VERSION ""

NS_ :

BS_:

BU_: PowertrainControlModule AtmosphericSensor SafetyRestraintSystem2 Aftertreatment_2_GasOutlet Aftertreatment_2_GasIntake DieselParticulateFilterControl Turbocharger SafetyRestraintSystem1 CabDisplay2 Aftertreatment_1_GasOutlet Aftertreatment_1_GasIntake OnBoardDataLogger OffBoardDiagnosticTool2 OffBoardDiagnosticTool1 FileServer ParkingBrakeController SeatController2 FanDriveController SteeringColumnUnit CommunicationUnitRadio CommunicationUnitSatellite CommunicationUnitCellular PropulsionBatteryCharger ChassisController2 ChassisController1 EngineValveControl AuxiliaryHeater2 AuxiliaryHeater1 ClutchUnit RampControl InformationSystem1 SuspensionSystemController2 OilSensor VehicleDynamicStability ExhaustEmissionController TransmissionDisplay2 TransmissionDisplay1 ClimateControl2 WaterPumpController RearAxleSteeringController LightingOperatorControl SeatController1 IgnitionController2 IgnitionController1 TirePressureController CabController2 CabController1 PneumaticSystemController SuspensionSystemController1 HydraulicPumpController EnduranceBrakingSystem RetarderExhaustEngine2 OnBoardDiagnosticUnit HeadwayController RetarderExhaustEngine1 CabDisplay1 ManagementComputer VirtualTerminal OffVehicleGateway PowerTakeOffFront HitchControl AuxiliaryValveControl BodyController TractorTrailerBridge1 StarterSystem ElectricalSystem VehicleSecurity VehicleNavigation AerodynamicControl ElectricalChargingSystem ClimateControl1 TripRecorder InstrumentCluster SuspensionDriveAxle2 SuspensionDriveAxle1 SuspensionSteerAxle SteeringController FuelSystem CruiseControl RetarderDriveline RetarderEngine BrakesDriveAxle2 BrakesDriveAxle1 BrakesSystemController BrakesSteerAxle AxleDrive2 AxleDrive1 AxleSteering PowerTakeOff ShiftConsoleSecondary ShiftConsolePrimary Transmission2 Transmission1 Engine2 Engine1

BO_ 2364544766 CCS: 8 Vector__XXX
 SG_ EngCyl24CombustionStatus : 46|2@1+ (1,0) [0|3] "" Vector__XXX
 SG_ EngCyl23CombustionStatus : 44|2@1+ (1,0) [0|3] "" Vector__XXX
 SG_ EngCyl22CombustionStatus : 42|2@1+ (1,0) [0|3] "" Vector__XXX
 SG_ EngCyl21CombustionStatus : 40|2@1+ (1,0) [0|3] "" Vector__XXX
 SG_ EngCyl20CombustionStatus : 38|2@1+ (1,0) [0|3] "" Vector__XXX
 SG_ EngCyl19CombustionStatus : 36|2@1+ (1,0) [0|3] "" Vector__XXX
 SG_ EngCyl18CombustionStatus : 34|2@1+ (1,0) [0|3] "" Vector__XXX
 SG_ EngCyl17CombustionStatus : 32|2@1+ (1,0) [0|3] "" Vector__XXX
 SG_ EngCyl16CombustionStatus : 30|2@1+ (1,0) [0|3] "" Vector__XXX
 SG_ EngCyl15CombustionStatus : 28|2@1+ (1,0) [0|3] "" Vector__XXX
 SG_ EngCyl14CombustionStatus : 26|2@1+ (1,0) [0|3] "" Vector__XXX
 SG_ EngCyl13CombustionStatus : 24|2@1+ (1,0) [0|3] "" Vector__XXX
 SG_ EngCyl12CombustionStatus : 22|2@1+ (1,0) [0|3] "" Vector__XXX
 SG_ EngCyl11CombustionStatus : 20|2@1+ (1,0) [0|3] "" Vector__XXX
 SG_ EngCyl10CombustionStatus : 18|2@1+ (1,0) [0|3] "" Vector__XXX
 SG_ EngCyl9CombustionStatus : 16|2@1+ (1,0) [0|3] "" Vector__XXX
 SG_ EngCyl8CombustionStatus : 14|2@1+ (1,0) [0|3] "" Vector__XXX
 SG_ EngCyl7CombustionStatus : 12|2@1+ (1,0) [0|3] "" Vector__XXX
 SG_ EngCyl6CombustionStatus : 10|2@1+ (1,0) [0|3] "" Vector__XXX
 SG_ EngCyl5CombustionStatus : 8|2@1+ (1,0) [0|3] "" Vector__XXX
 SG_ EngCyl4CombustionStatus : 6|2@1+ (1,0) [0|3] "" Vector__XXX
 SG_ EngCyl3CombustionStatus : 4|2@1+ (1,0) [0|3] "" Vector__XXX
 SG_ EngCyl2CombustionStatus : 2|2@1+ (1,0) [0|3] "" Vector__XXX
 SG_ EngCyl1CombustionStatus : 0|2@1+ (1,0) [0|3] "" Vector__XXX

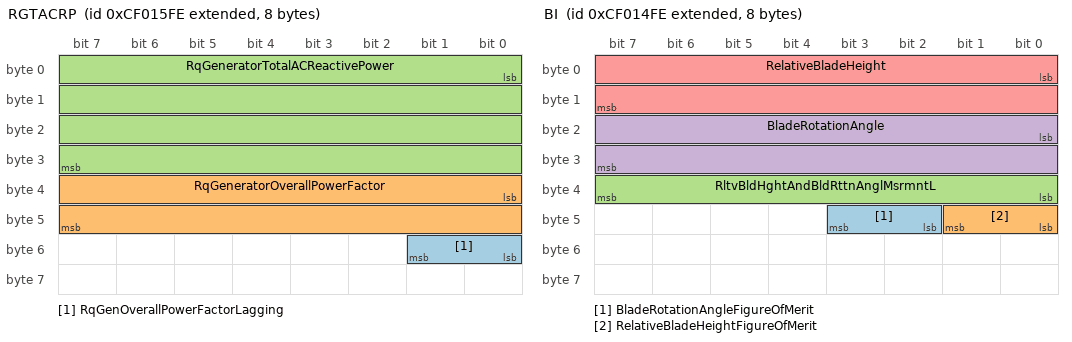
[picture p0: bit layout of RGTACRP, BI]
BO_ 2364544510 RGTACRP: 8 Vector__XXX
 SG_ RqGenOverallPowerFactorLagging : 48|2@1+ (1,0) [0|3] "" Vector__XXX
 SG_ RqGeneratorOverallPowerFactor : 32|16@1+ (6.103515625E-005,-1) [-1|1] "" Vector__XXX
 SG_ RqGeneratorTotalACReactivePower : 0|32@1+ (1,-2000000000) [-2000000000|2211081215] "VA" Vector__XXX

BO_ 2364544254 BI: 8 Vector__XXX
 SG_ BladeRotationAngleFigureOfMerit : 42|2@1+ (1,0) [0|3] "" Vector__XXX
 SG_ RelativeBladeHeightFigureOfMerit : 40|2@1+ (1,0) [0|3] "" Vector__XXX
 SG_ RltvBldHghtAndBldRttnAnglMsrmntL : 32|8@1+ (0.5,0) [0|125] "ms" Vector__XXX
 SG_ BladeRotationAngle : 16|16@1+ (0.0078125,-200) [-200|301.9921875] "deg" Vector__XXX
 SG_ RelativeBladeHeight : 0|16@1+ (0.1,-3200) [-3200|3225.5] "mm" Vector__XXX

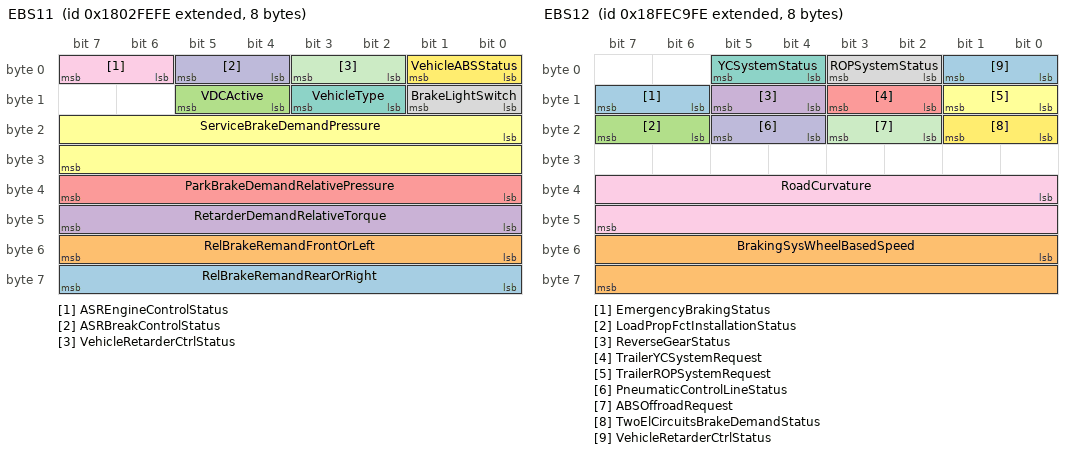
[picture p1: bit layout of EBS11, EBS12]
BO_ 2550333182 EBS11: 8 Vector__XXX
 SG_ RelBrakeRemandRearOrRight : 56|8@1+ (0.4,0) [0|100] "%" Vector__XXX
 SG_ RelBrakeRemandFrontOrLeft : 48|8@1+ (0.4,0) [0|100] "%" Vector__XXX
 SG_ VDCActive : 12|2@1+ (1,0) [0|3] "" Vector__XXX
 SG_ RetarderDemandRelativeTorque : 40|8@1+ (1,-125) [-125|125] "%" Vector__XXX
 SG_ ParkBrakeDemandRelativePressure : 32|8@1+ (0.4,0) [0|100] "%" Vector__XXX
 SG_ ServiceBrakeDemandPressure : 16|16@1+ (0.01953125,0) [0|1255] "kPa" Vector__XXX
 SG_ VehicleType : 10|2@1+ (1,0) [0|3] "" Vector__XXX
 SG_ BrakeLightSwitch : 8|2@1+ (1,0) [0|3] "" Vector__XXX
 SG_ ASREngineControlStatus : 6|2@1+ (1,0) [0|3] "" Vector__XXX
 SG_ ASRBreakControlStatus : 4|2@1+ (1,0) [0|3] "" Vector__XXX
 SG_ VehicleRetarderCtrlStatus : 2|2@1+ (1,0) [0|3] "" Vector__XXX
 SG_ VehicleABSStatus : 0|2@1+ (1,0) [0|1] "" Vector__XXX

BO_ 2566834686 EBS12: 8 Vector__XXX
 SG_ EmergencyBrakingStatus : 14|2@1+ (1,0) [0|3] "" Vector__XXX
 SG_ BrakingSysWheelBasedSpeed : 48|16@1+ (0.00390625,0) [0|250] "km/h" Vector__XXX
 SG_ LoadPropFctInstallationStatus : 22|2@1+ (1,0) [0|3] "" Vector__XXX
 SG_ ReverseGearStatus : 12|2@1+ (1,0) [0|3] "" Vector__XXX
 SG_ TrailerYCSystemRequest : 10|2@1+ (1,0) [0|3] "" Vector__XXX
 SG_ TrailerROPSystemRequest : 8|2@1+ (1,0) [0|3] "" Vector__XXX
 SG_ YCSystemStatus : 4|2@1+ (1,0) [0|3] "" Vector__XXX
 SG_ ROPSystemStatus : 2|2@1+ (1,0) [0|3] "" Vector__XXX
 SG_ RoadCurvature : 32|16@1+ (0.0078125,-250) [-250|251.9921875] "1/km" Vector__XXX
 SG_ PneumaticControlLineStatus : 20|2@1+ (1,0) [0|1] "" Vector__XXX
 SG_ ABSOffroadRequest : 18|2@1+ (1,0) [0|1] "" Vector__XXX
 SG_ TwoElCircuitsBrakeDemandStatus : 16|2@1+ (1,0) [0|1] "" Vector__XXX
 SG_ VehicleRetarderCtrlStatus : 0|2@1+ (1,0) [0|3] "" Vector__XXX

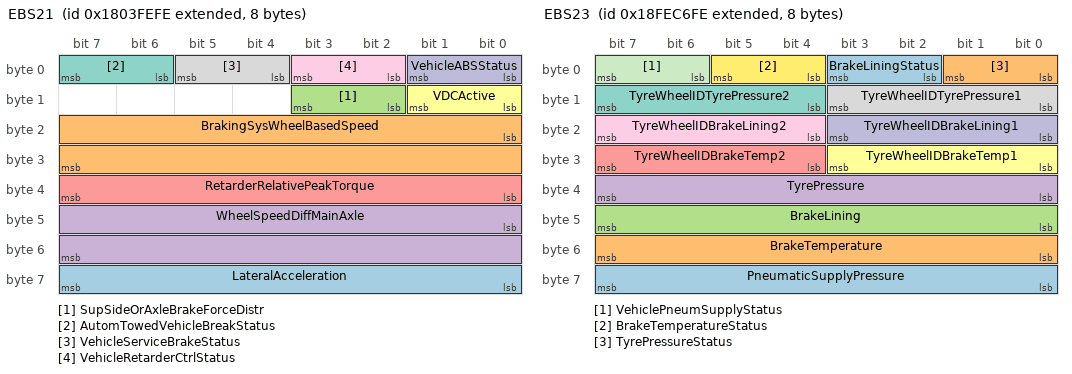
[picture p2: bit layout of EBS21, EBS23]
BO_ 2550398718 EBS21: 8 Vector__XXX
 SG_ LateralAcceleration : 56|8@1+ (0.1,-12.5) [-12.5|12.5] "m/s" Vector__XXX
 SG_ BrakingSysWheelBasedSpeed : 16|16@1+ (0.00390625,0) [0|250] "km/h" Vector__XXX
 SG_ SupSideOrAxleBrakeForceDistr : 10|2@1+ (1,0) [0|3] "" Vector__XXX
 SG_ WheelSpeedDiffMainAxle : 40|16@1+ (0.00390625,-125) [-125|125] "km/hr" Vector__XXX
 SG_ RetarderRelativePeakTorque : 32|8@1+ (1,-125) [-125|125] "%" Vector__XXX
 SG_ VDCActive : 8|2@1+ (1,0) [0|1] "" Vector__XXX
 SG_ AutomTowedVehicleBreakStatus : 6|2@1+ (1,0) [0|1] "" Vector__XXX
 SG_ VehicleServiceBrakeStatus : 4|2@1+ (1,0) [0|1] "" Vector__XXX
 SG_ VehicleRetarderCtrlStatus : 2|2@1+ (1,0) [0|3] "" Vector__XXX
 SG_ VehicleABSStatus : 0|2@1+ (1,0) [0|1] "" Vector__XXX

BO_ 2566833406 EBS22: 8 Vector__XXX
 SG_ BrakingViaElectrCtrlLineSupport : 30|2@1+ (1,0) [0|3] "" Vector__XXX
 SG_ StopLampsRequest : 28|2@1+ (1,0) [0|3] "" Vector__XXX
 SG_ ReferenceRetarderTorque : 48|16@1+ (1,0) [0|64255] "Nm" Vector__XXX
 SG_ AxleLoadSum : 32|16@1+ (2,0) [0|128510] "kg" Vector__XXX
 SG_ SupplyLineBraking : 26|2@1+ (1,0) [0|1] "" Vector__XXX
 SG_ LoadingRampApprAssistStatus : 24|2@1+ (1,0) [0|1] "" Vector__XXX
 SG_ SpringBrakeStatus : 22|2@1+ (1,0) [0|1] "" Vector__XXX
 SG_ ElectrLoadPropFuncInstalStatus : 18|2@1+ (1,0) [0|1] "" Vector__XXX
 SG_ SpringBrakeInstallationStatus : 16|2@1+ (1,0) [0|1] "" Vector__XXX
 SG_ VehicleType : 20|2@1+ (1,0) [0|3] "" Vector__XXX
 SG_ ElectSupplyOfNonBrakingSysStatus : 14|2@1+ (1,0) [0|1] "" Vector__XXX
 SG_ AmberWarningSignalReq : 12|2@1+ (1,0) [0|1] "" Vector__XXX
 SG_ RedWarningSignalRequest : 10|2@1+ (1,0) [0|1] "" Vector__XXX
 SG_ VehicleElectrSupplyStatus : 8|2@1+ (1,0) [0|1] "" Vector__XXX
 SG_ AutomTowedVehicleBreakStatus : 6|2@1+ (1,0) [0|1] "" Vector__XXX
 SG_ VehicleServiceBrakeStatus : 4|2@1+ (1,0) [0|1] "" Vector__XXX
 SG_ VehicleRetarderCtrlStatus : 2|2@1+ (1,0) [0|3] "" Vector__XXX
 SG_ VehicleABSStatus : 0|2@1+ (1,0) [0|1] "" Vector__XXX

BO_ 2566833918 EBS23: 8 Vector__XXX
 SG_ PneumaticSupplyPressure : 56|8@1+ (5,0) [0|1250] "kPa" Vector__XXX
 SG_ BrakeTemperature : 48|8@1+ (10,0) [0|2500] "°C" Vector__XXX
 SG_ BrakeLining : 40|8@1+ (0.4,0) [0|100] "%" Vector__XXX
 SG_ TyrePressure : 32|8@1+ (10,0) [0|2500] "kPa" Vector__XXX
 SG_ TyreWheelIDBrakeTemp2 : 28|4@1+ (1,0) [0|15] "" Vector__XXX
 SG_ TyreWheelIDBrakeTemp1 : 24|4@1+ (1,0) [0|15] "" Vector__XXX
 SG_ TyreWheelIDTyrePressure2 : 12|4@1+ (1,0) [0|15] "" Vector__XXX
 SG_ TyreWheelIDTyrePressure1 : 8|4@1+ (1,0) [0|15] "" Vector__XXX
 SG_ TyreWheelIDBrakeLining2 : 20|4@1+ (1,0) [0|15] "" Vector__XXX
 SG_ TyreWheelIDBrakeLining1 : 16|4@1+ (1,0) [0|15] "" Vector__XXX
 SG_ VehiclePneumSupplyStatus : 6|2@1+ (1,0) [0|1] "" Vector__XXX
 SG_ BrakeTemperatureStatus : 4|2@1+ (1,0) [0|1] "" Vector__XXX
 SG_ BrakeLiningStatus : 2|2@1+ (1,0) [0|1] "" Vector__XXX
 SG_ TyrePressureStatus : 0|2@1+ (1,0) [0|1] "" Vector__XXX

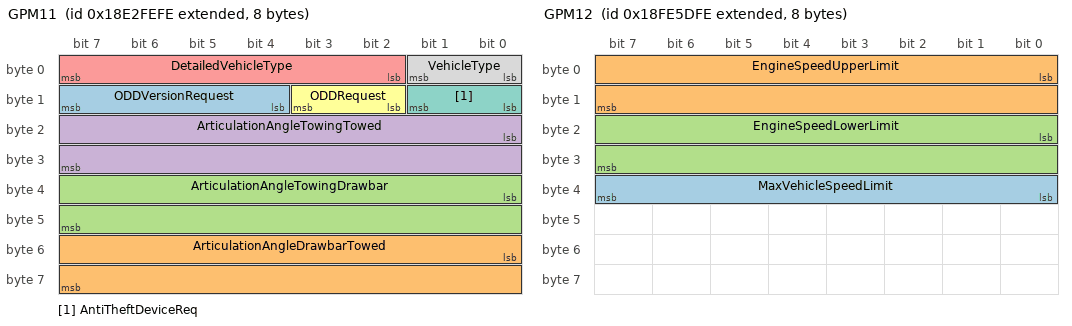
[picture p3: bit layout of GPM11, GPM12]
BO_ 2565013246 GPM11: 8 Vector__XXX
 SG_ ODDVersionRequest : 12|4@1+ (1,0) [0|15] "" Vector__XXX
 SG_ ArticulationAngleDrawbarTowed : 48|16@1+ (0.00390625,-125) [-125|125] "°" Vector__XXX
 SG_ ArticulationAngleTowingDrawbar : 32|16@1+ (0.00390625,-125) [-125|125] "°" Vector__XXX
 SG_ ArticulationAngleTowingTowed : 16|16@1+ (0.00390625,-125) [-125|125] "°" Vector__XXX
 SG_ DetailedVehicleType : 2|6@1+ (1,0) [0|63] "" Vector__XXX
 SG_ ODDRequest : 10|2@1+ (1,0) [0|3] "" Vector__XXX
 SG_ AntiTheftDeviceReq : 8|2@1+ (1,0) [0|3] "" Vector__XXX
 SG_ VehicleType : 0|2@1+ (1,0) [0|3] "" Vector__XXX

BO_ 2566807038 GPM12: 8 Vector__XXX
 SG_ MaxVehicleSpeedLimit : 32|8@1+ (1,0) [0|250] "km/h" Vector__XXX
 SG_ EngineSpeedUpperLimit : 0|16@1+ (0.125,0) [0|8031.875] "rpm" Vector__XXX
 SG_ EngineSpeedLowerLimit : 16|16@1+ (0.125,0) [0|8191.875] "rpm" Vector__XXX

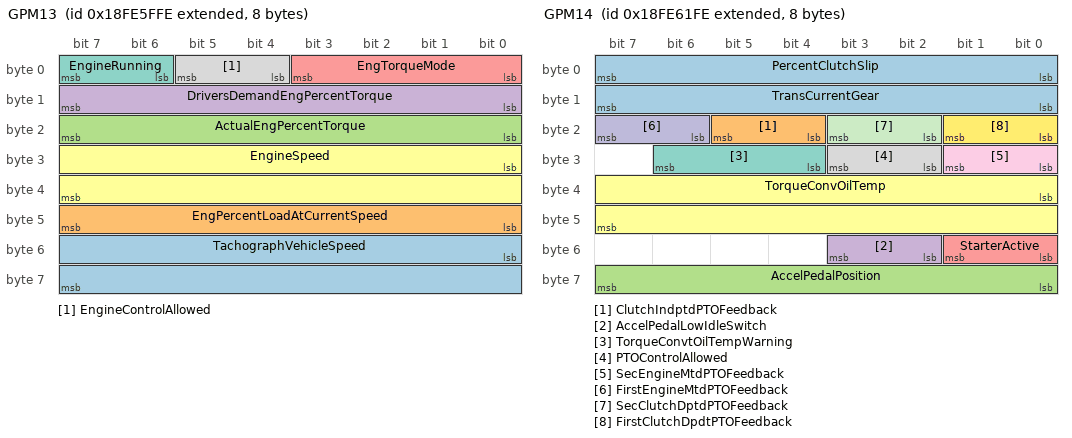
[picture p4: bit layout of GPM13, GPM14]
BO_ 2566807550 GPM13: 8 Vector__XXX
 SG_ TachographVehicleSpeed : 48|16@1+ (0.00390625,0) [0|250.99609375] "km/h" Vector__XXX
 SG_ EngPercentLoadAtCurrentSpeed : 40|8@1+ (1,0) [0|125] "%" Vector__XXX
 SG_ ActualEngPercentTorque : 16|8@1+ (1,-125) [0|125] "%" Vector__XXX
 SG_ DriversDemandEngPercentTorque : 8|8@1+ (1,-125) [0|125] "%" Vector__XXX
 SG_ EngTorqueMode : 0|4@1+ (1,0) [0|15] "" Vector__XXX
 SG_ EngineSpeed : 24|16@1+ (0.125,0) [0|8031.88] "rpm" Vector__XXX
 SG_ EngineRunning : 6|2@1+ (1,0) [0|1] "" Vector__XXX
 SG_ EngineControlAllowed : 4|2@1+ (1,0) [0|1] "" Vector__XXX

BO_ 2566808062 GPM14: 8 Vector__XXX
 SG_ TransCurrentGear : 8|8@1+ (1,-125) [-125|125] "" Vector__XXX
 SG_ ClutchIndptdPTOFeedback : 20|2@1+ (1,0) [0|1] "" Vector__XXX
 SG_ AccelPedalPosition : 56|8@1+ (0.4,0) [0|100] "%" Vector__XXX
 SG_ AccelPedalLowIdleSwitch : 50|2@1+ (1,0) [0|1] "" Vector__XXX
 SG_ StarterActive : 48|2@1+ (1,0) [0|1] "" Vector__XXX
 SG_ TorqueConvOilTemp : 32|16@1+ (0.03125,-273) [-273|1735] "°C" Vector__XXX
 SG_ TorqueConvtOilTempWarning : 28|3@1+ (1,0) [0|2] "" Vector__XXX
 SG_ PTOControlAllowed : 26|2@1+ (1,0) [0|1] "" Vector__XXX
 SG_ SecEngineMtdPTOFeedback : 24|2@1+ (1,0) [0|1] "" Vector__XXX
 SG_ FirstEngineMtdPTOFeedback : 22|2@1+ (1,0) [0|1] "" Vector__XXX
 SG_ SecClutchDptdPTOFeedback : 18|2@1+ (1,0) [0|1] "" Vector__XXX
 SG_ FirstClutchDpdtPTOFeedback : 16|2@1+ (1,0) [0|1] "" Vector__XXX
 SG_ PercentClutchSlip : 0|8@1+ (0.4,0) [0|100] "%" Vector__XXX

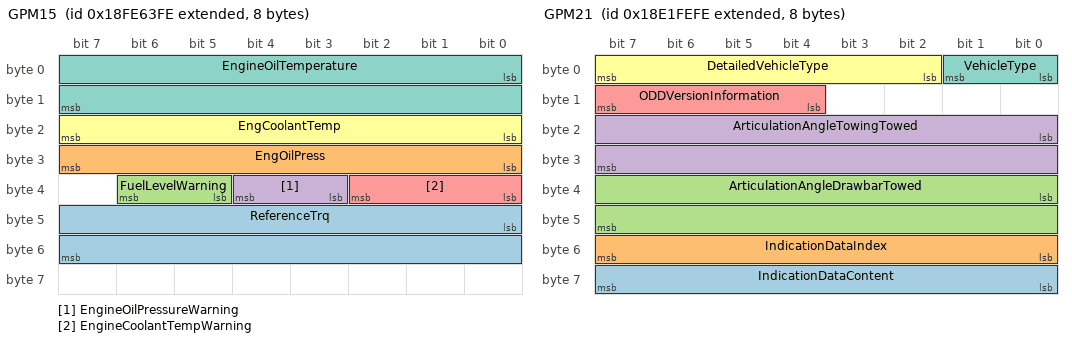
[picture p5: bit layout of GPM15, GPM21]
BO_ 2566808574 GPM15: 8 Vector__XXX
 SG_ ReferenceTrq : 40|16@1+ (1,0) [0|64255] "Nm" Vector__XXX
 SG_ EngOilPress : 24|8@1+ (4,0) [0|1000] "kPa" Vector__XXX
 SG_ FuelLevelWarning : 37|2@1+ (1,0) [0|1] "" Vector__XXX
 SG_ EngineOilPressureWarning : 35|2@1+ (1,0) [0|1] "" Vector__XXX
 SG_ EngineCoolantTempWarning : 32|3@1+ (1,0) [0|2] "" Vector__XXX
 SG_ EngCoolantTemp : 16|8@1+ (1,-40) [-40|210] "°C" Vector__XXX
 SG_ EngineOilTemperature : 0|16@1+ (0.03125,-273) [-273|1735] "°C" Vector__XXX

BO_ 2566809086 GPM16: 8 Vector__XXX
 SG_ AmbientAirTemp : 0|16@1+ (0.03125,-273) [-273|1734.96875] "°C" Vector__XXX

BO_ 2564947710 GPM21: 8 Vector__XXX
 SG_ IndicationDataContent : 56|8@1+ (1,0) [0|1] "" Vector__XXX
 SG_ IndicationDataIndex : 48|8@1+ (1,0) [0|16] "" Vector__XXX
 SG_ ArticulationAngleDrawbarTowed : 32|16@1+ (0.00390625,-125) [-125|125] "°" Vector__XXX
 SG_ ArticulationAngleTowingTowed : 16|16@1+ (0.00390625,-125) [-125|125] "°" Vector__XXX
 SG_ ODDVersionInformation : 12|4@1+ (1,0) [0|15] "" Vector__XXX
 SG_ DetailedVehicleType : 2|6@1+ (1,0) [0|63] "" Vector__XXX
 SG_ VehicleType : 0|2@1+ (1,0) [0|3] "" Vector__XXX

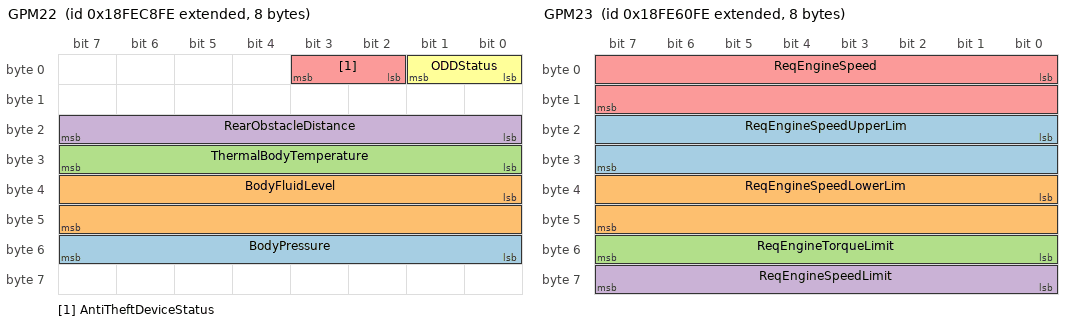
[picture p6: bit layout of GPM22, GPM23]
BO_ 2566834430 GPM22: 8 Vector__XXX
 SG_ BodyPressure : 48|8@1+ (10,0) [0|2500] "kPa" Vector__XXX
 SG_ BodyFluidLevel : 32|16@1+ (2,0) [0|128510] "L" Vector__XXX
 SG_ ThermalBodyTemperature : 24|8@1+ (1,-125) [-125|125] "°C" Vector__XXX
 SG_ RearObstacleDistance : 16|8@1+ (2,0) [0|500] "cm" Vector__XXX
 SG_ AntiTheftDeviceStatus : 2|2@1+ (1,0) [0|1] "" Vector__XXX
 SG_ ODDStatus : 0|2@1+ (1,0) [0|1] "" Vector__XXX

BO_ 2566807806 GPM23: 8 Vector__XXX
 SG_ ReqEngineSpeedUpperLim : 16|16@1+ (0.125,0) [0|8031.875] "rpm" Vector__XXX
 SG_ ReqEngineSpeedLowerLim : 32|16@1+ (0.125,0) [0|8031.875] "rpm" Vector__XXX
 SG_ ReqEngineTorqueLimit : 48|8@1+ (1,-125) [-125|125] "%" Vector__XXX
 SG_ ReqEngineSpeedLimit : 56|8@1+ (1,0) [0|250] "km/h" Vector__XXX
 SG_ ReqEngineSpeed : 0|16@1+ (0.125,0) [0|8031.875] "rpm" Vector__XXX

BO_ 2566808318 GPM24: 8 Vector__XXX
 SG_ TransfCaseOutShaftPTOEngmtConsTr : 48|2@1+ (1,0) [0|3] "" Vector__XXX
 SG_ FirstTransOutShaftPTOEngmtConsTr : 46|2@1+ (1,0) [0|3] "" Vector__XXX
 SG_ SecEngineMntPTOEngagemtConsTr : 44|2@1+ (1,0) [0|3] "" Vector__XXX
 SG_ FirstEngineMntPTOEngagemtConsTr : 42|2@1+ (1,0) [0|3] "" Vector__XXX
 SG_ ClutchIndpdtPTOEngagemtConsTr : 40|2@1+ (1,0) [0|3] "" Vector__XXX
 SG_ SecClutchDpdtPTOEngagemtConsTr : 38|2@1+ (1,0) [0|3] "" Vector__XXX
 SG_ FirstClutchDpdtPTOEngagemtConsTr : 36|2@1+ (1,0) [0|3] "" Vector__XXX
 SG_ TransferCaseOutputShaftPTOSwitch : 34|2@1+ (1,0) [0|3] "" Vector__XXX
 SG_ TransmissionOutputShaftPTOSwitch : 32|2@1+ (1,0) [0|3] "" Vector__XXX
 SG_ SecEngineMtdPTOSwitch : 30|2@1+ (1,0) [0|1] "" Vector__XXX
 SG_ SecClutchDpdtPTOSwitch : 24|2@1+ (1,0) [0|1] "" Vector__XXX
 SG_ FirstClutchDpdtPTOSwitch : 22|2@1+ (1,0) [0|1] "" Vector__XXX
 SG_ OperatingPanelActive : 18|2@1+ (1,0) [0|1] "" Vector__XXX
 SG_ RefusePackerStepSwitch : 16|2@1+ (1,0) [0|1] "" Vector__XXX
 SG_ EngineStopSwitch : 12|2@1+ (1,0) [0|1] "" Vector__XXX
 SG_ EngineStartSwitch : 10|2@1+ (1,0) [0|3] "" Vector__XXX
 SG_ StarterLockoutSwitch : 8|2@1+ (1,0) [0|1] "" Vector__XXX
 SG_ RqstedPercentClutchSlip : 0|8@1+ (0.4,0) [0|100] "%" Vector__XXX
 SG_ FirstEngineMtdPTOSwitch : 28|2@1+ (1,0) [0|1] "" Vector__XXX
 SG_ ClutchIndpdtPTOSwitch : 26|2@1+ (1,0) [0|1] "" Vector__XXX

BO_ 2566808830 GPM25: 8 Vector__XXX
 SG_ TrailerRightReversLightRedundFct : 58|2@1+ (1,0) [0|3] "" Vector__XXX
 SG_ TrailerLeftReversLightRedundFct : 56|2@1+ (1,0) [0|3] "" Vector__XXX
 SG_ TrailerRightRearLightRedundFct : 54|2@1+ (1,0) [0|3] "" Vector__XXX
 SG_ TrailerLeftRearLightRedundFct : 52|2@1+ (1,0) [0|3] "" Vector__XXX
 SG_ TrailerRightDirIndLightRedundFct : 50|2@1+ (1,0) [0|3] "" Vector__XXX
 SG_ TrailerLeftDirIndLightRedundFct : 48|2@1+ (1,0) [0|3] "" Vector__XXX
 SG_ TrailerRightStopLightRedundFct : 46|2@1+ (1,0) [0|3] "" Vector__XXX
 SG_ TrailerLeftStopLightRedundFct : 44|2@1+ (1,0) [0|3] "" Vector__XXX
 SG_ TowedVehicleLeftSideMarkerLight : 20|2@1+ (1,0) [0|3] "" Vector__XXX
 SG_ TowedVehicleLeftReversingLight : 16|2@1+ (1,0) [0|3] "" Vector__XXX
 SG_ TowedVehicleLeftRearWidIndLight : 24|2@1+ (1,0) [0|3] "" Vector__XXX
 SG_ TowedVehicleLeftRearRegPltLight : 32|2@1+ (1,0) [0|3] "" Vector__XXX
 SG_ TowedVehicleLeftRearLight : 8|2@1+ (1,0) [0|3] "" Vector__XXX
 SG_ TowedVehicleLeftRearFogLight : 12|2@1+ (1,0) [0|3] "" Vector__XXX
 SG_ TowedVehicleLeftDirIndLight : 4|2@1+ (1,0) [0|3] "" Vector__XXX
 SG_ TowedVehicleLeftCrnMarkerLight : 28|2@1+ (1,0) [0|3] "" Vector__XXX
 SG_ TowedVehicleInteriorLight : 40|2@1+ (1,0) [0|3] "" Vector__XXX
 SG_ TowedVehicleWorkLight : 42|2@1+ (1,0) [0|3] "" Vector__XXX
 SG_ TowedVehicleRotatingIdentLight : 38|2@1+ (1,0) [0|3] "" Vector__XXX
 SG_ TowedVehicleRightStopLight : 2|2@1+ (1,0) [0|3] "" Vector__XXX
 SG_ TowedVehicleRightSideMrkLight : 22|2@1+ (1,0) [0|3] "" Vector__XXX
 SG_ TowedVehicleRightReversingLight : 18|2@1+ (1,0) [0|3] "" Vector__XXX
 SG_ TowedVehicleRearWidIndLight : 26|2@1+ (1,0) [0|3] "" Vector__XXX
 SG_ TowedVehicleRightRearRegPltLight : 34|2@1+ (1,0) [0|3] "" Vector__XXX
 SG_ TowedVehicleRightRearLight : 10|2@1+ (1,0) [0|3] "" Vector__XXX
 SG_ TowedVehicleRightRearFogLight : 14|2@1+ (1,0) [0|3] "" Vector__XXX
 SG_ TowedVehicleRightDirIndLight : 6|2@1+ (1,0) [0|3] "" Vector__XXX
 SG_ TowedVehicleRightCrnMarkerLight : 30|2@1+ (1,0) [0|3] "" Vector__XXX
 SG_ TowedVehicleRearWarningLight : 36|2@1+ (1,0) [0|3] "" Vector__XXX
 SG_ TowedVehicleLeftStopLight : 0|2@1+ (1,0) [0|3] "" Vector__XXX

BO_ 2564554494 KWP1: 8 Vector__XXX
 SG_ SN m2 : 0|4@1+ (1,0) [0|15] "" Vector__XXX
 SG_ SeparationTime m3 : 16|8@1+ (1,0) [0|255] "ms" Vector__XXX
 SG_ BlockSize m3 : 8|8@1+ (1,0) [0|255] "" Vector__XXX
 SG_ FlowStatus m3 : 0|4@1+ (1,0) [0|3] "" Vector__XXX
 SG_ FirstFrameDataLength m1 : 3|12@0+ (1,0) [0|4095] "Byte" Vector__XXX
 SG_ SingleFrameDataLength m0 : 0|4@1+ (1,0) [0|7] "Byte" Vector__XXX
 SG_ ProtocolCtrlInformation M : 4|4@1+ (1,0) [0|3] "" Vector__XXX

BO_ 2564488958 KWP2: 8 Vector__XXX
 SG_ SN m2 : 0|4@1+ (1,0) [0|15] "" Vector__XXX
 SG_ SeparationTime m3 : 16|8@1+ (1,0) [0|255] "ms" Vector__XXX
 SG_ BlockSize m3 : 8|8@1+ (1,0) [0|255] "" Vector__XXX
 SG_ FlowStatus m3 : 0|4@1+ (1,0) [0|3] "" Vector__XXX
 SG_ FirstFrameDataLength m1 : 3|12@0+ (1,0) [0|4095] "Byte" Vector__XXX
 SG_ SingleFrameDataLength m0 : 0|4@1+ (1,0) [0|7] "Byte" Vector__XXX
 SG_ ProtocolCtrlInformation M : 4|4@1+ (1,0) [0|3] "" Vector__XXX

BO_ 2565734142 Nxx: 8 Vector__XXX
 SG_ NumberOfSA_NAMEPairs m67 : 16|8@1+ (1,0) [0|0] "" Vector__XXX
 SG_ ToPort m0 : 8|4@1+ (1,0) [0|15] "" Vector__XXX
 SG_ NetworkMessageControlByte M : 0|8@1+ (1,0) [0|255] "" Vector__XXX
 SG_ FilterMode m1 : 16|8@1+ (1,0) [0|255] "" Vector__XXX
 SG_ NIECUPort m64 : 8|4@1+ (1,0) [0|15] "" Vector__XXX
 SG_ FromPort m0 : 12|4@1+ (1,0) [0|15] "" Vector__XXX

BO_ 2565144318 RGE11: 8 Vector__XXX
 SG_ RideHeightAndRampLevelSetRequest : 62|2@1+ (1,0) [0|3] "" Vector__XXX
 SG_ LiftAxle5PositionReq : 60|2@1+ (1,0) [0|3] "" Vector__XXX
 SG_ LiftAxle4PositionReq : 58|2@1+ (1,0) [0|3] "" Vector__XXX
 SG_ LiftAxle3PositionReq : 56|2@1+ (1,0) [0|3] "" Vector__XXX
 SG_ RideHeightStorageRequest : 22|2@1+ (1,0) [0|3] "" Vector__XXX
 SG_ ParkingAndTrailerAirPress : 40|8@1+ (8,0) [0|2000] "kPa" Vector__XXX
 SG_ DrivenAxleLoad : 24|16@1+ (2,0) [0|128510] "kg" Vector__XXX
 SG_ AuxEquipSupplyPressure : 48|8@1+ (8,0) [0|2000] "kPa" Vector__XXX
 SG_ StopLevelChangeReq : 20|2@1+ (1,0) [0|3] "" Vector__XXX
 SG_ RampLevelStorageReq : 18|2@1+ (1,0) [0|3] "" Vector__XXX
 SG_ LevelControlReq : 16|2@1+ (1,0) [0|3] "" Vector__XXX
 SG_ RampLevelReq : 14|2@1+ (1,0) [0|3] "" Vector__XXX
 SG_ SteeringAxleLockingReq : 12|2@1+ (1,0) [0|3] "" Vector__XXX
 SG_ LiftAxle2PositionReq : 10|2@1+ (1,0) [0|3] "" Vector__XXX
 SG_ LiftAxle1PositionReq : 8|2@1+ (1,0) [0|3] "" Vector__XXX
 SG_ TractionHelpReq : 6|2@1+ (1,0) [0|3] "" Vector__XXX
 SG_ LevelChangeReqRearAxle : 4|2@1+ (1,0) [0|3] "" Vector__XXX
 SG_ LevelChangeReqFrontAxle : 2|2@1+ (1,0) [0|3] "" Vector__XXX
 SG_ RideHeightRequest : 0|2@1+ (1,0) [0|3] "" Vector__XXX

BO_ 2565209854 RGE21: 8 Vector__XXX
 SG_ ExtRideHeightAndRampLevelStorage : 30|2@1+ (1,0) [0|3] "" Vector__XXX
 SG_ RideHeightStorage : 16|2@1- (1,0) [0|3] "" Vector__XXX
 SG_ LevelControl : 2|2@1+ (1,0) [0|1] "" Vector__XXX
 SG_ NominalVehBodyLevelRearAxle : 48|16@1+ (1,0) [0|64255] "mm" Vector__XXX
 SG_ NominalVehBodyLevelFrontAxle : 32|16@1+ (1,0) [0|64255] "mm" Vector__XXX
 SG_ RampLevel : 28|2@1+ (1,0) [0|1] "" Vector__XXX
 SG_ NormalLevel : 26|2@1+ (1,0) [0|3] "" Vector__XXX
 SG_ StopLevelChangeAcknowledge : 24|2@1+ (1,0) [0|1] "" Vector__XXX
 SG_ LevelChangeRearAxle : 22|2@1+ (1,0) [0|1] "" Vector__XXX
 SG_ LevelChangeFrontAxle : 20|2@1+ (1,0) [0|1] "" Vector__XXX
 SG_ RampLevelStorage : 18|2@1+ (1,0) [0|1] "" Vector__XXX
 SG_ SteeringAxleLockingStatus : 12|2@1+ (1,0) [0|3] "" Vector__XXX
 SG_ LiftAxle2Pos : 10|2@1+ (1,0) [0|3] "" Vector__XXX
 SG_ LiftAxle1Pos : 8|2@1+ (1,0) [0|3] "" Vector__XXX
 SG_ RampLevelPosition : 6|2@1+ (1,0) [0|3] "" Vector__XXX
 SG_ TractionHelpStatus : 4|2@1+ (1,0) [0|1] "" Vector__XXX
 SG_ RideHeightLevel : 0|2@1+ (1,0) [0|1] "" Vector__XXX

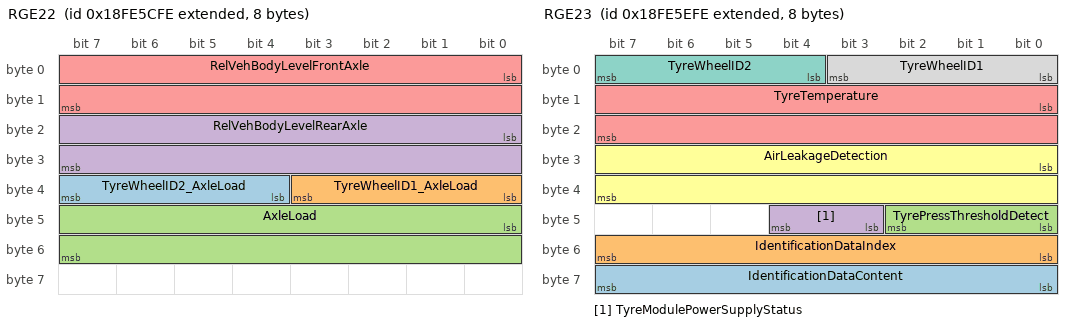
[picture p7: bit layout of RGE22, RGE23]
BO_ 2566806782 RGE22: 8 Vector__XXX
 SG_ TyreWheelID2_AxleLoad : 36|4@1+ (1,0) [0|15] "" Vector__XXX
 SG_ TyreWheelID1_AxleLoad : 32|4@1+ (1,0) [0|15] "" Vector__XXX
 SG_ AxleLoad : 40|16@1+ (0.5,0) [0|32127.5] "kg" Vector__XXX
 SG_ RelVehBodyLevelRearAxle : 16|16@1+ (1,0) [0|64255] "mm" Vector__XXX
 SG_ RelVehBodyLevelFrontAxle : 0|16@1+ (1,-32000) [-32000|32255] "mm" Vector__XXX

BO_ 2566807294 RGE23: 8 Vector__XXX
 SG_ IdentificationDataContent : 56|8@1- (1,0) [0|250] "" Vector__XXX
 SG_ IdentificationDataIndex : 48|8@1- (1,0) [0|250] "" Vector__XXX
 SG_ TyrePressThresholdDetect : 40|3@1+ (1,0) [0|7] "" Vector__XXX
 SG_ TyreModulePowerSupplyStatus : 43|2@1+ (1,0) [0|1] "" Vector__XXX
 SG_ TyreTemperature : 8|16@1+ (0.03125,-273) [-273|1735] "°C" Vector__XXX
 SG_ AirLeakageDetection : 24|16@1+ (0.1,0) [0|6425.5] "Pa/s" Vector__XXX
 SG_ TyreWheelID2 : 4|4@1+ (1,0) [0|15] "" Vector__XXX
 SG_ TyreWheelID1 : 0|4@1+ (1,0) [0|15] "" Vector__XXX

BO_ 2566764798 DM26: 8 Vector__XXX
 SG_ NMHCConvertingCatalystCompleted : 60|1@1+ (1,0) [0|1] "" Vector__XXX
 SG_ NMHCConvertingCatalystEnabled : 44|1@1+ (1,0) [0|1] "" Vector__XXX
 SG_ NOxConvertingCatalstAdsrbrCmpltd : 59|1@1+ (1,0) [0|1] "" Vector__XXX
 SG_ NOxConvertingCatalystAdsorberEna : 43|1@1+ (1,0) [0|1] "" Vector__XXX
 SG_ DieselParticulateFilterCompleted : 58|1@1+ (1,0) [0|1] "" Vector__XXX
 SG_ DieselParticulateFilterEnabled : 42|1@1+ (1,0) [0|1] "" Vector__XXX
 SG_ BoostPressureControlSystemComple : 57|1@1+ (1,0) [0|1] "" Vector__XXX
 SG_ BoostPressureControlSystemEnable : 41|1@1- (1,0) [0|0] "" Vector__XXX
 SG_ MisfireMonitoringComplete : 28|1@1+ (1,0) [0|1] "" Vector__XXX
 SG_ MisfireMonitoringEnabled : 24|1@1+ (1,0) [0|0] "" Vector__XXX
 SG_ FuelSystemMonitoringEnabled : 25|1@1+ (1,0) [0|1] "" Vector__XXX
 SG_ ComprehensiveComptMonComplete : 30|1@1+ (1,0) [0|1] "" Vector__XXX
 SG_ ComprehensiveCompMonEnabled : 26|1@1+ (1,0) [0|1] "" Vector__XXX
 SG_ SecondAirSystemMonComplete : 51|1@1+ (1,0) [0|1] "" Vector__XXX
 SG_ SecondAirSystemMonEnabled : 35|1@1+ (1,0) [0|1] "" Vector__XXX
 SG_ OxygenSensorMonComplete : 53|1@1+ (1,0) [0|1] "" Vector__XXX
 SG_ OxygenSensorMonEnabled : 37|1@1+ (1,0) [0|1] "" Vector__XXX
 SG_ OxygenSensorHeaterMonComplete : 54|1@1+ (1,0) [0|1] "" Vector__XXX
 SG_ OxygenSensorHeaterMonEnabled : 38|1@1+ (1,0) [0|1] "" Vector__XXX
 SG_ HeatedCatalystMonComplete : 49|1@1+ (1,0) [0|1] "" Vector__XXX
 SG_ HeatedCatalystMonEnabled : 33|1@1+ (1,0) [0|1] "" Vector__XXX
 SG_ EvaporativeSystemMonComplete : 50|1@1+ (1,0) [0|1] "" Vector__XXX
 SG_ EvaporativeSystemMonEnabled : 34|1@1+ (1,0) [0|1] "" Vector__XXX
 SG_ EGRSystemMonitoringComplete : 55|1@1+ (1,0) [0|1] "" Vector__XXX
 SG_ EGRSystemMonitoringEnabled : 39|1@1+ (1,0) [0|1] "" Vector__XXX
 SG_ ColdStartAidSystemMonComplete : 56|1@1+ (1,0) [0|1] "" Vector__XXX
 SG_ ColdStartAidSystemMonEnabled : 40|1@1+ (1,0) [0|1] "" Vector__XXX
 SG_ CatalystMonComplete : 48|1@1+ (1,0) [0|1] "" Vector__XXX
 SG_ CatalystMonEnabled : 32|1@1+ (1,0) [0|1] "" Vector__XXX
 SG_ ACSystemRefrigerantMonComplete : 52|1@1+ (1,0) [0|1] "" Vector__XXX
 SG_ ACSystemRefrigerantMonEnabled : 36|1@1+ (1,0) [0|1] "" Vector__XXX
 SG_ FuelSystemMonitoringComplete : 29|1@1+ (1,0) [0|1] "" Vector__XXX
 SG_ NumOfWarmUpsSinceDTCsCleared : 16|8@1+ (1,0) [0|250] "" Vector__XXX
 SG_ TimeSinceEngineStart : 0|16@1+ (1,0) [0|64255] "s" Vector__XXX

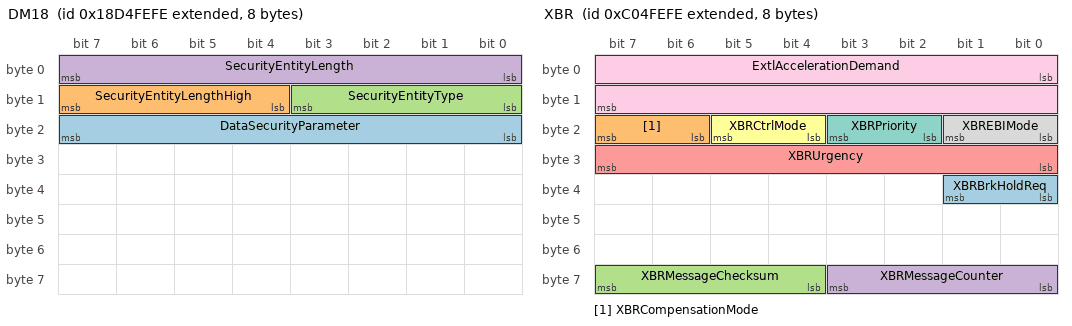
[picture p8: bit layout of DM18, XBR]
BO_ 2564095742 DM18: 8 Vector__XXX
 SG_ DataSecurityParameter : 16|8@1+ (1,0) [0|0] "" Vector__XXX
 SG_ SecurityEntityLengthHigh : 12|4@1+ (1,0) [0|255] "Byte" Vector__XXX
 SG_ SecurityEntityType : 8|4@1+ (1,0) [0|15] "" Vector__XXX
 SG_ SecurityEntityLength : 0|8@1+ (1,0) [0|4095] "" Vector__XXX

BO_ 2349137662 XBR: 8 Vector__XXX
 SG_ XBRBrkHoldReq : 32|2@1+ (1,0) [0|3] "" Vector__XXX
 SG_ XBRCompensationMode : 22|2@1+ (1,0) [0|3] "" Vector__XXX
 SG_ XBRMessageChecksum : 60|4@1+ (1,0) [0|15] "" Vector__XXX
 SG_ XBRMessageCounter : 56|4@1+ (1,0) [0|15] "" Vector__XXX
 SG_ XBRUrgency : 24|8@1+ (0.4,0) [0|100] "%" Vector__XXX
 SG_ XBRCtrlMode : 20|2@1+ (1,0) [0|3] "" Vector__XXX
 SG_ XBRPriority : 18|2@1+ (1,0) [0|3] "" Vector__XXX
 SG_ XBREBIMode : 16|2@1+ (1,0) [0|3] "" Vector__XXX
 SG_ ExtlAccelerationDemand : 0|16@1+ (0.00048828125,-15.687) [-10|10] "m/s²" Vector__XXX

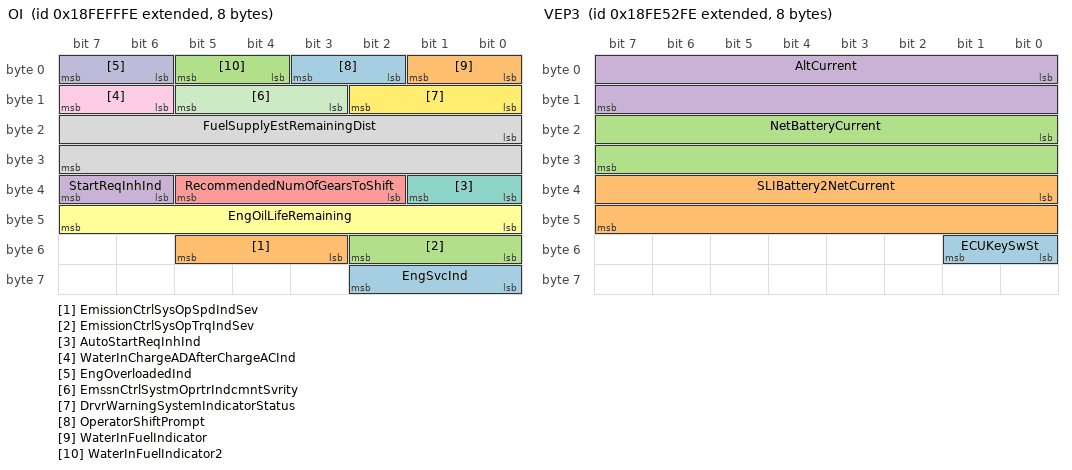
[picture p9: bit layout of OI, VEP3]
BO_ 2566848510 OI: 8 Vector__XXX
 SG_ EngSvcInd : 56|3@1+ (1,0) [0|7] "" Vector__XXX
 SG_ EmissionCtrlSysOpSpdIndSev : 51|3@1+ (1,0) [0|7] "" Vector__XXX
 SG_ EmissionCtrlSysOpTrqIndSev : 48|3@1+ (1,0) [0|7] "" Vector__XXX
 SG_ StartReqInhInd : 38|2@1+ (1,0) [0|3] "" Vector__XXX
 SG_ RecommendedNumOfGearsToShift : 34|4@1+ (1,0) [0|13] "" Vector__XXX
 SG_ EngOilLifeRemaining : 40|8@1+ (0.4,0) [0|100] "%" Vector__XXX
 SG_ AutoStartReqInhInd : 32|2@1+ (1,0) [0|3] "" Vector__XXX
 SG_ FuelSupplyEstRemainingDist : 16|16@1+ (1,0) [0|64255] "km" Vector__XXX
 SG_ WaterInChargeADAfterChargeACInd : 14|2@1+ (1,0) [0|3] "" Vector__XXX
 SG_ EngOverloadedInd : 6|2@1+ (1,0) [0|3] "" Vector__XXX
 SG_ EmssnCtrlSystmOprtrIndcmntSvrity : 11|3@1+ (1,0) [0|7] "" Vector__XXX
 SG_ DrvrWarningSystemIndicatorStatus : 8|3@1+ (1,0) [0|7] "" Vector__XXX
 SG_ OperatorShiftPrompt : 2|2@1+ (1,0) [0|3] "" Vector__XXX
 SG_ WaterInFuelIndicator : 0|2@1+ (1,0) [0|3] "" Vector__XXX
 SG_ WaterInFuelIndicator2 : 4|2@1+ (1,0) [0|3] "" Vector__XXX

BO_ 2566843134 VW: 8 Vector__XXX
 SG_ AxleLocation M : 0|8@1+ (1,0) [0|255] "" Vector__XXX
 SG_ CargoWeight_30 m48 : 40|16@1+ (2,0) [0|128510] "kg" Vector__XXX
 SG_ CargoWeight_20 m32 : 40|16@1+ (2,0) [0|128510] "kg" Vector__XXX
 SG_ CargoWeight_10 m16 : 40|16@1+ (2,0) [0|128510] "kg" Vector__XXX
 SG_ CargoWeight_00 m0 : 40|16@1+ (2,0) [0|128510] "kg" Vector__XXX
 SG_ TrailerWeight_30 m48 : 24|16@1+ (2,0) [0|128510] "kg" Vector__XXX
 SG_ TrailerWeight_20 m32 : 24|16@1+ (2,0) [0|128510] "kg" Vector__XXX
 SG_ TrailerWeight_10 m16 : 24|16@1+ (2,0) [0|128510] "kg" Vector__XXX
 SG_ TrailerWeight_00 m0 : 24|16@1+ (2,0) [0|128510] "kg" Vector__XXX
 SG_ AxleWeight_30 m48 : 8|16@1+ (0.5,0) [0|32127.5] "kg" Vector__XXX
 SG_ AxleWeight_20 m32 : 8|16@1+ (0.5,0) [0|32127.5] "kg" Vector__XXX
 SG_ AxleWeight_10 m16 : 8|16@1+ (0.5,0) [0|32127.5] "kg" Vector__XXX
 SG_ AxleWeight_00 m0 : 8|16@1+ (0.5,0) [0|32127.5] "kg" Vector__XXX

BO_ 2566804222 VEP3: 8 Vector__XXX
 SG_ ECUKeySwSt : 48|2@1+ (1,0) [0|3] "" Vector__XXX
 SG_ SLIBattery2NetCurrent : 32|16@1+ (0.05,-1600) [-1600|1612.75] "A" Vector__XXX
 SG_ NetBatteryCurrent : 16|16@1+ (0.05,-1600) [-1600|1612.75] "A" Vector__XXX
 SG_ AltCurrent : 0|16@1+ (0.05,-1600) [-1600|1612.75] "A" Vector__XXX

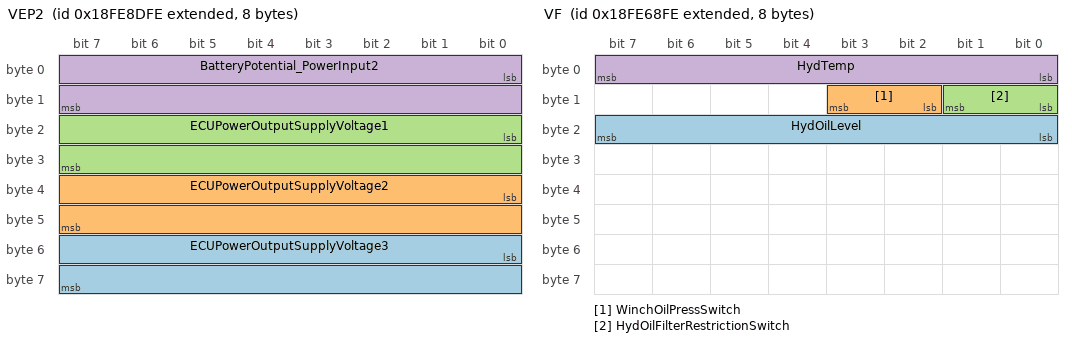
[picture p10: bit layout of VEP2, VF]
BO_ 2566819326 VEP2: 8 Vector__XXX
 SG_ ECUPowerOutputSupplyVoltage3 : 48|16@1+ (0.05,0) [0|3212.75] "V" Vector__XXX
 SG_ ECUPowerOutputSupplyVoltage2 : 32|16@1+ (0.05,0) [0|3212.75] "V" Vector__XXX
 SG_ ECUPowerOutputSupplyVoltage1 : 16|16@1+ (0.05,0) [0|3212.75] "V" Vector__XXX
 SG_ BatteryPotential_PowerInput2 : 0|16@1+ (0.05,0) [0|3212.75] "V" Vector__XXX

BO_ 2566845438 VP1: 8 Vector__XXX
 SG_ Longitude : 32|32@1+ (1E-007,-210) [-210|211.1081215] "deg" Vector__XXX
 SG_ Latitude : 0|32@1+ (1E-007,-210) [-210|211.1081215] "deg" Vector__XXX

BO_ 2566843646 VI: 8 Vector__XXX
 SG_ VehicleIdentificationNumber : 0|8@1+ (1,0) [0|255] "" Vector__XXX

BO_ 2566842366 VH: 8 Vector__XXX
 SG_ TotalPowerTakeoffHours : 32|32@1+ (0.05,0) [0|210554060.75] "h" Vector__XXX
 SG_ TotalVehicleHours : 0|32@1+ (0.05,0) [0|210554060.75] "h" Vector__XXX

BO_ 2566809854 VF: 8 Vector__XXX
 SG_ HydOilLevel : 16|8@1+ (0.4,0) [0|100] "%" Vector__XXX
 SG_ WinchOilPressSwitch : 10|2@1+ (1,0) [0|3] "" Vector__XXX
 SG_ HydOilFilterRestrictionSwitch : 8|2@1+ (1,0) [0|3] "" Vector__XXX
 SG_ HydTemp : 0|8@1+ (1,-40) [-40|210] "°C" Vector__XXX

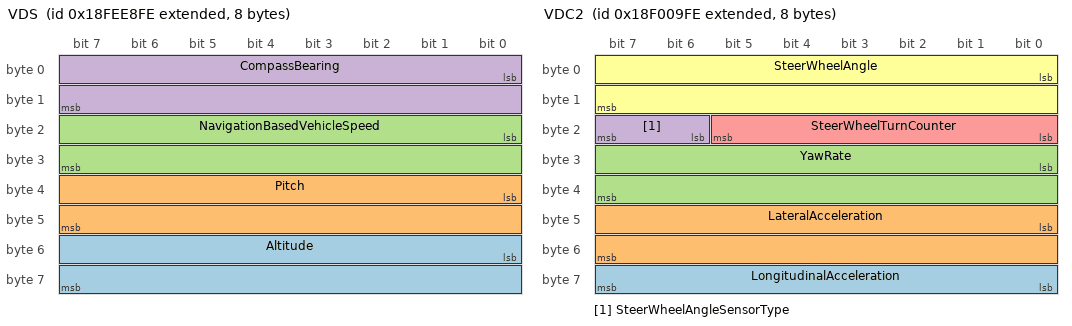
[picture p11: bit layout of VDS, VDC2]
BO_ 2566842622 VDS: 8 Vector__XXX
 SG_ Altitude : 48|16@1+ (0.125,-2500) [-2500|5531.875] "m" Vector__XXX
 SG_ Pitch : 32|16@1+ (0.0078125,-200) [-200|301.9921875] "deg" Vector__XXX
 SG_ NavigationBasedVehicleSpeed : 16|16@1+ (0.00390625,0) [0|250.99609375] "km/h" Vector__XXX
 SG_ CompassBearing : 0|16@1+ (0.0078125,0) [0|501.9921875] "deg" Vector__XXX

BO_ 2566832638 VDHR: 8 Vector__XXX
 SG_ HighResolutionTripDistance : 32|32@1+ (5,0) [0|21055406075] "m" Vector__XXX
 SG_ HghRsolutionTotalVehicleDistance : 0|32@1+ (5,0) [0|21055406075] "m" Vector__XXX

BO_ 2565868030 VDC2: 8 Vector__XXX
 SG_ LongitudinalAcceleration : 56|8@1+ (0.1,-12.5) [-12.5|12.5] "m/s²" Vector__XXX
 SG_ LateralAcceleration : 40|16@1+ (0.00048828125,-15.687) [-15.687|15.68751171875] "m/s²" Vector__XXX
 SG_ YawRate : 24|16@1+ (0.0001220703125,-3.92) [-3.92|3.9236279296875] "rad/s" Vector__XXX
 SG_ SteerWheelAngleSensorType : 22|2@1+ (1,0) [0|3] "" Vector__XXX
 SG_ SteerWheelTurnCounter : 16|6@1+ (1,-32) [-10|10] "turn" Vector__XXX
 SG_ SteerWheelAngle : 0|16@1+ (0.0009765625,-31.374) [-31.374|31.3750234375] "rad" Vector__XXX

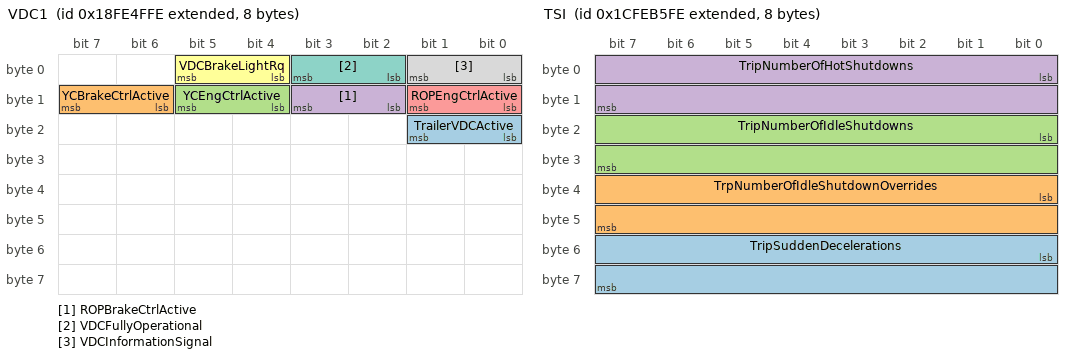
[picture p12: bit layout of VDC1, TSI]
BO_ 2566803454 VDC1: 8 Vector__XXX
 SG_ TrailerVDCActive : 16|2@1+ (1,0) [0|3] "" Vector__XXX
 SG_ YCBrakeCtrlActive : 14|2@1+ (1,0) [0|3] "" Vector__XXX
 SG_ YCEngCtrlActive : 12|2@1+ (1,0) [0|3] "" Vector__XXX
 SG_ ROPBrakeCtrlActive : 10|2@1+ (1,0) [0|3] "" Vector__XXX
 SG_ ROPEngCtrlActive : 8|2@1+ (1,0) [0|3] "" Vector__XXX
 SG_ VDCBrakeLightRq : 4|2@1+ (1,0) [0|3] "" Vector__XXX
 SG_ VDCFullyOperational : 2|2@1+ (1,0) [0|3] "" Vector__XXX
 SG_ VDCInformationSignal : 0|2@1+ (1,0) [0|3] "" Vector__XXX

BO_ 2566840574 VD: 8 Vector__XXX
 SG_ TotalVehicleDistance : 32|32@1+ (0.125,0) [0|526385151.875] "km" Vector__XXX
 SG_ TripDistance : 0|32@1+ (0.125,0) [0|526385151.875] "km" Vector__XXX

BO_ 2633938686 TVI: 8 Vector__XXX
 SG_ TripCruiseDistance : 16|32@1+ (0.125,0) [0|526385151.875] "km" Vector__XXX
 SG_ TripMaxVehicleSpeed : 0|16@1+ (0.00390625,0) [0|250.99609375] "km/h" Vector__XXX

BO_ 2633937150 TTI2: 20 Vector__XXX
 SG_ TripAirCompressorOnTime : 128|32@1+ (0.05,0) [0|210554060.75] "h" Vector__XXX
 SG_ TripIdleTime : 96|32@1+ (0.05,0) [0|210554060.75] "h" Vector__XXX
 SG_ TripEngRunningTime : 64|32@1+ (0.05,0) [0|210554060.75] "h" Vector__XXX
 SG_ TripCruiseTime : 0|32@1+ (0.05,0) [0|210554060.75] "h" Vector__XXX
 SG_ TripPTOGovernorTime : 32|32@1+ (0.05,0) [0|210554060.75] "h" Vector__XXX

BO_ 2633938174 TTI1: 16 Vector__XXX
 SG_ TripTimeInDerateByEng : 96|32@1+ (0.05,0) [0|210554060.75] "h" Vector__XXX
 SG_ TripTimeInGearDown : 64|32@1+ (0.05,0) [0|210554060.75] "h" Vector__XXX
 SG_ TripTimeInTopGear : 32|32@1+ (0.05,0) [0|210554060.75] "h" Vector__XXX
 SG_ TripTimeInVSL : 0|32@1+ (0.05,0) [0|210554060.75] "h" Vector__XXX

BO_ 2633938430 TSI: 8 Vector__XXX
 SG_ TripSuddenDecelerations : 48|16@1+ (1,0) [0|64255] "" Vector__XXX
 SG_ TrpNumberOfIdleShutdownOverrides : 32|16@1+ (1,0) [0|64255] "" Vector__XXX
 SG_ TripNumberOfIdleShutdowns : 16|16@1+ (1,0) [0|64255] "" Vector__XXX
 SG_ TripNumberOfHotShutdowns : 0|16@1+ (1,0) [0|64255] "" Vector__XXX

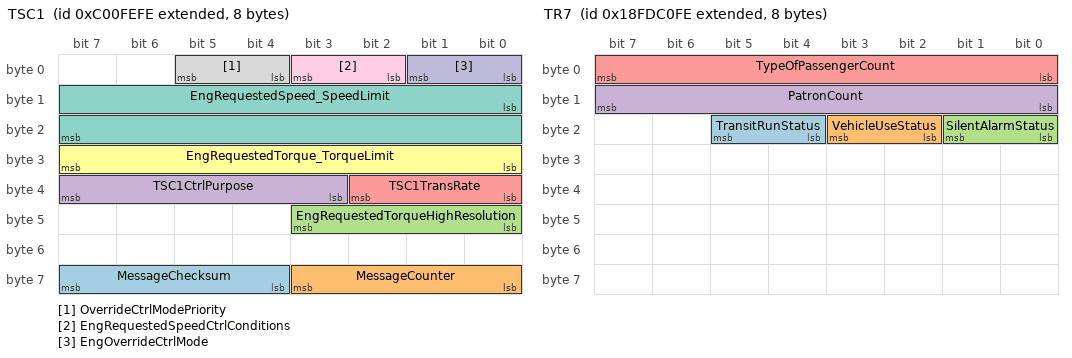
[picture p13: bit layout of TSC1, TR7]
BO_ 2348875518 TSC1: 8 Vector__XXX
 SG_ MessageChecksum : 60|4@1+ (1,0) [0|15] "" Vector__XXX
 SG_ MessageCounter : 56|4@1+ (1,0) [0|7] "" Vector__XXX
 SG_ EngRequestedTorqueHighResolution : 40|4@1+ (0.125,0) [0|0.875] "%" Vector__XXX
 SG_ TSC1CtrlPurpose : 35|5@1+ (1,0) [0|31] "" Vector__XXX
 SG_ TSC1TransRate : 32|3@1+ (1,0) [0|7] "" Vector__XXX
 SG_ EngRequestedTorque_TorqueLimit : 24|8@1+ (1,-125) [-125|125] "%" Vector__XXX
 SG_ EngRequestedSpeed_SpeedLimit : 8|16@1+ (0.125,0) [0|8031.875] "rpm" Vector__XXX
 SG_ OverrideCtrlModePriority : 4|2@1+ (1,0) [0|3] "" Vector__XXX
 SG_ EngRequestedSpeedCtrlConditions : 2|2@1+ (1,0) [0|3] "" Vector__XXX
 SG_ EngOverrideCtrlMode : 0|2@1+ (1,0) [0|3] "" Vector__XXX

BO_ 2566766846 TR7: 8 Vector__XXX
 SG_ TransitRunStatus : 20|2@1+ (1,0) [0|3] "" Vector__XXX
 SG_ VehicleUseStatus : 18|2@1+ (1,0) [0|3] "" Vector__XXX
 SG_ SilentAlarmStatus : 16|2@1+ (1,0) [0|3] "" Vector__XXX
 SG_ PatronCount : 8|8@1+ (1,0) [0|250] "" Vector__XXX
 SG_ TypeOfPassengerCount : 0|8@1+ (1,0) [0|255] "" Vector__XXX

BO_ 2566765310 TR6: 8 Vector__XXX
 SG_ FareboxAlarmIdentifier : 8|7@1+ (1,0) [0|127] "" Vector__XXX
 SG_ FareboxEmergencyStatus : 0|2@1+ (1,0) [0|3] "" Vector__XXX

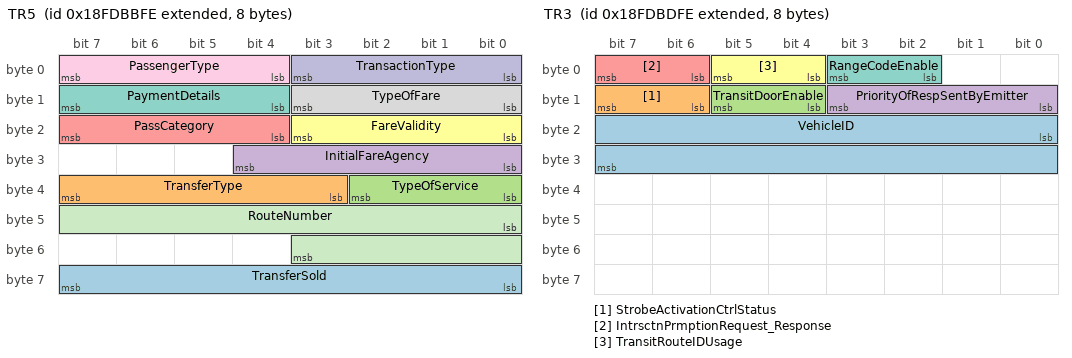
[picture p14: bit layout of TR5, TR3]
BO_ 2566765566 TR5: 8 Vector__XXX
 SG_ TransferSold : 56|8@1+ (1,0) [0|255] "" Vector__XXX
 SG_ TransferType : 35|5@1+ (1,0) [0|31] "" Vector__XXX
 SG_ TypeOfService : 32|3@1+ (1,0) [0|7] "" Vector__XXX
 SG_ InitialFareAgency : 24|5@1+ (1,0) [1|31] "" Vector__XXX
 SG_ PassCategory : 20|4@1+ (1,0) [0|15] "" Vector__XXX
 SG_ FareValidity : 16|4@1+ (1,0) [0|15] "" Vector__XXX
 SG_ PaymentDetails : 12|4@1+ (1,0) [0|15] "" Vector__XXX
 SG_ TypeOfFare : 8|4@1+ (1,0) [0|15] "" Vector__XXX
 SG_ PassengerType : 4|4@1+ (1,0) [0|15] "" Vector__XXX
 SG_ TransactionType : 0|4@1+ (1,0) [0|15] "" Vector__XXX
 SG_ RouteNumber : 40|12@1+ (1,0) [0|4095] "" Vector__XXX

BO_ 2566765822 TR4: 15 Vector__XXX
 SG_ DriversFareboxSecurityCode : 104|16@1+ (1,0) [0|65535] "" Vector__XXX
 SG_ AssignedBlock : 88|16@1+ (1,0) [0|65535] "" Vector__XXX
 SG_ AssignedRun : 72|16@1+ (1,0) [0|65535] "" Vector__XXX
 SG_ AssignedRoute : 56|16@1+ (1,0) [0|65535] "" Vector__XXX
 SG_ PatternNumber : 40|16@1+ (1,0) [0|65535] "" Vector__XXX
 SG_ TripNumber : 24|16@1+ (1,0) [0|65535] "" Vector__XXX
 SG_ FarePresets : 16|8@1+ (1,0) [0|255] "" Vector__XXX
 SG_ TripDirection : 8|4@1+ (1,0) [0|15] "" Vector__XXX
 SG_ TripStatus : 2|3@1+ (1,0) [0|7] "" Vector__XXX
 SG_ FareboxServiceStatus : 0|2@1+ (1,0) [0|3] "" Vector__XXX

BO_ 2566766078 TR3: 8 Vector__XXX
 SG_ VehicleID : 16|16@1+ (1,0) [0|65534] "" Vector__XXX
 SG_ StrobeActivationCtrlStatus : 14|2@1+ (1,0) [0|3] "" Vector__XXX
 SG_ TransitDoorEnable : 12|2@1+ (1,0) [0|3] "" Vector__XXX
 SG_ PriorityOfRespSentByEmitter : 8|4@1+ (1,0) [0|15] "" Vector__XXX
 SG_ IntrsctnPrmptionRequest_Response : 6|2@1+ (1,0) [0|3] "" Vector__XXX
 SG_ TransitRouteIDUsage : 4|2@1+ (1,0) [0|3] "" Vector__XXX
 SG_ RangeCodeEnable : 2|2@1+ (1,0) [0|3] "" Vector__XXX

BO_ 2566766590 TR2: 101 Vector__XXX
 SG_ NmbrOfBytsInThMlpstIdntification : 0|8@1+ (1,0) [0|100] "byte" Vector__XXX

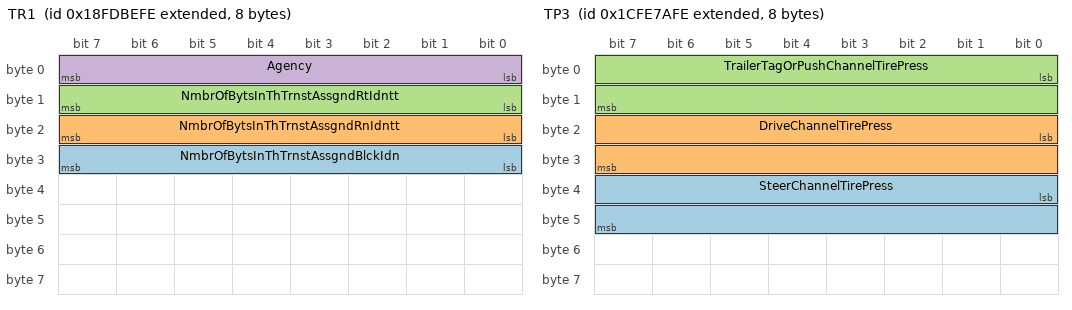
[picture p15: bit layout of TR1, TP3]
BO_ 2566766334 TR1: 8 Vector__XXX
 SG_ NmbrOfBytsInThTrnstAssgndBlckIdn : 24|8@1+ (1,0) [1|100] "byte" Vector__XXX
 SG_ NmbrOfBytsInThTrnstAssgndRnIdntt : 16|8@1+ (1,0) [1|100] "byte" Vector__XXX
 SG_ NmbrOfBytsInThTrnstAssgndRtIdntt : 8|8@1+ (1,0) [1|100] "byte" Vector__XXX
 SG_ Agency : 0|8@1+ (1,0) [0|255] "" Vector__XXX

BO_ 2561605374 TPRS: 8 Vector__XXX
 SG_ TireLocation M : 0|8@1+ (1,0) [0|255] "" Vector__XXX
 SG_ ReferenceTirePressSetting_33 m51 : 8|8@1+ (8,0) [0|2000] "kPa" Vector__XXX
 SG_ ReferenceTirePressSetting_32 m50 : 8|8@1+ (8,0) [0|2000] "kPa" Vector__XXX
 SG_ ReferenceTirePressSetting_31 m49 : 8|8@1+ (8,0) [0|2000] "kPa" Vector__XXX
 SG_ ReferenceTirePressSetting_30 m48 : 8|8@1+ (8,0) [0|2000] "kPa" Vector__XXX
 SG_ ReferenceTirePressSetting_23 m35 : 8|8@1+ (8,0) [0|2000] "kPa" Vector__XXX
 SG_ ReferenceTirePressSetting_22 m34 : 8|8@1+ (8,0) [0|2000] "kPa" Vector__XXX
 SG_ ReferenceTirePressSetting_21 m33 : 8|8@1+ (8,0) [0|2000] "kPa" Vector__XXX
 SG_ ReferenceTirePressSetting_20 m32 : 8|8@1+ (8,0) [0|2000] "kPa" Vector__XXX
 SG_ ReferenceTirePressSetting_13 m19 : 8|8@1+ (8,0) [0|2000] "kPa" Vector__XXX
 SG_ ReferenceTirePressSetting_12 m18 : 8|8@1+ (8,0) [0|2000] "kPa" Vector__XXX
 SG_ ReferenceTirePressSetting_11 m17 : 8|8@1+ (8,0) [0|2000] "kPa" Vector__XXX
 SG_ ReferenceTirePressSetting_10 m16 : 8|8@1+ (8,0) [0|2000] "kPa" Vector__XXX
 SG_ ReferenceTirePressSetting_01 m1 : 8|8@1+ (8,0) [0|2000] "kPa" Vector__XXX
 SG_ ReferenceTirePressSetting_00 m0 : 8|8@1+ (8,0) [0|2000] "kPa" Vector__XXX

BO_ 2566765054 TPRI: 8 Vector__XXX
 SG_ ReferenceTirePress_33 m51 : 8|8@1+ (8,0) [0|2000] "kPa" Vector__XXX
 SG_ ReferenceTirePress_32 m50 : 8|8@1+ (8,0) [0|2000] "kPa" Vector__XXX
 SG_ ReferenceTirePress_31 m49 : 8|8@1+ (8,0) [0|2000] "kPa" Vector__XXX
 SG_ ReferenceTirePress_30 m48 : 8|8@1+ (8,0) [0|2000] "kPa" Vector__XXX
 SG_ ReferenceTirePress_23 m35 : 8|8@1+ (8,0) [0|2000] "kPa" Vector__XXX
 SG_ ReferenceTirePress_22 m34 : 8|8@1+ (8,0) [0|2000] "kPa" Vector__XXX
 SG_ ReferenceTirePress_21 m33 : 8|8@1+ (8,0) [0|2000] "kPa" Vector__XXX
 SG_ ReferenceTirePress_20 m32 : 8|8@1+ (8,0) [0|2000] "kPa" Vector__XXX
 SG_ ReferenceTirePress_13 m19 : 8|8@1+ (8,0) [0|2000] "kPa" Vector__XXX
 SG_ ReferenceTirePress_12 m18 : 8|8@1+ (8,0) [0|2000] "kPa" Vector__XXX
 SG_ ReferenceTirePress_11 m17 : 8|8@1+ (8,0) [0|2000] "kPa" Vector__XXX
 SG_ ReferenceTirePress_10 m16 : 8|8@1+ (8,0) [0|2000] "kPa" Vector__XXX
 SG_ ReferenceTirePress_01 m1 : 8|8@1+ (8,0) [0|2000] "kPa" Vector__XXX
 SG_ ReferenceTirePress_00 m0 : 8|8@1+ (8,0) [0|2000] "kPa" Vector__XXX
 SG_ TireLocation M : 0|8@1+ (1,0) [0|255] "" Vector__XXX

BO_ 2633923326 TP3: 8 Vector__XXX
 SG_ SteerChannelTirePress : 32|16@1+ (0.5,0) [0|32127.5] "kPa" Vector__XXX
 SG_ DriveChannelTirePress : 16|16@1+ (0.5,0) [0|32127.5] "kPa" Vector__XXX
 SG_ TrailerTagOrPushChannelTirePress : 0|16@1+ (0.5,0) [0|32127.5] "kPa" Vector__XXX

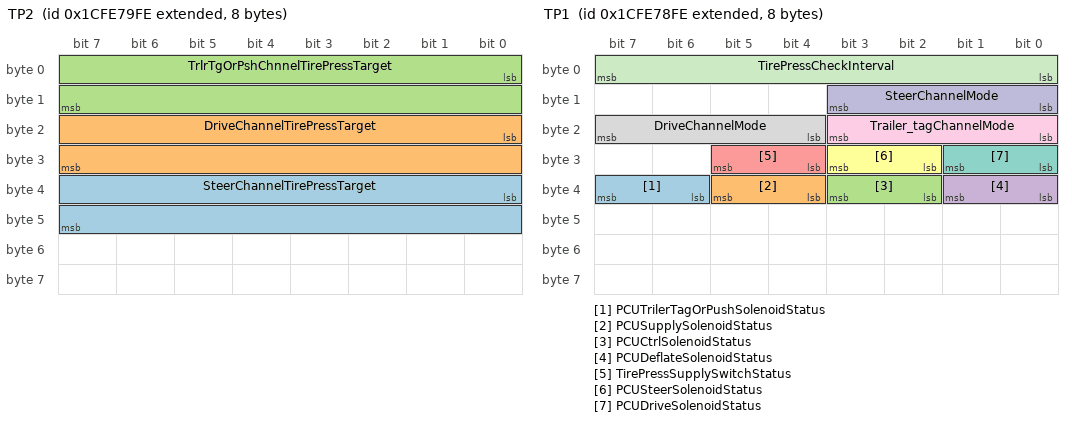
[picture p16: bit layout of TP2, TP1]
BO_ 2633923070 TP2: 8 Vector__XXX
 SG_ SteerChannelTirePressTarget : 32|16@1+ (0.5,0) [0|32127.5] "kPa" Vector__XXX
 SG_ DriveChannelTirePressTarget : 16|16@1+ (0.5,0) [0|32127.5] "kPa" Vector__XXX
 SG_ TrlrTgOrPshChnnelTirePressTarget : 0|16@1+ (0.5,0) [0|32127.5] "kPa" Vector__XXX

BO_ 2633922814 TP1: 8 Vector__XXX
 SG_ PCUTrilerTagOrPushSolenoidStatus : 38|2@1+ (1,0) [0|3] "" Vector__XXX
 SG_ PCUSupplySolenoidStatus : 36|2@1+ (1,0) [0|3] "" Vector__XXX
 SG_ PCUCtrlSolenoidStatus : 34|2@1+ (1,0) [0|3] "" Vector__XXX
 SG_ PCUDeflateSolenoidStatus : 32|2@1+ (1,0) [0|3] "" Vector__XXX
 SG_ TirePressSupplySwitchStatus : 28|2@1+ (1,0) [0|3] "" Vector__XXX
 SG_ PCUSteerSolenoidStatus : 26|2@1+ (1,0) [0|3] "" Vector__XXX
 SG_ PCUDriveSolenoidStatus : 24|2@1+ (1,0) [0|3] "" Vector__XXX
 SG_ DriveChannelMode : 20|4@1+ (1,0) [0|15] "" Vector__XXX
 SG_ Trailer_tagChannelMode : 16|4@1+ (1,0) [0|15] "" Vector__XXX
 SG_ SteerChannelMode : 8|4@1+ (1,0) [0|15] "" Vector__XXX
 SG_ TirePressCheckInterval : 0|8@1+ (1,0) [0|250] "min" Vector__XXX

CM_ BO_ 2364544766 "Cylinder Combustion Status
Used to send the SPs containing information relating to the state of combustion for 24 cylinders. When there is no combustion detected on any one cylinder, this PG needs to be sent every crank revolution (engine speed ...";
CM_ SG_ 2364544766 EngCyl24CombustionStatus "This parameter is used to indicate state of combustion in engine cylinder #24

00b = No combustion
01b = Combustion exists
10b = Error
11b = Not available";
CM_ SG_ 2364544766 EngCyl23CombustionStatus "This parameter is used to indicate state of combustion in engine cylinder #23

00b = No combustion
01b = Combustion exists
10b = Error
11b = Not available";
CM_ SG_ 2364544766 EngCyl22CombustionStatus "This parameter is used to indicate state of combustion in engine cylinder #22

00b = No combustion
01b = Combustion exists
10b = Error
11b = Not available";
CM_ SG_ 2364544766 EngCyl21CombustionStatus "This parameter is used to indicate state of combustion in engine cylinder #21

00b = No combustion
01b = Combustion exists
10b = Error
11b = Not available";
CM_ SG_ 2364544766 EngCyl20CombustionStatus "This parameter is used to indicate state of combustion in engine cylinder #20

00b = No combustion
01b = Combustion exists
10b = Error
11b = Not available";
CM_ SG_ 2364544766 EngCyl19CombustionStatus "This parameter is used to indicate state of combustion in engine cylinder #19

00b = No combustion
01b = Combustion exists
10b = Error
11b = Not available";
CM_ SG_ 2364544766 EngCyl18CombustionStatus "This parameter is used to indicate state of combustion in engine cylinder #18

00b = No combustion
01b = Combustion exists
10b = Error
11b = Not available";
CM_ SG_ 2364544766 EngCyl17CombustionStatus "This parameter is used to indicate state of combustion in engine cylinder #17

00b = No combustion
01b = Combustion exists
10b = Error
11b = Not available";
CM_ SG_ 2364544766 EngCyl16CombustionStatus "This parameter is used to indicate state of combustion in engine cylinder #16

00b = No combustion
01b = Combustion exists
10b = Error
11b = Not available";
CM_ SG_ 2364544766 EngCyl15CombustionStatus "This parameter is used to indicate state of combustion in engine cylinder #15

00b = No combustion
01b = Combustion exists
10b = Error
11b = Not available";
CM_ SG_ 2364544766 EngCyl14CombustionStatus "This parameter is used to indicate state of combustion in engine cylinder #14
00b = No combustion
01b = Combustion exists
10b = Error
11b = Not available";
CM_ SG_ 2364544766 EngCyl13CombustionStatus "This parameter is used to indicate state of combustion in engine cylinder #13

00b = No combustion
01b = Combustion exists
10b = Error
11b = Not available";
CM_ SG_ 2364544766 EngCyl12CombustionStatus "This parameter is used to indicate state of combustion in engine cylinder #12

00b = No combustion
01b = Combustion exists
10b = Error
11b = Not available";
CM_ SG_ 2364544766 EngCyl11CombustionStatus "This parameter is used to indicate state of combustion in engine cylinder #11

00b = No combustion
01b = Combustion exists
10b = Error
11b = Not available";
CM_ SG_ 2364544766 EngCyl10CombustionStatus "This parameter is used to indicate state of combustion in engine cylinder #10

00b = No combustion
01b = Combustion exists
10b = Error
11b = Not available";
CM_ SG_ 2364544766 EngCyl9CombustionStatus "This parameter is used to indicate state of combustion in engine cylinder #9

00b = No combustion
01b = Combustion exists
10b = Error
11b = Not available";
CM_ SG_ 2364544766 EngCyl8CombustionStatus "This parameter is used to indicate state of combustion in engine cylinder #8

00b = No combustion
01b = Combustion exists
10b = Error
11b = Not available";
CM_ SG_ 2364544766 EngCyl7CombustionStatus "This parameter is used to indicate state of combustion in engine cylinder #7

00b = No combustion
01b = Combustion exists
10b = Error
11b = Not available";
CM_ SG_ 2364544766 EngCyl6CombustionStatus "This parameter is used to indicate state of combustion in engine cylinder #6

00b = No combustion
01b = Combustion exists
10b = Error
11b = Not available";
CM_ SG_ 2364544766 EngCyl5CombustionStatus "This parameter is used to indicate state of combustion in engine cylinder #5

00b = No combustion
01b = Combustion exists
10b = Error
11b = Not available";
CM_ SG_ 2364544766 EngCyl4CombustionStatus "This parameter is used to indicate state of combustion in engine cylinder #4

00b = No combustion
01b = Combustion exists
10b = Error
11b = Not available";
CM_ SG_ 2364544766 EngCyl3CombustionStatus "This parameter is used to indicate state of combustion in engine cylinder #3

00b = No combustion
01b = Combustion exists
10b = Error
11b = Not available";
CM_ SG_ 2364544766 EngCyl2CombustionStatus "This parameter is used to indicate state of combustion in engine cylinder #2

00b = No combustion
01b = Combustion exists
10b = Error
11b = Not available";
CM_ SG_ 2364544766 EngCyl1CombustionStatus "This parameter is used to indicate state of combustion in engine cylinder #1

00b = No combustion
01b = Combustion exists
10b = Error
11b = Not available";
CM_ BO_ 2364544510 "Requested Generator Total AC Reactive Power
Contains requested reactive and power factor control values
These parameters are intended for stationary Generator/Engine components, not mobile applications.  See \"Motor/Generator\" PGs for electric and ...";
CM_ SG_ 2364544510 RqGenOverallPowerFactorLagging "The requested lead/lag status for the generator average AC power factor

00b = Leading
01b = Lagging
10b = Reserved
11b = Not available or Not installed";
CM_ SG_ 2364544510 RqGeneratorOverallPowerFactor "The requested average power factor of the generator.";
CM_ SG_ 2364544510 RqGeneratorTotalACReactivePower "The total reactive power requested to be delivered by the generator";
CM_ BO_ 2364544254 "Blade Information
A measurement of the machine's relative blade height and a rotational angle measurement of the machine blade yaw angle around the machine z-axis.  The vehicle dynamics measurements in this message shall be according to a Z-Down ...";
CM_ SG_ 2364544254 BladeRotationAngleFigureOfMerit "Figure of merit for blade rotation measurement.
Bits
00b = Blade Rotation Angle fully functional.  Data is within sensor specification.
01b = Blade Rotation Angle  degraded.  Data is suspect due to environmental conditions.
10b = Blade Rotation ...";
CM_ SG_ 2364544254 RelativeBladeHeightFigureOfMerit "Figure of merit for blade height measurement.
Bits
00b = Relative Blade Height fully functional.  Data is within sensor specification.
01b = Relative Blade Height degraded.  Data is suspect due to environmental conditions.
10b = Relative Blade ...";
CM_ SG_ 2364544254 RltvBldHghtAndBldRttnAnglMsrmntL "The estimated measurement latency of the measurement.
NOTE: This is only the sensor latency and does not include any additional latencies that might exist because of the CAN Bus or overall system implementation.
For example, if the technique used ...";
CM_ SG_ 2364544254 BladeRotationAngle "The blade rotation angle measurement around the yaw (z-axis).  The Blade Rotation Angle is defined to be the angle from the null position on the machine.  The null position is orthogonal from the z-axis along the x-axis.  A positive blade angle ...";
CM_ SG_ 2364544254 RelativeBladeHeight "The measured vertical distance from a fixed location on the machine blade to a ground-based reference (i.e. relative height).  Examples of a ground based reference include a curb, a stringline or the ground itself.  The measurement may be positive ...";
CM_ BO_ 2550333182 "Electronic Brake System #1/1
Message to transmit data of the towing vehicle to the towed vehicle. See ISO 11992-2.";
CM_ SG_ 2550333182 RetarderDemandRelativeTorque "The demanded value of the retarder on the towed vehicle(s) as a percentage of the absolute peak torque of retarder.";
CM_ SG_ 2550333182 ParkBrakeDemandRelativePressure "The requested brake pressure value of the parking brake as a percentage of maximum.";
CM_ SG_ 2550333182 ServiceBrakeDemandPressure "The requested brake pressure value of the service brake demanded by the driver.";
CM_ SG_ 2550333182 VehicleType "Information to identify a dolly axle within the road train.";
CM_ SG_ 2550333182 BrakeLightSwitch "Signal which indicates that the brake pedal is being pressed.";
CM_ SG_ 2550333182 ASREngineControlStatus "Signal which indicates that ASR engine control is active/passive.";
CM_ SG_ 2550333182 ASRBreakControlStatus "Signal which indicates that ASR brake control is active/passive.";
CM_ SG_ 2550333182 VehicleRetarderCtrlStatus "This signal indicates the active/passive state in all cases when the installed retarder is applied by the driver’s demand or by other systems (brakes).";
CM_ SG_ 2550333182 VehicleABSStatus "Signal indicating the ABS is active/passive.";
CM_ BO_ 2566834686 "Electronic Brake System #1/2
Message to transmit data of the towing vehicle to the towed vehicle. See ISO 11992-2.";
CM_ SG_ 2566834686 RoadCurvature "Estimated value of the current road curvature for use by the adaptive cruise control system.  Positive values are used for left curves.  Curvature is the inverse of the radius and is zero for straight roads.";
CM_ SG_ 2566834686 PneumaticControlLineStatus "Signal which indicates that the towing vehicle has a pneumatic control line for the towed vehicle service braking system";
CM_ SG_ 2566834686 ABSOffroadRequest "Request to activate the ABS off-road function. The switch signal is independent of an actual ABS control situation.";
CM_ SG_ 2566834686 TwoElCircuitsBrakeDemandStatus "Signal which indicates that the service brake demand value sent by the towing vehicle can be generated by one or two independent electrical braking circuit(s).";
CM_ SG_ 2566834686 VehicleRetarderCtrlStatus "This signal indicates the active/passive state in all cases when the installed retarder is applied by the driver’s demand or by other systems (brakes).";
CM_ BO_ 2550398718 "Electronic Brake System #2/1
Message to transmit data of the towed vehicle to the towing vehicle. See ISO 11992-2.";
CM_ SG_ 2550398718 WheelSpeedDiffMainAxle "Difference between the wheel speed at the right side and and the left side of the main axle.";
CM_ SG_ 2550398718 RetarderRelativePeakTorque "Actual torque of the retarder as negative percentage of maximum.";
CM_ SG_ 2550398718 VDCActive "Signal which indicates that Vehicle Dynamic Control (VDC) is active/passive.";
CM_ SG_ 2550398718 AutomTowedVehicleBreakStatus "Signal indicating the automatic towed vehicle braking is active/passive.";
CM_ SG_ 2550398718 VehicleServiceBrakeStatus "Signal indicating the service brake of the towed vehicle is active/passive, by observing the brake pressure.";
CM_ SG_ 2550398718 VehicleRetarderCtrlStatus "This signal indicates the active/passive state in all cases when the installed retarder is applied by the driver’s demand or by other systems (brakes).";
CM_ SG_ 2550398718 VehicleABSStatus "Signal indicating the ABS is active/passive.";
CM_ BO_ 2566833406 "Electronic Brake System #2/2
Message to transmit data of the towed vehicle to the towing vehicle. See ISO 11992-2.";
CM_ SG_ 2566833406 ReferenceRetarderTorque "This parameter is the 100% reference value for all defined indicated retarder torque parameters.  It is only defined once and doesn't change if a different retarder torque map becomes valid.";
CM_ SG_ 2566833406 AxleLoadSum "Sum of the static vertical loads of the vehicle axles.";
CM_ SG_ 2566833406 SupplyLineBraking "Signal indicating the trailer is requesting to be braked by the commercial vehicle by means of bleeding the pneumatic supply line.";
CM_ SG_ 2566833406 LoadingRampApprAssistStatus "The parameter indicates whether the loading ramp approach assistance is activated.";
CM_ SG_ 2566833406 SpringBrakeStatus "Signal indicating the vehicle spring brake is engaged.";
CM_ SG_ 2566833406 ElectrLoadPropFuncInstalStatus "Signal indicating the vehicle is equipped with an electrical load proportional function.";
CM_ SG_ 2566833406 SpringBrakeInstallationStatus "Signal indicating the vehicle has one or more axle(s) fitted with spring brakes.";
CM_ SG_ 2566833406 VehicleType "Information to identify a dolly axle within the road train.";
CM_ SG_ 2566833406 ElectSupplyOfNonBrakingSysStatus "Signal which indicates the status of the supply of non-braking systems.";
CM_ SG_ 2566833406 AmberWarningSignalReq "Request from the towed vehicle to the commercial vehicle to activate the amber warning signal on the commercial vehicle.";
CM_ SG_ 2566833406 RedWarningSignalRequest "Request from the towed vehicle to the commercial vehicle to activate the red warning signal on the commercial vehicle, which indicates certain specified failures within the braking equipment of the towed vehicles.";
CM_ SG_ 2566833406 VehicleElectrSupplyStatus "Signal indicating the actual supply voltage is sufficient/insufficient for proper brake function (including over voltage).";
CM_ SG_ 2566833406 AutomTowedVehicleBreakStatus "Signal indicating the automatic towed vehicle braking is active/passive.";
CM_ SG_ 2566833406 VehicleServiceBrakeStatus "Signal indicating the service brake of the towed vehicle is active/passive, by observing the brake pressure.";
CM_ SG_ 2566833406 VehicleRetarderCtrlStatus "This signal indicates the active/passive state in all cases when the installed retarder is applied by the driver’s demand or by other systems (brakes).";
CM_ SG_ 2566833406 VehicleABSStatus "Signal indicating the ABS is active/passive.";
CM_ BO_ 2566833918 "Electronic Brake System #2/3
Message to transmit data of the towed vehicle to the towing vehicle. See ISO 11992-2.";
CM_ SG_ 2566833918 PneumaticSupplyPressure "Actual supply pressure of the reservoir of the braking system.";
CM_ SG_ 2566833918 BrakeTemperature "Actual brake temperature.";
CM_ SG_ 2566833918 BrakeLining "Actual relative value of brake lining of a specific brake.";
CM_ SG_ 2566833918 TyrePressure "Actual tyre pressure without corrections.";
CM_ SG_ 2566833918 TyreWheelIDBrakeTemp2 "Second part of identification number of the tyre or wheel (the number of axles).";
CM_ SG_ 2566833918 TyreWheelIDBrakeTemp1 "First part of identification number of the tyre or wheel (position on each axle).";
CM_ SG_ 2566833918 TyreWheelIDTyrePressure2 "Second part of identification number of the tyre or wheel (the number of axles).";
CM_ SG_ 2566833918 TyreWheelIDTyrePressure1 "First part of identification number of the tyre or wheel (position on each axle).";
CM_ SG_ 2566833918 TyreWheelIDBrakeLining2 "Second part of identification number of the tyre or wheel (the number of axles).";
CM_ SG_ 2566833918 TyreWheelIDBrakeLining1 "First part of identification number of the tyre or wheel (position on each axle).";
CM_ SG_ 2566833918 VehiclePneumSupplyStatus "Signal indicating the actual supply pressure of the reservoir of the braking system is insufficient or sufficient.";
CM_ SG_ 2566833918 BrakeTemperatureStatus "Signal which indicates that the brake temperature is higher than a specific level.";
CM_ SG_ 2566833918 BrakeLiningStatus "Signal which indicates that the brake lining is sufficient/insufficient.";
CM_ SG_ 2566833918 TyrePressureStatus "Signal which indicates that the tyre pressure is insufficient";
CM_ BO_ 2565013246 "General Purpose Message #1/1
Message to transmit data of the towing vehicle to the towed vehicle. See ISO 11992-3.";
CM_ SG_ 2565013246 ODDVersionRequest "APP – ODM Version Information";
CM_ SG_ 2565013246 ArticulationAngleDrawbarTowed "Articulation Angle between drawbar and towed vehicle";
CM_ SG_ 2565013246 ArticulationAngleTowingDrawbar "Articulation Angle between towing vehicle and drawbar";
CM_ SG_ 2565013246 ArticulationAngleTowingTowed "Articulation Angle between towing and towed vehicle";
CM_ SG_ 2565013246 DetailedVehicleType "APP – Detailed Vehicle Type";
CM_ SG_ 2565013246 ODDRequest "Command signal to switch on or off the obstacle detection device (ODD).";
CM_ SG_ 2565013246 AntiTheftDeviceReq "Command signal to activate the anti-theft device.";
CM_ SG_ 2565013246 VehicleType "Information to identify a dolly axle within the road train.";
CM_ BO_ 2566807038 "General Purpose Message #1/2
Message to transmit data of the towing vehicle to the towed vehicle. See ISO 11992-3.";
CM_ SG_ 2566807038 MaxVehicleSpeedLimit "Maximum vehicle velocity allowed.   See SPN 6808 for an alternate resolution.";
CM_ SG_ 2566807038 EngineSpeedUpperLimit "The engine speed which cannot be exceeded.";
CM_ SG_ 2566807038 EngineSpeedLowerLimit "The minimum engine speed which the engine is allowed to reach.";
CM_ BO_ 2566807550 "General Purpose Message #1/3
Message to transmit data of the towing vehicle to the towed vehicle. See ISO 11992-3.";
CM_ SG_ 2566807550 TachographVehicleSpeed "Speed of the vehicle registered by the tachograph.";
CM_ SG_ 2566807550 EngPercentLoadAtCurrentSpeed "The ratio of actual engine percent torque (indicated) to maximum indicated torque available at the current engine speed, clipped to zero torque during engine braking.";
CM_ SG_ 2566807550 ActualEngPercentTorque "The calculated output torque of the engine.  The data is transmitted in indicated torque as a percent of reference engine torque (see the engine configuration message, PGN 65251).  The engine percent torque value will not be less than zero and it ...";
CM_ SG_ 2566807550 DriversDemandEngPercentTorque "The requested torque output of the engine by the driver. It is based on input from the following requestors external to the powertrain: operator (via the accelerator pedal), cruise control and/or road speed limit governor. Dynamic commands from ...";
CM_ SG_ 2566807550 EngTorqueMode "State signal which indicates which engine torque mode is currently generating, limiting, or controlling the torque.  Note that the modes are not in prioritized order. Not all modes may be relevant for a given device.  Some devices may not implement ...";
CM_ SG_ 2566807550 EngineSpeed "Actual engine speed which is calculated over a minimum crankshaft angle of 720 degrees divided by
the number of cylinders.";
CM_ SG_ 2566807550 EngineRunning "Signal which indicates whether the engine is running.";
CM_ SG_ 2566807550 EngineControlAllowed "Switch signal which indicates that engine control is allowed.";
CM_ BO_ 2566808062 "General Purpose Message #1/4
Message to transmit data of the towing vehicle to the towed vehicle. See ISO 11992-3.";
CM_ SG_ 2566808062 TransCurrentGear "The gear currently engaged in the transmission or the last gear engaged while the transmission is in the process of shifting to the new or selected gear.  Transitions toward a destination gear will not be indicated.  Once the selected gear has been ...";
CM_ SG_ 2566808062 ClutchIndptdPTOFeedback "Signal which indicates the current state of the clutch independent power take off.";
CM_ SG_ 2566808062 AccelPedalPosition "The ratio of actual accelerator pedal position to maximum pedal position.";
CM_ SG_ 2566808062 AccelPedalLowIdleSwitch "Switch signal which indicates whether the accelerator pedal low idle switch is opened or closed.";
CM_ SG_ 2566808062 StarterActive "Signal which indicates whether the starter is in use.";
CM_ SG_ 2566808062 TorqueConvOilTemp "Temperature of the torque converter lubricant.";
CM_ SG_ 2566808062 TorqueConvtOilTempWarning "Signal which indicates that the torque converter oil temperature has reached its warning level.";
CM_ SG_ 2566808062 PTOControlAllowed "Switch signal which indicates that PTO control is allowed.";
CM_ SG_ 2566808062 SecEngineMtdPTOFeedback "Signal which indicates the current state of the second engine mounted power take off.";
CM_ SG_ 2566808062 FirstEngineMtdPTOFeedback "Signal which indicates the current state of the first engine mounted power take off.";
CM_ SG_ 2566808062 SecClutchDptdPTOFeedback "Signal which indicates the current state of the second clutch dependent power take off.";
CM_ SG_ 2566808062 FirstClutchDpdtPTOFeedback "Signal which indicates the current state of the first clutch dependent power take off.";
CM_ SG_ 2566808062 PercentClutchSlip "Parameter which represents the ratio of input shaft speed to current engine speed (in percent).

Percent Clutch Slip = ((Engine rpm - Input shaft rpm)/(Engine rpm)) x 100";
CM_ BO_ 2566808574 "General Purpose Message #1/5
Message to transmit data of the towing vehicle to the towed vehicle. See ISO 11992-3.";
CM_ SG_ 2566808574 ReferenceTrq "This parameter is the 100% reference value for all defined transmission output torque parameters.  For a given vehicle application, it is only defined once and doesn't change.";
CM_ SG_ 2566808574 EngOilPress "Gage pressure of oil in engine lubrication system as provided by oil pump.  See SPN 7468 for alternate resolution.";
CM_ SG_ 2566808574 FuelLevelWarning "This signal indicates the decrease of the fuel level to a certain minimum.";
CM_ SG_ 2566808574 EngineOilPressureWarning "Signal which indicates that the engine oil pressure has reached its warning level.";
CM_ SG_ 2566808574 EngineCoolantTempWarning "Signal which indicates that the engine coolant temperature has reached its warning level.";
CM_ SG_ 2566808574 EngCoolantTemp "Temperature of liquid found in engine cooling system.";
CM_ SG_ 2566808574 EngineOilTemperature "Temperature of the engine lubricant.";
CM_ BO_ 2566809086 "General Purpose Message #1/6
Message to transmit data of the towing vehicle to the towed vehicle. See ISO 11992-3.";
CM_ SG_ 2566809086 AmbientAirTemp "Temperature of air surrounding vehicle.";
CM_ BO_ 2564947710 "General Purpose Message #2/1
Message to transmit data of the towed vehicle to the towing vehicle. See ISO 11992-3.";
CM_ SG_ 2564947710 ArticulationAngleDrawbarTowed "Articulation Angle between drawbar and towed vehicle";
CM_ SG_ 2564947710 ArticulationAngleTowingTowed "Articulation Angle between towing and towed vehicle";
CM_ SG_ 2564947710 ODDVersionInformation "APP – ODM Version Information";
CM_ SG_ 2564947710 DetailedVehicleType "APP – Detailed Vehicle Type";
CM_ SG_ 2564947710 VehicleType "Information to identify a dolly axle within the road train.";
CM_ BO_ 2566834430 "General Purpose Message #2/2
Message to transmit data of the towed vehicle to the towing vehicle. See ISO 11992-3.";
CM_ SG_ 2566834430 BodyPressure "The actual pressure in a body on the towed vehicle.";
CM_ SG_ 2566834430 BodyFluidLevel "The actual fluid level in a body on the towed vehicle.";
CM_ SG_ 2566834430 ThermalBodyTemperature "The actual temperature in a thermal body on the towed vehicle.";
CM_ SG_ 2566834430 RearObstacleDistance "The actual distance between the back of the towed vehicle and any obstacle.";
CM_ SG_ 2566834430 AntiTheftDeviceStatus "Signal which indicates that the anti-theft device is switched on or off.";
CM_ SG_ 2566834430 ODDStatus "Signal which indicates that an obstacle detection device (ODD) is active/inactive.";
CM_ BO_ 2566807806 "General Purpose Message #2/3
Message to transmit data of the towed vehicle to the towing vehicle. See ISO 11992-3.";
CM_ SG_ 2566807806 ReqEngineSpeedUpperLim "The requested engine speed which is not to be exceeded.";
CM_ SG_ 2566807806 ReqEngineSpeedLowerLim "The requested minimum engine speed which the engine is to allow.";
CM_ SG_ 2566807806 ReqEngineTorqueLimit "The requested engine torque that the engine is not allowed to exceed, indicated as a ratio of the reference engine torque.";
CM_ SG_ 2566807806 ReqEngineSpeedLimit "The requested vehicle speed which the vehicle is not allowed to exceed.";
CM_ SG_ 2566807806 ReqEngineSpeed "This is the engine speed which the engine is expected to operate at.";
CM_ BO_ 2566808318 "General Purpose Message #2/4
Message to transmit data of the towed vehicle to the towing vehicle. See ISO 11992-3.";
CM_ SG_ 2566808318 SecEngineMtdPTOSwitch "Signal which indicates the state of the second engine mounted power take off switch.";
CM_ SG_ 2566808318 SecClutchDpdtPTOSwitch "Signal which indicates the state of the second clutch dependent power take off switch.";
CM_ SG_ 2566808318 FirstClutchDpdtPTOSwitch "Signal which indicates the state of the first clutch dependent power take off switch.";
CM_ SG_ 2566808318 OperatingPanelActive "Signal which indicates that the operating panel is active.";
CM_ SG_ 2566808318 RefusePackerStepSwitch "Signal which indicates the state of the refuse packer step switch.";
CM_ SG_ 2566808318 EngineStopSwitch "Signal which indicates the state of the engine stop switch.";
CM_ SG_ 2566808318 EngineStartSwitch "Signal which indicates the state of the engine start switch.";
CM_ SG_ 2566808318 StarterLockoutSwitch "Signal which indicates the state of the starter lockout switch.";
CM_ SG_ 2566808318 RqstedPercentClutchSlip "Command signal to influence the clutch.";
CM_ SG_ 2566808318 FirstEngineMtdPTOSwitch "Signal which indicates the state of the first engine mounted power take off switch.";
CM_ SG_ 2566808318 ClutchIndpdtPTOSwitch "Signal which indicates the state of the clutch independent power take off switch.";
CM_ BO_ 2566808830 "General Purpose Message #2/5
Message to transmit data of the towed vehicle to the towing vehicle. See ISO 11992-3.";
CM_ SG_ 2566808830 TowedVehicleLeftSideMarkerLight "This signal indicates the state of the trailer left-hand side marker light(s).";
CM_ SG_ 2566808830 TowedVehicleLeftReversingLight "This signal indicates the state of the trailer left-hand reversing light(s).";
CM_ SG_ 2566808830 TowedVehicleLeftRearWidIndLight "This signal indicates the state of the trailer left-hand rear width indicator light(s).";
CM_ SG_ 2566808830 TowedVehicleLeftRearRegPltLight "This signal indicates the state of the trailer left-hand rear registration-plate light(s).";
CM_ SG_ 2566808830 TowedVehicleLeftRearLight "This signal indicates the state of the trailer left-hand rear light(s).";
CM_ SG_ 2566808830 TowedVehicleLeftRearFogLight "This signal indicates the state of the trailer left-hand rear fog light(s).";
CM_ SG_ 2566808830 TowedVehicleLeftDirIndLight "This signal indicates the state of the trailer left-hand direction indicator light(s).";
CM_ SG_ 2566808830 TowedVehicleLeftCrnMarkerLight "This signal indicates the state of the trailer left-hand corner marker light(s).";
CM_ SG_ 2566808830 TowedVehicleInteriorLight "This signal indicates the state of the trailer interior light(s).";
CM_ SG_ 2566808830 TowedVehicleWorkLight "This signal indicates the state of the trailer work lamp(s).";
CM_ SG_ 2566808830 TowedVehicleRotatingIdentLight "This signal indicates the state of the trailer rotating identification light(s).";
CM_ SG_ 2566808830 TowedVehicleRightStopLight "This signal indicates the state of the trailer right-hand stop light(s).";
CM_ SG_ 2566808830 TowedVehicleRightSideMrkLight "This signal indicates the state of the trailer right-hand side marker light(s).";
CM_ SG_ 2566808830 TowedVehicleRightReversingLight "This signal indicates the state of the trailer right-hand reversing light(s).";
CM_ SG_ 2566808830 TowedVehicleRearWidIndLight "This signal indicates the state of the trailer right-hand rear width indicator light(s).";
CM_ SG_ 2566808830 TowedVehicleRightRearRegPltLight "This signal indicates the state of the trailer right-hand rear registration-plate light(s).";
CM_ SG_ 2566808830 TowedVehicleRightRearLight "This signal indicates the state of the trailer right-hand rear light(s).";
CM_ SG_ 2566808830 TowedVehicleRightRearFogLight "This signal indicates the state of the trailer right-hand rear fog light(s).";
CM_ SG_ 2566808830 TowedVehicleRightDirIndLight "This signal indicates the state of the trailer right-hand direction indicator light(s).";
CM_ SG_ 2566808830 TowedVehicleRightCrnMarkerLight "This signal indicates the state of the trailer right-hand corner marker light(s).";
CM_ SG_ 2566808830 TowedVehicleRearWarningLight "This signal indicates the state of the trailer rear warning light(s).";
CM_ SG_ 2566808830 TowedVehicleLeftStopLight "This signal indicates the state of the trailer left-hand stop light(s).";
CM_ BO_ 2564554494 "Reserved for ISO 15765";
CM_ SG_ 2564554494 ProtocolCtrlInformation "Part of Network Protocol Control Information (N_PCI) of a ISO 15765 message.";
CM_ BO_ 2564488958 "Reserved for ISO 15765";
CM_ SG_ 2564488958 ProtocolCtrlInformation "Part of Network Protocol Control Information (N_PCI) of a ISO 15765 message.";
CM_ BO_ 2565734142 "Network Layer";
CM_ SG_ 2565734142 NumberOfSA_NAMEPairs "The number of instances of Source Addresses and associated NAMEs included in the associated data content.";
CM_ SG_ 2565734142 ToPort "Identifies the destination port, or send port, of messages being moved through the NIECU. 
The Port Number assignments are defined within SAE J1939-31. ";
CM_ SG_ 2565734142 NetworkMessageControlByte "Identifies the function or service of an instance of the Network Message.  
A summary of the Network Message Control Bytes value assignments are defined within SAE J1939-31.";
CM_ SG_ 2565734142 FilterMode "Identifies the mode of filtering operation applied for messages being passed from one specific port to another specific port. 
The Filter Mode value assignments are defined within SAE J1939-31.";
CM_ SG_ 2565734142 NIECUPort "Identifies a specific port of the NIECU without context of messaging direction. 
The Port Number assignments are defined within SAE J1939-31.";
CM_ SG_ 2565734142 FromPort "Identifies the origination port, or receive port, of messages being moved through the NIECU. 
The Port Number assignments are defined within SAE J1939-31. ";
CM_ BO_ 2565144318 "Running Gear Equipment #1/1
Message to transmit data of the towing vehicle to the towed vehicle. See ISO 11992-2.";
CM_ SG_ 2565144318 LiftAxle5PositionReq "Command signal to control the lift axle position / tag axle load condition.";
CM_ SG_ 2565144318 LiftAxle4PositionReq "Command signal to control the lift axle position / tag axle load condition.";
CM_ SG_ 2565144318 LiftAxle3PositionReq "Command signal to control the lift axle position / tag axle load condition.";
CM_ SG_ 2565144318 ParkingAndTrailerAirPress "The pneumatic pressure in the circuit or reservoir for the parking brake and the trailer supply.";
CM_ SG_ 2565144318 DrivenAxleLoad "Actual static vertical load on driven axle of the commercial vehicle. In case of more than one driven axle the value of the axle with the highest vertical load is transmitted.";
CM_ SG_ 2565144318 AuxEquipSupplyPressure "The pneumatic pressure in the auxiliary circuit.";
CM_ SG_ 2565144318 StopLevelChangeReq "Command signal to stop immediately any change of the actual body height level.";
CM_ SG_ 2565144318 RampLevelStorageReq "Command signal to store the actual body height level as new programmed and memorised ramp levels 1 or 2 in the ECU";
CM_ SG_ 2565144318 LevelControlReq "Command signal to enable or disable the automatic level control.";
CM_ SG_ 2565144318 RampLevelReq "Command signal to control the body height to a level programmed and memorised in the ECU.";
CM_ SG_ 2565144318 SteeringAxleLockingReq "Command signal to lock the steering axle.";
CM_ SG_ 2565144318 LiftAxle2PositionReq "Command signal to control the lift axle position / tag axle load condition.";
CM_ SG_ 2565144318 LiftAxle1PositionReq "Command signal to control the lift axle position / tag axle load condition.";
CM_ SG_ 2565144318 TractionHelpReq "Command signal to control the lift axle position / tag axle load condition to transfer more load on the driven axle of the commercial vehicle.";
CM_ SG_ 2565144318 LevelChangeReqRearAxle "Command signal to control the body height [up (lifting)/down (lowering)] for the rear axle.";
CM_ SG_ 2565144318 LevelChangeReqFrontAxle "Command signal to control the body height [up (lifting)/down (lowering)] for the front axle.";
CM_ SG_ 2565144318 RideHeightRequest "Command signal to activate a normal ride body height. The normal levels 1 and 2 are trailer specific body heights.";
CM_ BO_ 2565209854 "Running Gear Equipment #2/1
Message to transmit data of the towed vehicle to the towing vehicle. See ISO 11992-2.";
CM_ SG_ 2565209854 LevelControl "Signal which indicates that the automatic level control is enabled or disabled.";
CM_ SG_ 2565209854 NominalVehBodyLevelRearAxle "Actual nominal vehicle body height.";
CM_ SG_ 2565209854 NominalVehBodyLevelFrontAxle "Actual nominal vehicle body height.";
CM_ SG_ 2565209854 RampLevel "Signal which indicates the level of the body height as an anser to 'ramp level request'.";
CM_ SG_ 2565209854 NormalLevel "Signal which indicates the normal levels of the vehicle independently of a specific request.";
CM_ SG_ 2565209854 StopLevelChangeAcknowledge "Signal which indicates the stop of any level change due to a 'stop request'.";
CM_ SG_ 2565209854 LevelChangeRearAxle "Signal which indicates the level change of the body height at the rear axle due to any external requests.";
CM_ SG_ 2565209854 LevelChangeFrontAxle "Signal which indicates the level change of the body height at the front axle due to any external requests.";
CM_ SG_ 2565209854 RampLevelStorage "Signal which indicates the storage of a new ramp level in the ECU.";
CM_ SG_ 2565209854 SteeringAxleLockingStatus "Signal which indicates the actual steering axle locking status.";
CM_ SG_ 2565209854 LiftAxle2Pos "Signal which indicates the position / load condition of lift axle / tag axle #2.   Numbering of lift/tag axles starts at front axle.  See SPN 6844 for more detail.
00b = Lift axle position down / tag axle laden
01b = Lift axle position up / tag ...";
CM_ SG_ 2565209854 LiftAxle1Pos "Signal which indicates the position / load condition of lift axle / tag axle 1.   Numbering of lift/tag axles starts at front axle.  See SPN 6843 for more detail.
00b = Lift axle position down / tag axle laden
01b = Lift axle position up / tag ...";
CM_ SG_ 2565209854 RampLevelPosition "Signal which indicates the ramp level positions of the vehicle independently of a specific request.";
CM_ SG_ 2565209854 TractionHelpStatus "Signal which indicates that a load transfer is active.";
CM_ SG_ 2565209854 RideHeightLevel "Signal which indicates the body height position of the vehicle as an answer to 'ride height request'.";
CM_ BO_ 2566806782 "Running Gear Equipment #2/2
Message to transmit data of the towed vehicle to the towing vehicle. See ISO 11992-2.";
CM_ SG_ 2566806782 RelVehBodyLevelRearAxle "Actual relative vehicle body height.";
CM_ SG_ 2566806782 RelVehBodyLevelFrontAxle "Actual relative vehicle body height.";
CM_ BO_ 2566807294 "Running Gear Equipment #2/3
Message to transmit data of the towed vehicle to the towing vehicle. See ISO 11992-2.";
CM_ SG_ 2566807294 TyrePressThresholdDetect "Signal indicating the pressure level of the tyre.";
CM_ SG_ 2566807294 TyreModulePowerSupplyStatus "Signal indicating the power supply of the tyre module is sufficient to achieve the specified performance of the module.";
CM_ SG_ 2566807294 TyreTemperature "The temperature measured by the tyre module.";
CM_ SG_ 2566807294 AirLeakageDetection "The pressure loss of a tyre.";
CM_ BO_ 2566764798 "Diagnostic Readiness 3
This message conveys information useful in determining whether the OBD System has a defect or not.";
CM_ SG_ 2566764798 NumOfWarmUpsSinceDTCsCleared "Number of warm-up cycles since all DTCs were cleared (via an external test equipment or possibly, a battery disconnect).  A warm-up is defined in the OBD regulations to be sufficient vehicle operation such that coolant temperature rises by at least ...";
CM_ SG_ 2566764798 TimeSinceEngineStart "RUNTM shall increment while the engine is running.  It shall freeze if the engine stalls.  RUNTM shall be reset to zero during every control module power-up and when entering the key-on, engine off position.  RUNTM is limited to 65,535 seconds and ...";
CM_ BO_ 2564095742 "Data Security
The data security parameter group is used to send security entities of a given type and length. These entities are data produced by or used for applications of cryptography and supporting procedures to ensure data security.";
CM_ SG_ 2564095742 DataSecurityParameter "This Parameter is used to send the data for the Data Security message. There are presently four different items defined. The Data Security Parameter shall be sent least significant byte first.";
CM_ SG_ 2564095742 SecurityEntityType "This 4-bit parameter that indicates whether the data in the following Security Entity parameter is to be used as a Long Seed, Long Key, Session Key, or Certificate.";
CM_ SG_ 2564095742 SecurityEntityLength "This 12-bit parameter contains the length, in bytes, of the Data Security Parameter.";
CM_ BO_ 2349137662 "External Brake Request
Used for brake control by an external device. The receiver is the brake system controlling the axle and/or wheel brakes. This system has to process the demanded acceleration.  Note: This PG shall not be used for external ...";
CM_ SG_ 2349137662 XBRBrkHoldReq "This parameter is used by external sources to request the brake system to hold the vehicle still using service brakes.

00b = Brake Hold not requested
01b = Brake Hold requested
10b = Reserved
11b = Not available";
CM_ SG_ 2349137662 XBRCompensationMode "The parameter indicates whether the XBR request is a request for retardation (deceleration caused by braking) only, i.e. without the brake system making any compensations for other known sources of deceleration that it can calculate or measure, e.g ...";
CM_ SG_ 2349137662 XBRMessageChecksum "The XBR message checksum is used to verify the signal path from the demanding device to the brake controller on electronic brake systems.  The support of this parameter is mandatory if PGN 1024 is supported as there is no means to indicate \"not ...";
CM_ SG_ 2349137662 XBRMessageCounter "The XBR message counter is to verify the signal path from the demanding device to the brake controller on electronic brake systems..  The support of this parameter is mandatory.
Note:  The initial value of the 4 bit message counter for the first ...";
CM_ SG_ 2349137662 XBRUrgency "The idea of the urgency value is to adjust the endurance brake integration behavior in the EBS system according to the traffic situation.
On low urgency values (0%, e.g. downhill cruise control or preceding vehicle far ahead) the brake system shall ...";
CM_ SG_ 2349137662 XBRCtrlMode "The XBR Control Mode is used as an input to the brake system and defines how the external acceleration demand has to be realized.
00b = Override disabled - Disable any existing control commanded by the source of this command.
01b = Acceleration ...";
CM_ SG_ 2349137662 XBRPriority "The XBR Priority is used as an input to the brake system to manage the priority of overlapping external and internal requests.
00b = Highest priority - used for emergency situations, e.g. for future Collision Avoidance System.  This mode overrides ...";
CM_ SG_ 2349137662 XBREBIMode "The XBR EBI (Endurance Brake Integration) Mode is used as an input for the brake system to prescribe the use of endurance brakes like retarders or engine brakes.
00b = No Endurance Brake Integration allowed
The demanded acceleration must be ...";
CM_ SG_ 2349137662 ExtlAccelerationDemand "Parameter provided to the brake system from external sources. This is the acceleration which the brake system is expected to realize. It is specified as an absolute acceleration in reference to the road.  Positive values lead to increasing vehicle ...";
CM_ BO_ 2566848510 "Operator indicators";
CM_ SG_ 2566848510 EngSvcInd "Indicates the service need of the engine.

000b = No service needed
001b = Service engine soon
010b = Service engine now
011b = Reserved
100b = Reserved
101b = Reserved
110b = Reserved
111b = Not Available";
CM_ SG_ 2566848510 EmissionCtrlSysOpSpdIndSev "Indicates that an operator speed Inducement due to the emission control system will be applied to the engine operation.  Higher numerical levels indicate more severe levels of inducement.  Level 1 is the least severe.
000b = DEF Warning, Low-Level ...";
CM_ SG_ 2566848510 EmissionCtrlSysOpTrqIndSev "Indicates that an operator torque Inducement due to the emission control system will be applied to the engine operation. Higher numerical levels indicate more severe levels of inducement.  Level 1 is the least severe.
000b = DEF Warning, Low-Level ...";
CM_ SG_ 2566848510 StartReqInhInd "State signal indicating a start request from the operator to the engine to be active or inactive. The start inhibit indicator can be of lamp or text form, located on (but not limited to) the shift console, instrument cluster, or cab display.
Engine ...";
CM_ SG_ 2566848510 RecommendedNumOfGearsToShift "Recommended number of gears to shift relative to current gear. Operator Shift Prompt (SPN 5675) indicates whether to shift up or down.";
CM_ SG_ 2566848510 EngOilLifeRemaining "Signal which indicates the actual oil life remaining in percent. 100% means the engine oil is brand new, and 0% means the engine oil is at the end of its life.";
CM_ SG_ 2566848510 AutoStartReqInhInd "State signal indicating an engine request for the Automatic Start Request Inhibit Indicator to be active or inactive. The start inhibit indicator can be of lamp or text form, located on (but not limited to) the shift console, instrument cluster, or ...";
CM_ SG_ 2566848510 FuelSupplyEstRemainingDist "Estimated remaining distance based on existing fuel supply.";
CM_ SG_ 2566848510 WaterInChargeADAfterChargeACInd "Signal which indicates the presence of water in charge air duct after charge air cooler.

00b = No
01b = Yes
10b = Error
11b = Not available";
CM_ SG_ 2566848510 EngOverloadedInd "Signal which indicates that the engine is overloaded.

00b = No
01b = Yes
10b = Error
11b = Not available";
CM_ SG_ 2566848510 EmssnCtrlSystmOprtrIndcmntSvrity "Severity status of the operator inducement system for anomalies with the emission control system, such as tampering, low diesel exhaust fluid (reagent) quality, diesel exhaust fluid (reagent) tank level, or EGR system errors.  Higher numerical ...";
CM_ SG_ 2566848510 DrvrWarningSystemIndicatorStatus "The desired illumination of the Euro VI defined driver warning system indicator for relevant malfunctions and diesel exhaust fluid (reagent) tank low level.  Used for Euro VI implementations.  See Euro VI implementing regulation Annex XIII, Section ...";
CM_ SG_ 2566848510 OperatorShiftPrompt "Command to activate an indicator that advises the operator to shift to a different gear.  Typically this would be used as part of a fuel economy improvement or drivability aid.
00b = indicator(s) inactive
01b = upshift indicator active
10b = ...";
CM_ SG_ 2566848510 WaterInFuelIndicator "Signal which indicates the presence of water in the fuel.

00b = No
01b = Yes
10b = Error
11b = Not available";
CM_ SG_ 2566848510 WaterInFuelIndicator2 "A second indicator of the presense of water in the fuel.  See also SPN 97.

00b = No
01b = Yes
10b = Error
11b = Not available";
CM_ BO_ 2566843134 "Vehicle Weight
NOTE–Request has to be responded to with as many messages as necessary to transmit all available information.";
CM_ SG_ 2566843134 AxleLocation "To identify to which of several similar devices (such as tires or fuel tanks) the information applies.
The low order 4 bits represent a position number, counting left to right when facing in the direction of normal vehicle travel (forward).
The ...";
CM_ SG_ 2566843134 CargoWeight_30 "The mass of freight carried.";
CM_ SG_ 2566843134 CargoWeight_20 "The mass of freight carried.";
CM_ SG_ 2566843134 CargoWeight_10 "The mass of freight carried.";
CM_ SG_ 2566843134 CargoWeight_00 "The mass of freight carried.";
CM_ SG_ 2566843134 TrailerWeight_30 "Total mass of freight-carrying vehicle designed to be pulled by truck, including the weight of the contents.";
CM_ SG_ 2566843134 TrailerWeight_20 "Total mass of freight-carrying vehicle designed to be pulled by truck, including the weight of the contents.";
CM_ SG_ 2566843134 TrailerWeight_10 "Total mass of freight-carrying vehicle designed to be pulled by truck, including the weight of the contents.";
CM_ SG_ 2566843134 TrailerWeight_00 "Total mass of freight-carrying vehicle designed to be pulled by truck, including the weight of the contents.";
CM_ SG_ 2566843134 AxleWeight_30 "Total mass imposed by the tires on the road surface at the specified axle.";
CM_ SG_ 2566843134 AxleWeight_20 "Total mass imposed by the tires on the road surface at the specified axle.";
CM_ SG_ 2566843134 AxleWeight_10 "Total mass imposed by the tires on the road surface at the specified axle.";
CM_ SG_ 2566843134 AxleWeight_00 "Total mass imposed by the tires on the road surface at the specified axle.";
CM_ BO_ 2566804222 "Vehicle Electrical Power 3
This contains high resolution/range parameters reported from the alternator or power generation components.";
CM_ SG_ 2566804222 ECUKeySwSt "Indicates the key switch state detected at the input of the electronic control unit supplied through a key switch or similar switching device.
00b = Off
01b = On
10b = Error
11b = Not Available
Note:  See SPN 158 (Key Switch Battery Potential) ...";
CM_ SG_ 2566804222 SLIBattery2NetCurrent "Net flow of electrical current into/out of the second battery or second set of batteries used for starting the engine, for lighting, and for ignition (SLI).";
CM_ SG_ 2566804222 NetBatteryCurrent "Net flow of electrical current into/out of the first battery or first set of batteries used for starting the engine, for lighting, and for ignition (SLI).  If more than one battery is included in the first set of batteries and the net current for ...";
CM_ SG_ 2566804222 AltCurrent "This parameter indicates the amount of electrical current output from the alternator of the main vehicle.  Alternator Current (SPN 115) has a lower range and resolution.";
CM_ BO_ 2566819326 "Vehicle Electrical Power 2
Voltage data for the main vehicle Power Distribution system.";
CM_ SG_ 2566819326 ECUPowerOutputSupplyVoltage3 "The third power output from an ECU.";
CM_ SG_ 2566819326 ECUPowerOutputSupplyVoltage2 "The second power output from an ECU.";
CM_ SG_ 2566819326 ECUPowerOutputSupplyVoltage1 "The first power output from an ECU.";
CM_ SG_ 2566819326 BatteryPotential_PowerInput2 "This parameter measures the second source of battery potential as measured at the input of the ECU/actuator etc. coming from one or more batteries, irrespective of the distance between the component and the battery.  This SP is also used when ECUs ...";
CM_ BO_ 2566845438 "Vehicle Position 1";
CM_ SG_ 2566845438 Longitude "Longitude position of the vehicle.

Negative values are West and positive value are East.";
CM_ SG_ 2566845438 Latitude "Latitude position of the vehicle.

Negative values are South and positive values are North.";
CM_ BO_ 2566843646 "Vehicle Identification
Byte: 1-n Vehicle Identification Number
Delimiter (ASCII “*”)";
CM_ SG_ 2566843646 VehicleIdentificationNumber "Vehicle Identification Number (VIN) as assigned by the vehicle manufacturer.

NOTE The ASCII character “*” is reserved as a delimiter.";
CM_ BO_ 2566842366 "Vehicle Hours";
CM_ SG_ 2566842366 TotalPowerTakeoffHours "Accumulated time of operation of power takeoff device.";
CM_ SG_ 2566842366 TotalVehicleHours "Accumulated time of operation of vehicle.";
CM_ BO_ 2566809854 "Vehicle Fluids";
CM_ SG_ 2566809854 HydOilLevel "This parameter indicates the level of the hydraulic fluid in tank as a ratio of current volume to total tank volume.  This parameter is intended for reporting the hydraulic fluid level in the system tank or reservoir.  This hydraulic fluid is for ...";
CM_ SG_ 2566809854 WinchOilPressSwitch "State of switch used to determine if Winch Oil Pressure is above desired minimum

00b = NOT OK- Oil pressure is too low
01b = OK - Oil pressure is above minimum
10b = Error - Switch state cannot be determined
11b = Not Available";
CM_ SG_ 2566809854 HydOilFilterRestrictionSwitch "This switch indicates whether hydraulic oil filter is clogged. This is not the transmission oil filter restriction switch, which is SPN 3359.

00b = No restriction
01b = Restriction exists on oil filter
10b = Error
11b = Not Available";
CM_ SG_ 2566809854 HydTemp "Temperature of hydraulic fluid.";
CM_ BO_ 2566842622 "Vehicle Direction/Speed";
CM_ SG_ 2566842622 Altitude "Altitude of the vehicle referenced to sea level at standard atmospheric pressure and temperature.";
CM_ SG_ 2566842622 Pitch "Pitch (rotation about the y-axis) of the vehicle as calculated by the navigation device(s).  The pitch angle for an angle of ascent is reported with a positive value. This parameter is defined according to a Z-Down axis system and the sign of the ...";
CM_ SG_ 2566842622 NavigationBasedVehicleSpeed "Speed of the vehicle as calculated from a device such as a Global Positioning System (GPS).";
CM_ SG_ 2566842622 CompassBearing "Present compass bearing of vehicle.";
CM_ BO_ 2566832638 "High Resolution Vehicle Distance";
CM_ SG_ 2566832638 HighResolutionTripDistance "Distance traveled during all or part of a journey.

NOTE - See SPN 244 for alternate resolution.";
CM_ SG_ 2566832638 HghRsolutionTotalVehicleDistance "Accumulated distance traveled by the vehicle during its operation.

NOTE - See SPN 245 for alternate resolution.";
CM_ BO_ 2565868030 "Vehicle Dynamic Stability Control 2
Contains information which relates to the vehicle's movement.";
CM_ SG_ 2565868030 LongitudinalAcceleration "Indicates the longitudinal acceleration of the vehicle. A positive longitudinal acceleration signal results when the vehicle speed increases, regardless of driving the vehicle forward or backward.  This parameter is applicable to vehicle speed ...";
CM_ SG_ 2565868030 LateralAcceleration "Indicates a lateral acceleration of the vehicle (the component of vehicle acceleration vector along the Y-axis). A positive lateral acceleration signal results when the vehicle is accelerated to the left.  This parameter is defined according to a ...";
CM_ SG_ 2565868030 YawRate "Indicates the rate of rotation about the vertical axis (i.e. the z-axis).  A positive yaw rate signal results when the vehicle turns counter-clockwise.   This parameter is defined according to a Z-Up axis system and the sign of the value is in ...";
CM_ SG_ 2565868030 SteerWheelAngleSensorType "Indicates whether the steering wheel angle sensor is capable of absolute measuring of the number of steering wheel turns or not (relative measuring to position at ignition on).
00b = Relative measuring principle
01b = Absolute measuring principle
 ...";
CM_ SG_ 2565868030 SteerWheelTurnCounter "Indicates number of steering wheel turns, absolute position or relative position at ignition on. Positive values indicate left turns.";
CM_ SG_ 2565868030 SteerWheelAngle "The main operator`s steering wheel angle (on the steering column, not the actual wheel angle).  The vehicle being steered to the left (counterclockwise) results in a positive steering wheel angle.  This is the yaw angle of the steering wheel with ...";
CM_ BO_ 2566803454 "Vehicle Dynamic Stability Control 1
Contains information which relates to the VDC system status.";
CM_ SG_ 2566803454 TrailerVDCActive "The trailer-VDC (Vehicle Dynamic Control) is an electronic vehicle stability function within the (semi) trailer braking system. It acts to stabilize the (semi) trailer during dynamic maneuvers. VDC includes Roll Over Prevention (ROP) and/or Yaw ...";
CM_ SG_ 2566803454 YCBrakeCtrlActive "State signal which indicates that Yaw Control (YC) has activated brake control. Active means that YC actually controls wheel brake pressure at one or more wheels of the vehicle or vehicle combination. Within the physical limits, YC attempts to ...";
CM_ SG_ 2566803454 YCEngCtrlActive "State Signal which indicates that the Yaw Control (YC) has commanded engine control to be active. Within the physical limits, YC attempts to prevent yawing of the vehicle. Active means that YC actually tries to control the engine. This state signal ...";
CM_ SG_ 2566803454 ROPBrakeCtrlActive "State signal which indicates that Roll over Prevention (ROP) has activated brake control. Active means that ROP actually controls wheel brake pressure at one or more wheels of the vehicle or vehicle combination. Within the physical limits, ROP ...";
CM_ SG_ 2566803454 ROPEngCtrlActive "State Signal which indicates that the Roll Over Prevention (ROP) has commanded engine control to be active. Within the physical limits, ROP attempts to prevent rolling over of the vehicle. Active means that ROP actually tries to control the engine ...";
CM_ SG_ 2566803454 VDCBrakeLightRq "Indicates whether VDC requests to turn the vehicle brake lights on

00b = Turn brake light not on
01b = Turn brake light on
10b = Reserved
11b = Don't care/Take no action";
CM_ SG_ 2566803454 VDCFullyOperational "Signal that indicates whether VDC is fully operational or whether its functionality is reduced by a permanent or temporary (e.g. low voltage) defect, by intended action (e.g. disabled by a switch or during special diagnostic procedures), not ...";
CM_ SG_ 2566803454 VDCInformationSignal "This parameter commands the VDC information signal, for example a dash lamp.

00b = Off
01b = On
10b = Reserved
11b = Don't care/Take no action";
CM_ BO_ 2566840574 "Vehicle Distance";
CM_ SG_ 2566840574 TotalVehicleDistance "Accumulated distance traveled by vehicle during its operation.

NOTE See SPN 917 for alternate resolution.";
CM_ SG_ 2566840574 TripDistance "Distance traveled during all or part of a journey.

NOTE See SPN 918 for alternate resolution.";
CM_ BO_ 2633938686 "Trip Vehicle Speed/Cruise Distance Information";
CM_ SG_ 2633938686 TripCruiseDistance "Total distance that the engine has operated in the cruise hold state, excluding time in accelerator override, since the last trip reset.";
CM_ SG_ 2633938686 TripMaxVehicleSpeed "Maximum vehicle speed achieved while the engine speed is greater than zero and the accelerator pedal position (APS) is at a value greater than 0%, since the last trip reset.";
CM_ BO_ 2633937150 "Trip Time Information 2";
CM_ SG_ 2633937150 TripAirCompressorOnTime "Total time that the air compressor is on and compressing air since the last trip reset.";
CM_ SG_ 2633937150 TripIdleTime "Total time accumulated while the engine speed is greater than zero, both the PTO and remote PTO governors are inactive, and the vehicle speed is less than 2 km/h, since the last trip reset.
In marine applications, this parameter is defined as the ...";
CM_ SG_ 2633937150 TripEngRunningTime "Total time accumulated while the engine speed is greater than zero since the last trip reset.  Note that time with the ignition switch on but engine speed at zero is not included.";
CM_ SG_ 2633937150 TripCruiseTime "Total time accumulated while the engine is in the cruise hold state, excluding time in accelerator override, since the last trip reset.";
CM_ SG_ 2633937150 TripPTOGovernorTime "Total time accumulated while the engine is in the PTO or remote PTO governor hold state since the last trip reset.";
CM_ BO_ 2633938174 "Trip Time Information 1";
CM_ SG_ 2633938174 TripTimeInDerateByEng "Total time accumulated when the engine final fueling has been derated due to an engine protection algorithm, since the last reset.";
CM_ SG_ 2633938174 TripTimeInGearDown "Total time accumulated when the vehicle has operated in one gear down from the top gear for a calibrated minimum time, since the last trip reset.";
CM_ SG_ 2633938174 TripTimeInTopGear "Total time accumulated when the vehicle has operated in top gear for a calibrated minimum time, since the last trip reset.";
CM_ SG_ 2633938174 TripTimeInVSL "Total time accumulated when the engine has operated on the vehicle speed limiter (VSL) while not in the cruise hold state, since the last trip reset.  The engine torque mode is equal to road speed governor during this operation.";
CM_ BO_ 2633938430 "Trip Shutdown Information";
CM_ SG_ 2633938430 TripSuddenDecelerations "Total number of decelerations whenever the vehicle deceleration is more than XYZ km/h/sec (where XYZ is a calibratible threshold), since the last trip reset.  A lengthy deceleration shall be counted as one sudden deceleration.";
CM_ SG_ 2633938430 TrpNumberOfIdleShutdownOverrides "Total number of times an operator disables idle shutdown to prevent an engine shutdown, since the last trip reset.";
CM_ SG_ 2633938430 TripNumberOfIdleShutdowns "Total number of times the engine has been shutdown due to idling too long (at normal idle or fast idle) since the last trip reset.";
CM_ SG_ 2633938430 TripNumberOfHotShutdowns "Total number of hot shutdowns since the last trip reset.  A hot shutdown is based on operation at high load or high engine speed or for long operating periods without allowing the engine to cool sufficiently.";
CM_ BO_ 2348875518 "Torque/Speed Control 1
NOTE - Retarder may be disabled by commanding a torque limit of 0%.  Use of the limit mode allows the use of the retarder only up to the limit specified in the request.  This can be used to permit retarding of up to 50%, for ...";
CM_ SG_ 2348875518 MessageChecksum "The message checksum is used to verify the signal path from the transmitting device to the receiving device.
The message checksum is calculated using the first 7 data bytes, the message counter and the bytes of the message identifier.
For SAE ...";
CM_ SG_ 2348875518 MessageCounter "The message counter is used to detect situations where the transmitting ECU malfunction repeats the same frame all the time.  The receiver of the information may use the counter parameter to detect this situation.  The transmitting device will ...";
CM_ SG_ 2348875518 EngRequestedTorqueHighResolution "This parameter displays an additional torque in percent of the reference engine torque.
When the MSB is set to 1, this parameter is not available.  When the MSB is set to 0, bits 1 to 3 indicate the desired torque with resolution of 0.125%/bit  ...";
CM_ SG_ 2348875518 TSC1CtrlPurpose "State signal which indicates which control mode the sending device is using to generate the TSC1 command.  Note that the modes are not in prioritized order. Not all modes may be relevant for a given device. Some devices may not implement all ...";
CM_ SG_ 2348875518 TSC1TransRate "This parameter indicates the transmission rate at which the sending device will transmit the TSC1 message.  The engine shall adjust its timeout for TSC1 messages accordingly. Variable TSC1 transmission rates shall only apply to messages sent to the ...";
CM_ SG_ 2348875518 EngRequestedTorque_TorqueLimit "Parameter provided to the engine or retarder in the torque/speed control message for controlling or limiting the output torque.
Requested torque to the engine is measured in indicated torque as a percentage of reference engine torque (see the ...";
CM_ SG_ 2348875518 EngRequestedSpeed_SpeedLimit "Parameter provided to the engine from external sources in the torque/speed control message.  This is the engine speed which the engine is expected to operate at if the speed control mode is active or the engine speed which the engine is not expected ...";
CM_ SG_ 2348875518 OverrideCtrlModePriority "This field is used as an input to the engine or retarder to determine the priority of the Override Control Mode received in the Torque/Speed Control message (see PGN 0).  The default is 11b (Low priority).  It is not required to use the same ...";
CM_ SG_ 2348875518 EngRequestedSpeedCtrlConditions "This mode tells the engine control system the governor characteristics that are desired during speed control.  The four characteristics defined are:
00b = Transient Optimized for driveline disengaged and non-lockup conditions
01b = Stability ...";
CM_ SG_ 2348875518 EngOverrideCtrlMode "The override control mode defines which sort of command is used:
00b = Override disabled - Disable any existing control commanded by the source of this command.
01b = Speed control - Govern speed to the included \"desired speed\" value.
10b = ...";
CM_ BO_ 2566766846 "Passenger Counter
Used to notify the transit link devices of real-time boarding and exiting passengers or to indicate the total number of passengers on vehicle referenced to the last transit stop.
Also transmits information on the use status of ...";
CM_ SG_ 2566766846 TransitRunStatus "Status of the run switch for the vehicle.

00b = Off
01b = On
10b = Error condition
11b = Not available";
CM_ SG_ 2566766846 VehicleUseStatus "Used to indicate the proper or unauthorized use of the vehicle. The administrative control device or any device issuing the vehicle use status PID should be sensitive to the run switch status (SPN 3046) and any other locally defined criteria for ...";
CM_ SG_ 2566766846 SilentAlarmStatus "Used to report silent alarm push button status.

00b = Off
01b = On
10b = Error condition
11b = Not available";
CM_ SG_ 2566766846 PatronCount "Count of the number of passengers on a transit vehicle.  If the type of passenger count (SPN 3043) is 0, the patron count indicates the number of patrons currently on vehicle after the door has closed.  If the type of passenger count is 1 to 4,
the ...";
CM_ SG_ 2566766846 TypeOfPassengerCount "Used to notify transit link devices of the type of passenger counting system used in the vehicle.  Some passenger counting systems indicate real-time boarding and exiting data for other devices to accumulate. Other types of passenger counters report ...";
CM_ BO_ 2566765310 "Farebox Status
Used to report alarms of the fare collection unit.";
CM_ SG_ 2566765310 FareboxAlarmIdentifier "Indicates the nature of the farebox alarm condition.
0000000b = Voltage dropout
0000001b = Voltage restored
0000010b = Probe started
0000011b = Probe completed
0000100b = Cashbox removed
0000101b = Cashbox restored
0000110b = Cashbox door ...";
CM_ SG_ 2566765310 FareboxEmergencyStatus "Indicates if a farebox emergency condition exists.

00b = Non-emergency condition
01b = Emergency condition
10b = Error Condition
11b = Not available";
CM_ BO_ 2566765566 "Farebox Point of Sale
Used to report stop level point of sale detail.";
CM_ SG_ 2566765566 TransferSold "Indicates that a transfer was sold or issued on this transaction including its type and/or restrictions. The final definitions of the transfer issued information shall be agreed by the operating agency and the farebox manufacturer.
Note:  A ...";
CM_ SG_ 2566765566 TransferType "The kind of transfer used

00000b = North
00001b = South
00010b = East
00011b = West
00100b = In
00101b = Out
00110b to 11111b = Agency defined";
CM_ SG_ 2566765566 TypeOfService "The type of service provided

000b = Local service
001b = Express service
010b to 111b = Agency defined";
CM_ SG_ 2566765566 InitialFareAgency "Identifies where the initial fare is paid

Note:  The definition of the agency numbering plan shall be agreed by the operating agency and the farebox manufacturer.  The value of 0 is reserved, the usable range is 1 to 31.";
CM_ SG_ 2566765566 PassCategory "Agency defined value indicating the category of the passenger associated with this fare";
CM_ SG_ 2566765566 FareValidity "Agency defined value indicating validity of this fare";
CM_ SG_ 2566765566 PaymentDetails "Payment details.

0000b = Not an upgrade
0001b = Cash
0010b = Token
0011b = Ticket
0100b = Pass
0101b = Card
0110b to 1010b = Reserved for assignment
1011b to 1111b = Agency defined";
CM_ SG_ 2566765566 TypeOfFare "Type of Fare

0000b = Cash/No detail
0001b = Token A
0010b = Token B
0011b = Ticket A
0100b = Ticket B
0101b = Pass A
0110b = Pass B
0111b to 1010b = Reserved for assignment
1011b to 1111b = Agency defined";
CM_ SG_ 2566765566 PassengerType "Enumerated value representing the type/class of passenger, as defined by the agency.";
CM_ SG_ 2566765566 TransactionType "Enumerated value representing the type of transaction completed
0000b = Cash
0001b = Token
0010b = Ticket
0011b = Pass
0100b = Card
0101b = Permit
0110b = Transfer
0111b = Free
1000b to 1011b = Reserved for assignment
1100b to 1111b = ...";
CM_ SG_ 2566765566 RouteNumber "The route number issuing the transfer.";
CM_ BO_ 2566765822 "Farebox Service Detail
Used to identify service, assignments, and fare preset detail of the fare collection unit.";
CM_ SG_ 2566765822 DriversFareboxSecurityCode "Security code for the farebox, numerical only.

Note:  0 = Farebox is in reporting status
1 to 65535 = security code";
CM_ SG_ 2566765822 AssignedBlock "The agency defined block number for this trip";
CM_ SG_ 2566765822 AssignedRun "The agency defined run number for this trip";
CM_ SG_ 2566765822 AssignedRoute "The identity number assigned to this route.

Note:  This is the numerical value for the route as opposed to the \"Transit Assigned Route Identity\" (SPN 3074) which is variable length ASCII or the \"Route number\" (SPN 3169) which is 12 bit numeric.";
CM_ SG_ 2566765822 PatternNumber "The agency defined pattern number for this trip";
CM_ SG_ 2566765822 TripNumber "The identity number assigned to this trip.";
CM_ SG_ 2566765822 FarePresets "Fare Presets

00000000b to 00001111b = Agency defined
00010000b to 11111111b = Reserved for assignment";
CM_ SG_ 2566765822 TripDirection "The general direction of travel for this trip.

0000b = North
0001b = South
0010b = East
0011b = West
0100b = In
0101b = Out
0110b to 1111b = Agency defined";
CM_ SG_ 2566765822 TripStatus "Trip Status

000b = Undefined
001b = Trip start
010b = Trip end
011b = Undefined
100b = Undefined
101b = Layover start
110b = Layover end
111b = Undefined";
CM_ SG_ 2566765822 FareboxServiceStatus "Indicates if the farebox is in or out of service.

00b = Farebox out of service
01b = Farebox in service
10b = Error Condition
11b = Not available";
CM_ BO_ 2566766078 "Signal Preemption
Status and configuration of the device used for intersection preemption.";
CM_ SG_ 2566766078 VehicleID "Numerical designation of the vehicle.   65535 is used to represent the vehicle ID is not available.";
CM_ SG_ 2566766078 StrobeActivationCtrlStatus "Strobe activation control status

00b = Deactivate strobe
01b = Activate strobe
10b = Error condition
11b = Not available

Note: Strobe will flash if not overridden by transit door status, strobe is working, and emitter is in the normal mode.";
CM_ SG_ 2566766078 TransitDoorEnable "Transit door enable

00b = Ignore transit door status
01b = Transit door status will override strobe activation
10b = Error condition
11b = Not available";
CM_ SG_ 2566766078 PriorityOfRespSentByEmitter "Priority of response sent by emitter
0000b = Reserved
0001b = Low priority
0010b = Probe priority
0011b = High priority
0100b to 1000b = Reserved
1001b = Priority set by hardware to low priority
1010b = Priority set by hardware to probe ...";
CM_ SG_ 2566766078 IntrsctnPrmptionRequest_Response "Status of the intersection signal preemption

00b = Message is a request directed to the emitter
01b = Message is a response from the emitter
10b = Error condition
11b = Not available";
CM_ SG_ 2566766078 TransitRouteIDUsage "Transit route ID usage

00b = Transit route ID not used for interleaved data
01b = Transit route ID used for interleaved data (if range code not enabled)
10b = Error condition
11b = Not available";
CM_ SG_ 2566766078 RangeCodeEnable "Range code enable

00b = Range code not used for interleaved data
01b = Range code used for interleaved data
10b = Error condition
11b = Not available";
CM_ BO_ 2566766590 "Transit Milepost
Identification of a transit route milepost";
CM_ SG_ 2566766590 NmbrOfBytsInThMlpstIdntification "Number of bytes in the Milepost Identification.  This parameter identifies the length, in bytes, of the data in SPN 509 (Milepost Identification).";
CM_ BO_ 2566766334 "Transit Route
The current route assigned to this transit vehicle. The transit route information may be entered into different devices by different authorities (fare collection, radio log, unit control panel, etc.).";
CM_ SG_ 2566766334 NmbrOfBytsInThTrnstAssgndBlckIdn "Number of bytes in the Transit Assigned Block Identity.  This parameter identifies the length, in bytes, of the data in SPN 3076 (Transit Assigned Block Identity).";
CM_ SG_ 2566766334 NmbrOfBytsInThTrnstAssgndRnIdntt "Number of bytes in the Transit Assigned Run Identity.  This parameter identifies the length, in bytes, of the data in SPN 3075 (Transit Assigned Run Identity).";
CM_ SG_ 2566766334 NmbrOfBytsInThTrnstAssgndRtIdntt "Number of bytes in the Transit Assigned Route Identity.  This parameter identifies the length, in bytes, of the data in SPN 3074 (Transit Assigned Route Identity).";
CM_ SG_ 2566766334 Agency "The identity of the agency involved in this transaction";
CM_ BO_ 2561605374 "Tire Pressure Reference Setting
For setting the tire pressure reference values.

This message is the setpoint for the PGN 64953 Tire Pressure reference information message.";
CM_ SG_ 2561605374 TireLocation "Identifies which tire is associated with the parametric data in this PGN.
The low order 4 bits represent a position number, counting left to right when facing in the direction of normal vehicle travel (forward).
The high order 4 bits represent a ...";
CM_ BO_ 2566765054 "Tire Pressure Reference Information
Information on actual tire pressure reference value for monitoring.
NOTE–Message has to repeated as necessary to transmit all available information.  This method of location identification requires individual ...";
CM_ SG_ 2566765054 TireLocation "Identifies which tire is associated with the parametric data in this PGN.
The low order 4 bits represent a position number, counting left to right when facing in the direction of normal vehicle travel (forward).
The high order 4 bits represent a ...";
CM_ BO_ 2633923326 "Tire Pressure Control Unit Current Pressures";
CM_ SG_ 2633923326 SteerChannelTirePress "The latest gage pressure reading of the steer group of tires, as opposed to the pressure in each tire.";
CM_ SG_ 2633923326 DriveChannelTirePress "The latest gage pressure reading of the drive group of tires, as opposed to the pressure in each tire.";
CM_ SG_ 2633923326 TrailerTagOrPushChannelTirePress "The latest gage pressure reading of the trailer, tag, or push group of tires, as opposed to the pressure in each tire.";
CM_ BO_ 2633923070 "Tire Pressure Control Unit Target Pressures";
CM_ SG_ 2633923070 SteerChannelTirePressTarget "The tire pressure control system’s target gage pressure for the steer group of tires.";
CM_ SG_ 2633923070 DriveChannelTirePressTarget "The tire pressure control system’s target gage pressure for the drive group of tires.";
CM_ SG_ 2633923070 TrlrTgOrPshChnnelTirePressTarget "The tire pressure control system’s target gage pressure for the trailer, tag, or push group of tires.";
CM_ BO_ 2633922814 "Tire Pressure Control Unit Mode and Status";
CM_ SG_ 2633922814 PCUTrilerTagOrPushSolenoidStatus "Current state of the trailer, tag, or push solenoid used to implement a tire pressure control system in its pneumatic control unit (PCU).

00b = Off
01b = On
10b = Error
11b = Not available";
CM_ SG_ 2633922814 PCUSupplySolenoidStatus "Current state of the supply solenoid used to implement a tire pressure control system in its pneumatic control unit (PCU).

00b = Off
01b = On
10b = Error
11b = Not available";
CM_ SG_ 2633922814 PCUCtrlSolenoidStatus "Current state of the control solenoid used to implement a tire pressure control system in its pneumatic control unit (PCU).

00b = Off
01b = On
10b = Error
11b = Not available";
CM_ SG_ 2633922814 PCUDeflateSolenoidStatus "Current state of the deflate solenoid used to implement a tire pressure control system in its pneumatic control unit (PCU).

00b = Off
01b = On
10b = Error
11b = Not available";
CM_ SG_ 2633922814 TirePressSupplySwitchStatus "Current state of an open/closed type switch used to determine if adequate pressure exists for system implementation.

00b = Off
01b = On
10b = Error
11b = Not available";
CM_ SG_ 2633922814 PCUSteerSolenoidStatus "Current state of the steer solenoid used to implement a tire pressure control system in its pneumatic control unit (PCU).

00b = Off
01b = On
10b = Error
11b = Not available";
CM_ SG_ 2633922814 PCUDriveSolenoidStatus "Current state of the drive solenoid used to implement a tire pressure control system in its pneumatic control unit (PCU).

00b = Off
01b = On
10b = Error
11b = Not available";
CM_ SG_ 2633922814 DriveChannelMode "Indicates the functional mode of trailer/tag channel of the tire pressure control system.
0000b = Maintain
0001b = Inflate
0010b = Deflate
0011b = Confirm
0100b = Inflate Wait - System will inflate when conditions allow
0101b = Deflate Wait - ...";
CM_ SG_ 2633922814 Trailer_tagChannelMode "Indicates the functional mode of trailer/tag channel of the tire pressure control system.
0000b = Maintain
0001b = Inflate
0010b = Deflate
0011b = Confirm
0100b = Inflate Wait - System will inflate when conditions allow
0101b = Deflate Wait - ...";
CM_ SG_ 2633922814 SteerChannelMode "Indicates the functional mode of steer channel of the tire pressure control system.
0000b = Maintain
0001b = Inflate
0010b = Deflate
0011b = Confirm
0100b = Inflate Wait - System will inflate when conditions allow
0101b = Deflate Wait - System ...";
CM_ SG_ 2633922814 TirePressCheckInterval "The interval at which the system will check the tire pressures (e.g., 5, 10, 15 min.).

NOTE - A value of 0 indicates continuous (real time) pressure readings.";
BA_DEF_ SG_  "GenSigInactiveValue" INT 0 0;
BA_DEF_ SG_  "SigType" ENUM  "Default","Range","RangeSigned","ASCII","Discrete","Control","ReferencePGN","DTC","StringDelimiter","StringLength","StringLengthControl","MessageCounter","MessageChecksum";
BA_DEF_ SG_  "GenSigStartValue" INT 0 2147483647;
BA_DEF_ SG_  "GenSigSendType" ENUM  "Cyclic","OnWrite","OnWriteWithRepetition","OnChange","OnChangeWithRepetition","IfActive","IfActiveWithRepetition","NoSigSendType";
BA_DEF_ SG_  "GenSigILSupport" ENUM  "No","Yes";
BA_DEF_ SG_  "SPN" INT 0 524287;
BA_DEF_ BO_  "J1939CPgSendTimeout" INT -1 3600000;
BA_DEF_ BO_  "J1939CPgTOS" INT 0 7;
BA_DEF_ BO_  "J1939PgAppearanceOnBus" ENUM  "Default","CAN_Extended","CANFD_Extended";
BA_DEF_ BO_  "FsJ1939UseCrcAndCounter" STRING ;
BA_DEF_ BO_  "TpJ1939VarDlc" ENUM  "No","Yes";
BA_DEF_ BO_  "GenMsgNrOfRepetition" INT 0 1000000;
BA_DEF_ BO_  "GenMsgCycleTimeFast" INT 0 3600000;
BA_DEF_ BO_  "GenMsgFastOnStart" INT 0 100000;
BA_DEF_ BO_  "GenMsgStartDelayTime" INT 0 100000;
BA_DEF_ BO_  "GenMsgILSupport" ENUM  "No","Yes";
BA_DEF_ BO_  "GenMsgDelayTime" INT 0 1000;
BA_DEF_ BO_  "GenMsgRequestable" INT 0 1;
BA_DEF_ BO_  "GenMsgSendType" ENUM  "cyclic","NotUsed","NotUsed","NotUsed","NotUsed","NotUsed","NotUsed","IfActive","noMsgSendType";
BA_DEF_ BO_  "VFrameFormat" ENUM  "StandardCAN","ExtendedCAN","reserved","J1939PG","reserved","reserved","reserved","reserved","reserved","reserved","reserved","reserved","reserved","reserved","StandardCAN_FD","ExtendedCAN_FD";
BA_DEF_ BO_  "SingleFrame" INT 0 1;
BA_DEF_ BO_  "GenMsgCycleTime" INT 0 3600000;
BA_DEF_ SG_  "SystemSignalLongSymbol" STRING ;
BA_DEF_DEF_  "GenSigInactiveValue" 0;
BA_DEF_DEF_  "SigType" "Default";
BA_DEF_DEF_  "GenSigStartValue" 0;
BA_DEF_DEF_  "GenSigSendType" "NoSigSendType";
BA_DEF_DEF_  "GenSigILSupport" "Yes";
BA_DEF_DEF_  "SPN" 0;
BA_DEF_DEF_  "J1939CPgSendTimeout" -1;
BA_DEF_DEF_  "J1939CPgTOS" 2;
BA_DEF_DEF_  "J1939PgAppearanceOnBus" "Default";
BA_DEF_DEF_  "FsJ1939UseCrcAndCounter" "";
BA_DEF_DEF_  "TpJ1939VarDlc" "No";
BA_DEF_DEF_  "GenMsgNrOfRepetition" 0;
BA_DEF_DEF_  "GenMsgCycleTimeFast" 0;
BA_DEF_DEF_  "GenMsgFastOnStart" 0;
BA_DEF_DEF_  "GenMsgStartDelayTime" 0;
BA_DEF_DEF_  "GenMsgILSupport" "Yes";
BA_DEF_DEF_  "GenMsgDelayTime" 0;
BA_DEF_DEF_  "GenMsgRequestable" 1;
BA_DEF_DEF_  "GenMsgSendType" "noMsgSendType";
BA_DEF_DEF_  "VFrameFormat" "J1939PG";
BA_DEF_DEF_  "SingleFrame" 1;
BA_DEF_DEF_  "GenMsgCycleTime" 0;
BA_DEF_DEF_  "SystemSignalLongSymbol" "";
BA_ "GenMsgSendType" BO_ 2364544766 0;
BA_ "GenMsgCycleTime" BO_ 2364544766 5000;
BA_ "GenMsgSendType" BO_ 2364544510 0;
BA_ "GenMsgCycleTime" BO_ 2364544510 100;
BA_ "GenMsgSendType" BO_ 2364544254 0;
BA_ "GenMsgCycleTime" BO_ 2364544254 50;
BA_ "GenMsgSendType" BO_ 2550333182 0;
BA_ "GenMsgCycleTime" BO_ 2550333182 10;
BA_ "GenMsgSendType" BO_ 2566834686 0;
BA_ "GenMsgCycleTime" BO_ 2566834686 100;
BA_ "GenMsgSendType" BO_ 2550398718 0;
BA_ "GenMsgCycleTime" BO_ 2550398718 10;
BA_ "GenMsgSendType" BO_ 2566833406 0;
BA_ "GenMsgCycleTime" BO_ 2566833406 100;
BA_ "GenMsgSendType" BO_ 2566833918 0;
BA_ "GenMsgCycleTime" BO_ 2566833918 100;
BA_ "GenMsgSendType" BO_ 2565013246 0;
BA_ "GenMsgCycleTime" BO_ 2565013246 100;
BA_ "GenMsgSendType" BO_ 2566807038 0;
BA_ "GenMsgCycleTime" BO_ 2566807038 500;
BA_ "GenMsgSendType" BO_ 2566807550 0;
BA_ "GenMsgCycleTime" BO_ 2566807550 50;
BA_ "GenMsgSendType" BO_ 2566808062 0;
BA_ "GenMsgCycleTime" BO_ 2566808062 100;
BA_ "GenMsgSendType" BO_ 2566808574 0;
BA_ "GenMsgCycleTime" BO_ 2566808574 1000;
BA_ "GenMsgSendType" BO_ 2566809086 0;
BA_ "GenMsgCycleTime" BO_ 2566809086 1000;
BA_ "GenMsgSendType" BO_ 2564947710 0;
BA_ "GenMsgCycleTime" BO_ 2564947710 100;
BA_ "GenMsgSendType" BO_ 2566834430 0;
BA_ "GenMsgCycleTime" BO_ 2566834430 100;
BA_ "GenMsgSendType" BO_ 2566807806 0;
BA_ "GenMsgCycleTime" BO_ 2566807806 100;
BA_ "GenMsgSendType" BO_ 2566808318 0;
BA_ "GenMsgCycleTime" BO_ 2566808318 100;
BA_ "GenMsgSendType" BO_ 2566808830 0;
BA_ "GenMsgCycleTime" BO_ 2566808830 100;
BA_ "GenMsgRequestable" BO_ 2564554494 0;
BA_ "GenMsgRequestable" BO_ 2564488958 0;
BA_ "GenMsgSendType" BO_ 2565144318 0;
BA_ "GenMsgCycleTime" BO_ 2565144318 100;
BA_ "GenMsgSendType" BO_ 2565209854 0;
BA_ "GenMsgCycleTime" BO_ 2565209854 100;
BA_ "GenMsgSendType" BO_ 2566806782 0;
BA_ "GenMsgCycleTime" BO_ 2566806782 100;
BA_ "GenMsgSendType" BO_ 2566807294 0;
BA_ "GenMsgCycleTime" BO_ 2566807294 1000;
BA_ "TpJ1939VarDlc" BO_ 2564095742 1;
BA_ "FsJ1939UseCrcAndCounter" BO_ 2349137662 "Cd";
BA_ "GenMsgCycleTime" BO_ 2349137662 20;
BA_ "GenMsgDelayTime" BO_ 2566848510 1000;
BA_ "GenMsgSendType" BO_ 2566848510 0;
BA_ "GenMsgCycleTime" BO_ 2566848510 10000;
BA_ "GenMsgSendType" BO_ 2566804222 0;
BA_ "GenMsgCycleTime" BO_ 2566804222 100;
BA_ "GenMsgSendType" BO_ 2566819326 0;
BA_ "GenMsgCycleTime" BO_ 2566819326 1000;
BA_ "GenMsgSendType" BO_ 2566845438 0;
BA_ "GenMsgCycleTime" BO_ 2566845438 1000;
BA_ "TpJ1939VarDlc" BO_ 2566843646 1;
BA_ "GenMsgSendType" BO_ 2566809854 0;
BA_ "GenMsgCycleTime" BO_ 2566809854 1000;
BA_ "GenMsgSendType" BO_ 2566842622 0;
BA_ "GenMsgCycleTime" BO_ 2566842622 1000;
BA_ "GenMsgSendType" BO_ 2566832638 0;
BA_ "GenMsgCycleTime" BO_ 2566832638 1000;
BA_ "GenMsgSendType" BO_ 2565868030 0;
BA_ "GenMsgCycleTime" BO_ 2565868030 10;
BA_ "GenMsgSendType" BO_ 2566803454 0;
BA_ "GenMsgCycleTime" BO_ 2566803454 100;
BA_ "GenMsgSendType" BO_ 2566840574 0;
BA_ "GenMsgCycleTime" BO_ 2566840574 100;
BA_ "FsJ1939UseCrcAndCounter" BO_ 2348875518 "Ef";
BA_ "GenMsgSendType" BO_ 2348875518 0;
BA_ "GenMsgCycleTime" BO_ 2348875518 10;
BA_ "TpJ1939VarDlc" BO_ 2566766590 1;
BA_ "TpJ1939VarDlc" BO_ 2566766334 1;
BA_ "SigType" SG_ 2364544766 EngCyl24CombustionStatus 5;
BA_ "SPN" SG_ 2364544766 EngCyl24CombustionStatus 3410;
BA_ "SigType" SG_ 2364544766 EngCyl23CombustionStatus 5;
BA_ "SPN" SG_ 2364544766 EngCyl23CombustionStatus 3409;
BA_ "SigType" SG_ 2364544766 EngCyl22CombustionStatus 5;
BA_ "SPN" SG_ 2364544766 EngCyl22CombustionStatus 3408;
BA_ "SigType" SG_ 2364544766 EngCyl21CombustionStatus 5;
BA_ "SPN" SG_ 2364544766 EngCyl21CombustionStatus 3407;
BA_ "SigType" SG_ 2364544766 EngCyl20CombustionStatus 5;
BA_ "SPN" SG_ 2364544766 EngCyl20CombustionStatus 3406;
BA_ "SigType" SG_ 2364544766 EngCyl19CombustionStatus 5;
BA_ "SPN" SG_ 2364544766 EngCyl19CombustionStatus 3405;
BA_ "SigType" SG_ 2364544766 EngCyl18CombustionStatus 5;
BA_ "SPN" SG_ 2364544766 EngCyl18CombustionStatus 3404;
BA_ "SigType" SG_ 2364544766 EngCyl17CombustionStatus 5;
BA_ "SPN" SG_ 2364544766 EngCyl17CombustionStatus 3403;
BA_ "SigType" SG_ 2364544766 EngCyl16CombustionStatus 5;
BA_ "SPN" SG_ 2364544766 EngCyl16CombustionStatus 3402;
BA_ "SigType" SG_ 2364544766 EngCyl15CombustionStatus 5;
BA_ "SPN" SG_ 2364544766 EngCyl15CombustionStatus 3401;
BA_ "SigType" SG_ 2364544766 EngCyl14CombustionStatus 5;
BA_ "SPN" SG_ 2364544766 EngCyl14CombustionStatus 3400;
BA_ "SigType" SG_ 2364544766 EngCyl13CombustionStatus 5;
BA_ "SPN" SG_ 2364544766 EngCyl13CombustionStatus 3399;
BA_ "SigType" SG_ 2364544766 EngCyl12CombustionStatus 5;
BA_ "SPN" SG_ 2364544766 EngCyl12CombustionStatus 3398;
BA_ "SigType" SG_ 2364544766 EngCyl11CombustionStatus 5;
BA_ "SPN" SG_ 2364544766 EngCyl11CombustionStatus 3397;
BA_ "SigType" SG_ 2364544766 EngCyl10CombustionStatus 5;
BA_ "SPN" SG_ 2364544766 EngCyl10CombustionStatus 3396;
BA_ "SigType" SG_ 2364544766 EngCyl9CombustionStatus 5;
BA_ "SPN" SG_ 2364544766 EngCyl9CombustionStatus 3395;
BA_ "SigType" SG_ 2364544766 EngCyl8CombustionStatus 5;
BA_ "SPN" SG_ 2364544766 EngCyl8CombustionStatus 3394;
BA_ "SigType" SG_ 2364544766 EngCyl7CombustionStatus 5;
BA_ "SPN" SG_ 2364544766 EngCyl7CombustionStatus 3393;
BA_ "SigType" SG_ 2364544766 EngCyl6CombustionStatus 5;
BA_ "SPN" SG_ 2364544766 EngCyl6CombustionStatus 3392;
BA_ "SigType" SG_ 2364544766 EngCyl5CombustionStatus 5;
BA_ "SPN" SG_ 2364544766 EngCyl5CombustionStatus 3391;
BA_ "SigType" SG_ 2364544766 EngCyl4CombustionStatus 5;
BA_ "SPN" SG_ 2364544766 EngCyl4CombustionStatus 3390;
BA_ "SigType" SG_ 2364544766 EngCyl3CombustionStatus 5;
BA_ "SPN" SG_ 2364544766 EngCyl3CombustionStatus 3389;
BA_ "SigType" SG_ 2364544766 EngCyl2CombustionStatus 5;
BA_ "SPN" SG_ 2364544766 EngCyl2CombustionStatus 3388;
BA_ "SigType" SG_ 2364544766 EngCyl1CombustionStatus 5;
BA_ "SPN" SG_ 2364544766 EngCyl1CombustionStatus 3387;
BA_ "SigType" SG_ 2364544510 RqGenOverallPowerFactorLagging 5;
BA_ "SPN" SG_ 2364544510 RqGenOverallPowerFactorLagging 3385;
BA_ "SigType" SG_ 2364544510 RqGeneratorOverallPowerFactor 1;
BA_ "SPN" SG_ 2364544510 RqGeneratorOverallPowerFactor 3384;
BA_ "SigType" SG_ 2364544510 RqGeneratorTotalACReactivePower 1;
BA_ "SPN" SG_ 2364544510 RqGeneratorTotalACReactivePower 3383;
BA_ "SigType" SG_ 2364544254 BladeRotationAngleFigureOfMerit 5;
BA_ "SPN" SG_ 2364544254 BladeRotationAngleFigureOfMerit 3332;
BA_ "SigType" SG_ 2364544254 RelativeBladeHeightFigureOfMerit 5;
BA_ "SPN" SG_ 2364544254 RelativeBladeHeightFigureOfMerit 3367;
BA_ "SigType" SG_ 2364544254 RltvBldHghtAndBldRttnAnglMsrmntL 1;
BA_ "SPN" SG_ 2364544254 RltvBldHghtAndBldRttnAnglMsrmntL 3366;
BA_ "SigType" SG_ 2364544254 BladeRotationAngle 1;
BA_ "SPN" SG_ 2364544254 BladeRotationAngle 3331;
BA_ "SigType" SG_ 2364544254 RelativeBladeHeight 1;
BA_ "SPN" SG_ 2364544254 RelativeBladeHeight 3365;
BA_ "SigType" SG_ 2550333182 BrakeLightSwitch 4;
BA_ "SigType" SG_ 2550333182 ASREngineControlStatus 4;
BA_ "SigType" SG_ 2550333182 ASRBreakControlStatus 4;
BA_ "SigType" SG_ 2550333182 VehicleRetarderCtrlStatus 4;
BA_ "SigType" SG_ 2550333182 VehicleABSStatus 4;
BA_ "SigType" SG_ 2566834686 RoadCurvature 1;
BA_ "SPN" SG_ 2566834686 RoadCurvature 1591;
BA_ "SigType" SG_ 2566834686 PneumaticControlLineStatus 4;
BA_ "SigType" SG_ 2566834686 ABSOffroadRequest 4;
BA_ "SigType" SG_ 2566834686 TwoElCircuitsBrakeDemandStatus 4;
BA_ "SigType" SG_ 2566834686 VehicleRetarderCtrlStatus 4;
BA_ "GenSigStartValue" SG_ 2550398718 LateralAcceleration 125;
BA_ "SigType" SG_ 2550398718 RetarderRelativePeakTorque 1;
BA_ "SigType" SG_ 2550398718 VDCActive 4;
BA_ "SigType" SG_ 2550398718 AutomTowedVehicleBreakStatus 4;
BA_ "SigType" SG_ 2550398718 VehicleServiceBrakeStatus 4;
BA_ "SigType" SG_ 2550398718 VehicleRetarderCtrlStatus 4;
BA_ "SigType" SG_ 2550398718 VehicleABSStatus 4;
BA_ "SigType" SG_ 2566833406 ReferenceRetarderTorque 1;
BA_ "SPN" SG_ 2566833406 ReferenceRetarderTorque 556;
BA_ "SigType" SG_ 2566833406 SupplyLineBraking 4;
BA_ "SigType" SG_ 2566833406 LoadingRampApprAssistStatus 4;
BA_ "SigType" SG_ 2566833406 SpringBrakeStatus 4;
BA_ "SigType" SG_ 2566833406 ElectrLoadPropFuncInstalStatus 4;
BA_ "SigType" SG_ 2566833406 SpringBrakeInstallationStatus 4;
BA_ "SigType" SG_ 2566833406 ElectSupplyOfNonBrakingSysStatus 4;
BA_ "SigType" SG_ 2566833406 AmberWarningSignalReq 4;
BA_ "SigType" SG_ 2566833406 RedWarningSignalRequest 4;
BA_ "SigType" SG_ 2566833406 VehicleElectrSupplyStatus 4;
BA_ "SigType" SG_ 2566833406 AutomTowedVehicleBreakStatus 4;
BA_ "SigType" SG_ 2566833406 VehicleServiceBrakeStatus 4;
BA_ "SigType" SG_ 2566833406 VehicleRetarderCtrlStatus 4;
BA_ "SigType" SG_ 2566833406 VehicleABSStatus 4;
BA_ "SigType" SG_ 2566833918 VehiclePneumSupplyStatus 4;
BA_ "SigType" SG_ 2566833918 BrakeTemperatureStatus 4;
BA_ "SigType" SG_ 2566833918 BrakeLiningStatus 4;
BA_ "SigType" SG_ 2566833918 TyrePressureStatus 4;
BA_ "GenSigStartValue" SG_ 2565013246 ArticulationAngleDrawbarTowed 32000;
BA_ "GenSigStartValue" SG_ 2565013246 ArticulationAngleTowingDrawbar 32000;
BA_ "GenSigStartValue" SG_ 2565013246 ArticulationAngleTowingTowed 32000;
BA_ "SigType" SG_ 2565013246 ODDRequest 4;
BA_ "SigType" SG_ 2565013246 AntiTheftDeviceReq 4;
BA_ "SigType" SG_ 2566807038 MaxVehicleSpeedLimit 1;
BA_ "SPN" SG_ 2566807038 MaxVehicleSpeedLimit 74;
BA_ "SigType" SG_ 2566807550 TachographVehicleSpeed 1;
BA_ "SPN" SG_ 2566807550 TachographVehicleSpeed 1624;
BA_ "SigType" SG_ 2566807550 EngPercentLoadAtCurrentSpeed 1;
BA_ "SPN" SG_ 2566807550 EngPercentLoadAtCurrentSpeed 92;
BA_ "SigType" SG_ 2566807550 ActualEngPercentTorque 1;
BA_ "GenSigStartValue" SG_ 2566807550 ActualEngPercentTorque 125;
BA_ "SPN" SG_ 2566807550 ActualEngPercentTorque 513;
BA_ "SigType" SG_ 2566807550 DriversDemandEngPercentTorque 1;
BA_ "GenSigStartValue" SG_ 2566807550 DriversDemandEngPercentTorque 125;
BA_ "SPN" SG_ 2566807550 DriversDemandEngPercentTorque 512;
BA_ "SPN" SG_ 2566807550 EngTorqueMode 899;
BA_ "SigType" SG_ 2566807550 EngineSpeed 1;
BA_ "SigType" SG_ 2566807550 EngineRunning 4;
BA_ "SigType" SG_ 2566807550 EngineControlAllowed 4;
BA_ "SigType" SG_ 2566808062 TransCurrentGear 1;
BA_ "SPN" SG_ 2566808062 TransCurrentGear 523;
BA_ "SigType" SG_ 2566808062 ClutchIndptdPTOFeedback 4;
BA_ "SigType" SG_ 2566808062 AccelPedalPosition 1;
BA_ "SigType" SG_ 2566808062 AccelPedalLowIdleSwitch 4;
BA_ "SigType" SG_ 2566808062 StarterActive 4;
BA_ "SigType" SG_ 2566808062 PTOControlAllowed 4;
BA_ "SigType" SG_ 2566808062 SecEngineMtdPTOFeedback 4;
BA_ "SigType" SG_ 2566808062 FirstEngineMtdPTOFeedback 4;
BA_ "SigType" SG_ 2566808062 SecClutchDptdPTOFeedback 4;
BA_ "SigType" SG_ 2566808062 FirstClutchDpdtPTOFeedback 4;
BA_ "SigType" SG_ 2566808062 PercentClutchSlip 1;
BA_ "SPN" SG_ 2566808062 PercentClutchSlip 522;
BA_ "SigType" SG_ 2566808574 ReferenceTrq 1;
BA_ "SPN" SG_ 2566808574 ReferenceTrq 7778;
BA_ "SigType" SG_ 2566808574 EngOilPress 1;
BA_ "SPN" SG_ 2566808574 EngOilPress 100;
BA_ "SigType" SG_ 2566808574 FuelLevelWarning 4;
BA_ "SigType" SG_ 2566808574 EngineOilPressureWarning 4;
BA_ "SigType" SG_ 2566808574 EngCoolantTemp 1;
BA_ "SPN" SG_ 2566808574 EngCoolantTemp 110;
BA_ "SigType" SG_ 2566808574 EngineOilTemperature 1;
BA_ "SigType" SG_ 2566809086 AmbientAirTemp 1;
BA_ "SPN" SG_ 2566809086 AmbientAirTemp 171;
BA_ "GenSigStartValue" SG_ 2564947710 ArticulationAngleDrawbarTowed 32000;
BA_ "GenSigStartValue" SG_ 2564947710 ArticulationAngleTowingTowed 32000;
BA_ "SigType" SG_ 2566834430 AntiTheftDeviceStatus 4;
BA_ "SigType" SG_ 2566834430 ODDStatus 4;
BA_ "SigType" SG_ 2566808318 SecEngineMtdPTOSwitch 4;
BA_ "SigType" SG_ 2566808318 SecClutchDpdtPTOSwitch 4;
BA_ "SigType" SG_ 2566808318 FirstClutchDpdtPTOSwitch 4;
BA_ "SigType" SG_ 2566808318 OperatingPanelActive 4;
BA_ "SigType" SG_ 2566808318 RefusePackerStepSwitch 4;
BA_ "SigType" SG_ 2566808318 EngineStopSwitch 4;
BA_ "SigType" SG_ 2566808318 EngineStartSwitch 4;
BA_ "SigType" SG_ 2566808318 StarterLockoutSwitch 4;
BA_ "SigType" SG_ 2566808318 RqstedPercentClutchSlip 1;
BA_ "SigType" SG_ 2566808318 FirstEngineMtdPTOSwitch 4;
BA_ "SigType" SG_ 2566808318 ClutchIndpdtPTOSwitch 4;
BA_ "SigType" SG_ 2566808830 TowedVehicleLeftSideMarkerLight 4;
BA_ "SigType" SG_ 2566808830 TowedVehicleLeftReversingLight 4;
BA_ "SigType" SG_ 2566808830 TowedVehicleLeftRearWidIndLight 4;
BA_ "SigType" SG_ 2566808830 TowedVehicleLeftRearRegPltLight 4;
BA_ "SigType" SG_ 2566808830 TowedVehicleLeftRearLight 4;
BA_ "SigType" SG_ 2566808830 TowedVehicleLeftRearFogLight 4;
BA_ "SigType" SG_ 2566808830 TowedVehicleLeftDirIndLight 4;
BA_ "SigType" SG_ 2566808830 TowedVehicleLeftCrnMarkerLight 4;
BA_ "SigType" SG_ 2566808830 TowedVehicleInteriorLight 4;
BA_ "SigType" SG_ 2566808830 TowedVehicleWorkLight 4;
BA_ "SigType" SG_ 2566808830 TowedVehicleRotatingIdentLight 4;
BA_ "SigType" SG_ 2566808830 TowedVehicleRightStopLight 4;
BA_ "SigType" SG_ 2566808830 TowedVehicleRightSideMrkLight 4;
BA_ "SigType" SG_ 2566808830 TowedVehicleRightReversingLight 4;
BA_ "SigType" SG_ 2566808830 TowedVehicleRearWidIndLight 4;
BA_ "SigType" SG_ 2566808830 TowedVehicleRightRearRegPltLight 4;
BA_ "SigType" SG_ 2566808830 TowedVehicleRightRearLight 4;
BA_ "SigType" SG_ 2566808830 TowedVehicleRightRearFogLight 4;
BA_ "SigType" SG_ 2566808830 TowedVehicleRightDirIndLight 4;
BA_ "SigType" SG_ 2566808830 TowedVehicleRightCrnMarkerLight 4;
BA_ "SigType" SG_ 2566808830 TowedVehicleRearWarningLight 4;
BA_ "SigType" SG_ 2566808830 TowedVehicleLeftStopLight 4;
BA_ "SPN" SG_ 2565734142 NumberOfSA_NAMEPairs 5602;
BA_ "SPN" SG_ 2565734142 ToPort 5594;
BA_ "SigType" SG_ 2565734142 NetworkMessageControlByte 1;
BA_ "SPN" SG_ 2565734142 NetworkMessageControlByte 5592;
BA_ "SigType" SG_ 2565734142 FilterMode 1;
BA_ "SPN" SG_ 2565734142 FilterMode 5596;
BA_ "SPN" SG_ 2565734142 NIECUPort 5593;
BA_ "SPN" SG_ 2565734142 FromPort 5595;
BA_ "SigType" SG_ 2565144318 LiftAxle5PositionReq 4;
BA_ "SigType" SG_ 2565144318 LiftAxle4PositionReq 4;
BA_ "SigType" SG_ 2565144318 LiftAxle3PositionReq 4;
BA_ "SigType" SG_ 2565144318 ParkingAndTrailerAirPress 1;
BA_ "SigType" SG_ 2565144318 AuxEquipSupplyPressure 1;
BA_ "SigType" SG_ 2565144318 StopLevelChangeReq 4;
BA_ "SigType" SG_ 2565144318 RampLevelStorageReq 4;
BA_ "SigType" SG_ 2565144318 LevelControlReq 4;
BA_ "SigType" SG_ 2565144318 RampLevelReq 4;
BA_ "SigType" SG_ 2565144318 SteeringAxleLockingReq 4;
BA_ "SigType" SG_ 2565144318 LiftAxle2PositionReq 4;
BA_ "SigType" SG_ 2565144318 LiftAxle1PositionReq 4;
BA_ "SigType" SG_ 2565144318 TractionHelpReq 4;
BA_ "SigType" SG_ 2565144318 LevelChangeReqRearAxle 4;
BA_ "SigType" SG_ 2565144318 LevelChangeReqFrontAxle 4;
BA_ "SigType" SG_ 2565144318 RideHeightRequest 4;
BA_ "SigType" SG_ 2565209854 LevelControl 4;
BA_ "SigType" SG_ 2565209854 RampLevel 4;
BA_ "SigType" SG_ 2565209854 NormalLevel 4;
BA_ "SigType" SG_ 2565209854 StopLevelChangeAcknowledge 4;
BA_ "SigType" SG_ 2565209854 LevelChangeRearAxle 4;
BA_ "SigType" SG_ 2565209854 LevelChangeFrontAxle 4;
BA_ "SigType" SG_ 2565209854 RampLevelStorage 4;
BA_ "SigType" SG_ 2565209854 SteeringAxleLockingStatus 4;
BA_ "SigType" SG_ 2565209854 LiftAxle2Pos 4;
BA_ "SPN" SG_ 2565209854 LiftAxle2Pos 1822;
BA_ "SigType" SG_ 2565209854 LiftAxle1Pos 4;
BA_ "SPN" SG_ 2565209854 LiftAxle1Pos 1743;
BA_ "SigType" SG_ 2565209854 RampLevelPosition 4;
BA_ "SigType" SG_ 2565209854 TractionHelpStatus 4;
BA_ "SigType" SG_ 2565209854 RideHeightLevel 4;
BA_ "SigType" SG_ 2566807294 TyreModulePowerSupplyStatus 4;
BA_ "SystemSignalLongSymbol" SG_ 2566764798 NOxConvertingCatalystAdsorberEna "NOxConvertingCatalystAdsorberEnabled";
BA_ "SystemSignalLongSymbol" SG_ 2566764798 BoostPressureControlSystemComple "BoostPressureControlSystemCompleted";
BA_ "SystemSignalLongSymbol" SG_ 2566764798 BoostPressureControlSystemEnable "BoostPressureControlSystemEnabled";
BA_ "SigType" SG_ 2566764798 NumOfWarmUpsSinceDTCsCleared 1;
BA_ "SPN" SG_ 2566764798 NumOfWarmUpsSinceDTCsCleared 3302;
BA_ "SigType" SG_ 2566764798 TimeSinceEngineStart 1;
BA_ "SPN" SG_ 2566764798 TimeSinceEngineStart 3301;
BA_ "SPN" SG_ 2564095742 DataSecurityParameter 1597;
BA_ "SPN" SG_ 2564095742 SecurityEntityType 1479;
BA_ "SPN" SG_ 2564095742 SecurityEntityLength 1596;
BA_ "SigType" SG_ 2349137662 XBRBrkHoldReq 5;
BA_ "SPN" SG_ 2349137662 XBRBrkHoldReq 15263;
BA_ "SigType" SG_ 2349137662 XBRCompensationMode 5;
BA_ "SPN" SG_ 2349137662 XBRCompensationMode 15201;
BA_ "SigType" SG_ 2349137662 XBRMessageChecksum 12;
BA_ "SPN" SG_ 2349137662 XBRMessageChecksum 3188;
BA_ "SigType" SG_ 2349137662 XBRMessageCounter 11;
BA_ "SPN" SG_ 2349137662 XBRMessageCounter 3189;
BA_ "SigType" SG_ 2349137662 XBRUrgency 1;
BA_ "SPN" SG_ 2349137662 XBRUrgency 4099;
BA_ "SigType" SG_ 2349137662 XBRCtrlMode 5;
BA_ "SPN" SG_ 2349137662 XBRCtrlMode 2916;
BA_ "SigType" SG_ 2349137662 XBRPriority 5;
BA_ "SPN" SG_ 2349137662 XBRPriority 2915;
BA_ "SigType" SG_ 2349137662 XBREBIMode 5;
BA_ "SPN" SG_ 2349137662 XBREBIMode 2914;
BA_ "SigType" SG_ 2349137662 ExtlAccelerationDemand 1;
BA_ "GenSigStartValue" SG_ 2349137662 ExtlAccelerationDemand 11647;
BA_ "SPN" SG_ 2349137662 ExtlAccelerationDemand 2920;
BA_ "SPN" SG_ 2566848510 EngSvcInd 22138;
BA_ "SPN" SG_ 2566848510 EmissionCtrlSysOpSpdIndSev 20921;
BA_ "SPN" SG_ 2566848510 EmissionCtrlSysOpTrqIndSev 20920;
BA_ "SigType" SG_ 2566848510 StartReqInhInd 5;
BA_ "SPN" SG_ 2566848510 StartReqInhInd 20905;
BA_ "SPN" SG_ 2566848510 RecommendedNumOfGearsToShift 12959;
BA_ "SigType" SG_ 2566848510 EngOilLifeRemaining 1;
BA_ "SPN" SG_ 2566848510 EngOilLifeRemaining 355;
BA_ "SigType" SG_ 2566848510 AutoStartReqInhInd 5;
BA_ "SPN" SG_ 2566848510 AutoStartReqInhInd 9373;
BA_ "SigType" SG_ 2566848510 FuelSupplyEstRemainingDist 1;
BA_ "SPN" SG_ 2566848510 FuelSupplyEstRemainingDist 8428;
BA_ "SigType" SG_ 2566848510 WaterInChargeADAfterChargeACInd 4;
BA_ "SPN" SG_ 2566848510 WaterInChargeADAfterChargeACInd 8611;
BA_ "SigType" SG_ 2566848510 EngOverloadedInd 5;
BA_ "SPN" SG_ 2566848510 EngOverloadedInd 8612;
BA_ "SPN" SG_ 2566848510 EmssnCtrlSystmOprtrIndcmntSvrity 5826;
BA_ "SPN" SG_ 2566848510 DrvrWarningSystemIndicatorStatus 5825;
BA_ "SigType" SG_ 2566848510 OperatorShiftPrompt 5;
BA_ "SPN" SG_ 2566848510 OperatorShiftPrompt 5675;
BA_ "SigType" SG_ 2566848510 WaterInFuelIndicator 4;
BA_ "SPN" SG_ 2566848510 WaterInFuelIndicator 97;
BA_ "SigType" SG_ 2566848510 WaterInFuelIndicator2 4;
BA_ "SPN" SG_ 2566848510 WaterInFuelIndicator2 6301;
BA_ "SPN" SG_ 2566843134 AxleLocation 928;
BA_ "SigType" SG_ 2566843134 CargoWeight_30 1;
BA_ "SPN" SG_ 2566843134 CargoWeight_30 522230;
BA_ "SigType" SG_ 2566843134 CargoWeight_20 1;
BA_ "SPN" SG_ 2566843134 CargoWeight_20 522220;
BA_ "SigType" SG_ 2566843134 CargoWeight_10 1;
BA_ "SPN" SG_ 2566843134 CargoWeight_10 522210;
BA_ "SigType" SG_ 2566843134 CargoWeight_00 1;
BA_ "SPN" SG_ 2566843134 CargoWeight_00 522200;
BA_ "SigType" SG_ 2566843134 TrailerWeight_30 1;
BA_ "SPN" SG_ 2566843134 TrailerWeight_30 522130;
BA_ "SigType" SG_ 2566843134 TrailerWeight_20 1;
BA_ "SPN" SG_ 2566843134 TrailerWeight_20 522120;
BA_ "SigType" SG_ 2566843134 TrailerWeight_10 1;
BA_ "SPN" SG_ 2566843134 TrailerWeight_10 522110;
BA_ "SigType" SG_ 2566843134 TrailerWeight_00 1;
BA_ "SPN" SG_ 2566843134 TrailerWeight_00 522100;
BA_ "SigType" SG_ 2566843134 AxleWeight_30 1;
BA_ "SPN" SG_ 2566843134 AxleWeight_30 522030;
BA_ "SigType" SG_ 2566843134 AxleWeight_20 1;
BA_ "SPN" SG_ 2566843134 AxleWeight_20 522020;
BA_ "SigType" SG_ 2566843134 AxleWeight_10 1;
BA_ "SPN" SG_ 2566843134 AxleWeight_10 522010;
BA_ "SigType" SG_ 2566843134 AxleWeight_00 1;
BA_ "SPN" SG_ 2566843134 AxleWeight_00 522000;
BA_ "SigType" SG_ 2566804222 ECUKeySwSt 4;
BA_ "SPN" SG_ 2566804222 ECUKeySwSt 22624;
BA_ "SigType" SG_ 2566804222 SLIBattery2NetCurrent 1;
BA_ "SPN" SG_ 2566804222 SLIBattery2NetCurrent 7498;
BA_ "SigType" SG_ 2566804222 NetBatteryCurrent 1;
BA_ "SPN" SG_ 2566804222 NetBatteryCurrent 2579;
BA_ "SigType" SG_ 2566804222 AltCurrent 1;
BA_ "SPN" SG_ 2566804222 AltCurrent 1795;
BA_ "SigType" SG_ 2566819326 ECUPowerOutputSupplyVoltage3 1;
BA_ "SPN" SG_ 2566819326 ECUPowerOutputSupplyVoltage3 3599;
BA_ "SigType" SG_ 2566819326 ECUPowerOutputSupplyVoltage2 1;
BA_ "SPN" SG_ 2566819326 ECUPowerOutputSupplyVoltage2 3598;
BA_ "SigType" SG_ 2566819326 ECUPowerOutputSupplyVoltage1 1;
BA_ "SPN" SG_ 2566819326 ECUPowerOutputSupplyVoltage1 3597;
BA_ "SigType" SG_ 2566819326 BatteryPotential_PowerInput2 1;
BA_ "SPN" SG_ 2566819326 BatteryPotential_PowerInput2 444;
BA_ "SigType" SG_ 2566845438 Longitude 1;
BA_ "SPN" SG_ 2566845438 Longitude 585;
BA_ "SigType" SG_ 2566845438 Latitude 1;
BA_ "SPN" SG_ 2566845438 Latitude 584;
BA_ "SigType" SG_ 2566843646 VehicleIdentificationNumber 8;
BA_ "SPN" SG_ 2566843646 VehicleIdentificationNumber 237;
BA_ "SigType" SG_ 2566842366 TotalPowerTakeoffHours 1;
BA_ "SPN" SG_ 2566842366 TotalPowerTakeoffHours 248;
BA_ "SigType" SG_ 2566842366 TotalVehicleHours 1;
BA_ "SPN" SG_ 2566842366 TotalVehicleHours 246;
BA_ "SigType" SG_ 2566809854 HydOilLevel 1;
BA_ "SPN" SG_ 2566809854 HydOilLevel 2602;
BA_ "SigType" SG_ 2566809854 WinchOilPressSwitch 4;
BA_ "SPN" SG_ 2566809854 WinchOilPressSwitch 1857;
BA_ "SigType" SG_ 2566809854 HydOilFilterRestrictionSwitch 4;
BA_ "SPN" SG_ 2566809854 HydOilFilterRestrictionSwitch 1713;
BA_ "SigType" SG_ 2566809854 HydTemp 1;
BA_ "SPN" SG_ 2566809854 HydTemp 1638;
BA_ "SigType" SG_ 2566842622 Altitude 1;
BA_ "SPN" SG_ 2566842622 Altitude 580;
BA_ "SigType" SG_ 2566842622 Pitch 1;
BA_ "SPN" SG_ 2566842622 Pitch 583;
BA_ "SigType" SG_ 2566842622 NavigationBasedVehicleSpeed 1;
BA_ "SPN" SG_ 2566842622 NavigationBasedVehicleSpeed 517;
BA_ "SigType" SG_ 2566842622 CompassBearing 1;
BA_ "SPN" SG_ 2566842622 CompassBearing 165;
BA_ "SigType" SG_ 2566832638 HighResolutionTripDistance 1;
BA_ "SPN" SG_ 2566832638 HighResolutionTripDistance 918;
BA_ "SigType" SG_ 2566832638 HghRsolutionTotalVehicleDistance 1;
BA_ "SPN" SG_ 2566832638 HghRsolutionTotalVehicleDistance 917;
BA_ "SigType" SG_ 2565868030 LongitudinalAcceleration 1;
BA_ "SPN" SG_ 2565868030 LongitudinalAcceleration 1810;
BA_ "SigType" SG_ 2565868030 LateralAcceleration 1;
BA_ "SPN" SG_ 2565868030 LateralAcceleration 1809;
BA_ "SigType" SG_ 2565868030 YawRate 1;
BA_ "SPN" SG_ 2565868030 YawRate 1808;
BA_ "SigType" SG_ 2565868030 SteerWheelAngleSensorType 5;
BA_ "SPN" SG_ 2565868030 SteerWheelAngleSensorType 1812;
BA_ "GenSigStartValue" SG_ 2565868030 SteerWheelTurnCounter 22;
BA_ "SPN" SG_ 2565868030 SteerWheelTurnCounter 1811;
BA_ "SigType" SG_ 2565868030 SteerWheelAngle 1;
BA_ "SPN" SG_ 2565868030 SteerWheelAngle 1807;
BA_ "SigType" SG_ 2566803454 TrailerVDCActive 5;
BA_ "SPN" SG_ 2566803454 TrailerVDCActive 5624;
BA_ "SigType" SG_ 2566803454 YCBrakeCtrlActive 5;
BA_ "SPN" SG_ 2566803454 YCBrakeCtrlActive 1819;
BA_ "SigType" SG_ 2566803454 YCEngCtrlActive 5;
BA_ "SPN" SG_ 2566803454 YCEngCtrlActive 1817;
BA_ "SigType" SG_ 2566803454 ROPBrakeCtrlActive 5;
BA_ "SPN" SG_ 2566803454 ROPBrakeCtrlActive 1818;
BA_ "SigType" SG_ 2566803454 ROPEngCtrlActive 5;
BA_ "SPN" SG_ 2566803454 ROPEngCtrlActive 1816;
BA_ "SigType" SG_ 2566803454 VDCBrakeLightRq 5;
BA_ "SPN" SG_ 2566803454 VDCBrakeLightRq 1815;
BA_ "SigType" SG_ 2566803454 VDCFullyOperational 5;
BA_ "SPN" SG_ 2566803454 VDCFullyOperational 1814;
BA_ "SigType" SG_ 2566803454 VDCInformationSignal 5;
BA_ "SPN" SG_ 2566803454 VDCInformationSignal 1813;
BA_ "SigType" SG_ 2566840574 TotalVehicleDistance 1;
BA_ "SPN" SG_ 2566840574 TotalVehicleDistance 245;
BA_ "SigType" SG_ 2566840574 TripDistance 1;
BA_ "SPN" SG_ 2566840574 TripDistance 244;
BA_ "SigType" SG_ 2633938686 TripCruiseDistance 1;
BA_ "SPN" SG_ 2633938686 TripCruiseDistance 1019;
BA_ "SigType" SG_ 2633938686 TripMaxVehicleSpeed 1;
BA_ "SPN" SG_ 2633938686 TripMaxVehicleSpeed 1018;
BA_ "SigType" SG_ 2633937150 TripAirCompressorOnTime 1;
BA_ "SPN" SG_ 2633937150 TripAirCompressorOnTime 1038;
BA_ "SigType" SG_ 2633937150 TripIdleTime 1;
BA_ "SPN" SG_ 2633937150 TripIdleTime 1037;
BA_ "SigType" SG_ 2633937150 TripEngRunningTime 1;
BA_ "SPN" SG_ 2633937150 TripEngRunningTime 1036;
BA_ "SigType" SG_ 2633937150 TripCruiseTime 1;
BA_ "SPN" SG_ 2633937150 TripCruiseTime 1034;
BA_ "SigType" SG_ 2633937150 TripPTOGovernorTime 1;
BA_ "SPN" SG_ 2633937150 TripPTOGovernorTime 1035;
BA_ "SigType" SG_ 2633938174 TripTimeInDerateByEng 1;
BA_ "SPN" SG_ 2633938174 TripTimeInDerateByEng 1027;
BA_ "SigType" SG_ 2633938174 TripTimeInGearDown 1;
BA_ "SPN" SG_ 2633938174 TripTimeInGearDown 1026;
BA_ "SigType" SG_ 2633938174 TripTimeInTopGear 1;
BA_ "SPN" SG_ 2633938174 TripTimeInTopGear 1025;
BA_ "SigType" SG_ 2633938174 TripTimeInVSL 1;
BA_ "SPN" SG_ 2633938174 TripTimeInVSL 1024;
BA_ "SigType" SG_ 2633938430 TripSuddenDecelerations 1;
BA_ "SPN" SG_ 2633938430 TripSuddenDecelerations 1023;
BA_ "SigType" SG_ 2633938430 TrpNumberOfIdleShutdownOverrides 1;
BA_ "SPN" SG_ 2633938430 TrpNumberOfIdleShutdownOverrides 1022;
BA_ "SigType" SG_ 2633938430 TripNumberOfIdleShutdowns 1;
BA_ "SPN" SG_ 2633938430 TripNumberOfIdleShutdowns 1021;
BA_ "SigType" SG_ 2633938430 TripNumberOfHotShutdowns 1;
BA_ "SPN" SG_ 2633938430 TripNumberOfHotShutdowns 1020;
BA_ "SigType" SG_ 2348875518 MessageChecksum 12;
BA_ "SPN" SG_ 2348875518 MessageChecksum 4207;
BA_ "SigType" SG_ 2348875518 MessageCounter 11;
BA_ "SPN" SG_ 2348875518 MessageCounter 4206;
BA_ "SPN" SG_ 2348875518 EngRequestedTorqueHighResolution 4191;
BA_ "SPN" SG_ 2348875518 TSC1CtrlPurpose 3350;
BA_ "SPN" SG_ 2348875518 TSC1TransRate 3349;
BA_ "SigType" SG_ 2348875518 EngRequestedTorque_TorqueLimit 1;
BA_ "SPN" SG_ 2348875518 EngRequestedTorque_TorqueLimit 518;
BA_ "SigType" SG_ 2348875518 EngRequestedSpeed_SpeedLimit 1;
BA_ "SPN" SG_ 2348875518 EngRequestedSpeed_SpeedLimit 898;
BA_ "SigType" SG_ 2348875518 OverrideCtrlModePriority 5;
BA_ "SPN" SG_ 2348875518 OverrideCtrlModePriority 897;
BA_ "SigType" SG_ 2348875518 EngRequestedSpeedCtrlConditions 5;
BA_ "SPN" SG_ 2348875518 EngRequestedSpeedCtrlConditions 696;
BA_ "SigType" SG_ 2348875518 EngOverrideCtrlMode 5;
BA_ "SPN" SG_ 2348875518 EngOverrideCtrlMode 695;
BA_ "SigType" SG_ 2566766846 TransitRunStatus 5;
BA_ "SPN" SG_ 2566766846 TransitRunStatus 3046;
BA_ "SigType" SG_ 2566766846 VehicleUseStatus 5;
BA_ "SPN" SG_ 2566766846 VehicleUseStatus 3045;
BA_ "SigType" SG_ 2566766846 SilentAlarmStatus 5;
BA_ "SPN" SG_ 2566766846 SilentAlarmStatus 3044;
BA_ "SigType" SG_ 2566766846 PatronCount 1;
BA_ "SPN" SG_ 2566766846 PatronCount 3047;
BA_ "SPN" SG_ 2566766846 TypeOfPassengerCount 3043;
BA_ "SPN" SG_ 2566765310 FareboxAlarmIdentifier 3181;
BA_ "SigType" SG_ 2566765310 FareboxEmergencyStatus 4;
BA_ "SPN" SG_ 2566765310 FareboxEmergencyStatus 3179;
BA_ "SPN" SG_ 2566765566 TransferSold 3168;
BA_ "SPN" SG_ 2566765566 TransferType 3173;
BA_ "SPN" SG_ 2566765566 TypeOfService 3172;
BA_ "GenSigStartValue" SG_ 2566765566 InitialFareAgency 1;
BA_ "SPN" SG_ 2566765566 InitialFareAgency 3167;
BA_ "SPN" SG_ 2566765566 PassCategory 3166;
BA_ "SPN" SG_ 2566765566 FareValidity 3165;
BA_ "SPN" SG_ 2566765566 PaymentDetails 3177;
BA_ "SPN" SG_ 2566765566 TypeOfFare 3176;
BA_ "SPN" SG_ 2566765566 PassengerType 3171;
BA_ "SPN" SG_ 2566765566 TransactionType 3170;
BA_ "SPN" SG_ 2566765566 RouteNumber 3169;
BA_ "SPN" SG_ 2566765822 DriversFareboxSecurityCode 3164;
BA_ "SPN" SG_ 2566765822 AssignedBlock 3163;
BA_ "SPN" SG_ 2566765822 AssignedRun 3162;
BA_ "SPN" SG_ 2566765822 AssignedRoute 3160;
BA_ "SPN" SG_ 2566765822 PatternNumber 3161;
BA_ "SPN" SG_ 2566765822 TripNumber 3159;
BA_ "SPN" SG_ 2566765822 FarePresets 3175;
BA_ "SPN" SG_ 2566765822 TripDirection 3174;
BA_ "SPN" SG_ 2566765822 TripStatus 3180;
BA_ "SigType" SG_ 2566765822 FareboxServiceStatus 4;
BA_ "SPN" SG_ 2566765822 FareboxServiceStatus 3178;
BA_ "SigType" SG_ 2566766078 VehicleID 1;
BA_ "SPN" SG_ 2566766078 VehicleID 3085;
BA_ "SigType" SG_ 2566766078 StrobeActivationCtrlStatus 4;
BA_ "SPN" SG_ 2566766078 StrobeActivationCtrlStatus 3082;
BA_ "SigType" SG_ 2566766078 TransitDoorEnable 4;
BA_ "SPN" SG_ 2566766078 TransitDoorEnable 3083;
BA_ "SPN" SG_ 2566766078 PriorityOfRespSentByEmitter 3084;
BA_ "SigType" SG_ 2566766078 IntrsctnPrmptionRequest_Response 4;
BA_ "SPN" SG_ 2566766078 IntrsctnPrmptionRequest_Response 3079;
BA_ "SigType" SG_ 2566766078 TransitRouteIDUsage 4;
BA_ "SPN" SG_ 2566766078 TransitRouteIDUsage 3080;
BA_ "SigType" SG_ 2566766078 RangeCodeEnable 4;
BA_ "SPN" SG_ 2566766078 RangeCodeEnable 3081;
BA_ "SigType" SG_ 2566766590 NmbrOfBytsInThMlpstIdntification 1;
BA_ "SPN" SG_ 2566766590 NmbrOfBytsInThMlpstIdntification 3070;
BA_ "SigType" SG_ 2566766334 NmbrOfBytsInThTrnstAssgndBlckIdn 1;
BA_ "GenSigStartValue" SG_ 2566766334 NmbrOfBytsInThTrnstAssgndBlckIdn 1;
BA_ "SPN" SG_ 2566766334 NmbrOfBytsInThTrnstAssgndBlckIdn 3073;
BA_ "SigType" SG_ 2566766334 NmbrOfBytsInThTrnstAssgndRnIdntt 1;
BA_ "GenSigStartValue" SG_ 2566766334 NmbrOfBytsInThTrnstAssgndRnIdntt 1;
BA_ "SPN" SG_ 2566766334 NmbrOfBytsInThTrnstAssgndRnIdntt 3072;
BA_ "SigType" SG_ 2566766334 NmbrOfBytsInThTrnstAssgndRtIdntt 1;
BA_ "GenSigStartValue" SG_ 2566766334 NmbrOfBytsInThTrnstAssgndRtIdntt 1;
BA_ "SPN" SG_ 2566766334 NmbrOfBytsInThTrnstAssgndRtIdntt 3071;
BA_ "SPN" SG_ 2566766334 Agency 3078;
BA_ "SPN" SG_ 2561605374 TireLocation 3192;
BA_ "SigType" SG_ 2561605374 ReferenceTirePressSetting_33 1;
BA_ "SPN" SG_ 2561605374 ReferenceTirePressSetting_33 521833;
BA_ "SigType" SG_ 2561605374 ReferenceTirePressSetting_32 1;
BA_ "SPN" SG_ 2561605374 ReferenceTirePressSetting_32 521832;
BA_ "SigType" SG_ 2561605374 ReferenceTirePressSetting_31 1;
BA_ "SPN" SG_ 2561605374 ReferenceTirePressSetting_31 521831;
BA_ "SigType" SG_ 2561605374 ReferenceTirePressSetting_30 1;
BA_ "SPN" SG_ 2561605374 ReferenceTirePressSetting_30 521830;
BA_ "SigType" SG_ 2561605374 ReferenceTirePressSetting_23 1;
BA_ "SPN" SG_ 2561605374 ReferenceTirePressSetting_23 521823;
BA_ "SigType" SG_ 2561605374 ReferenceTirePressSetting_22 1;
BA_ "SPN" SG_ 2561605374 ReferenceTirePressSetting_22 521822;
BA_ "SigType" SG_ 2561605374 ReferenceTirePressSetting_21 1;
BA_ "SPN" SG_ 2561605374 ReferenceTirePressSetting_21 521821;
BA_ "SigType" SG_ 2561605374 ReferenceTirePressSetting_20 1;
BA_ "SPN" SG_ 2561605374 ReferenceTirePressSetting_20 521820;
BA_ "SigType" SG_ 2561605374 ReferenceTirePressSetting_13 1;
BA_ "SPN" SG_ 2561605374 ReferenceTirePressSetting_13 521813;
BA_ "SigType" SG_ 2561605374 ReferenceTirePressSetting_12 1;
BA_ "SPN" SG_ 2561605374 ReferenceTirePressSetting_12 521812;
BA_ "SigType" SG_ 2561605374 ReferenceTirePressSetting_11 1;
BA_ "SPN" SG_ 2561605374 ReferenceTirePressSetting_11 521811;
BA_ "SigType" SG_ 2561605374 ReferenceTirePressSetting_10 1;
BA_ "SPN" SG_ 2561605374 ReferenceTirePressSetting_10 521810;
BA_ "SigType" SG_ 2561605374 ReferenceTirePressSetting_01 1;
BA_ "SPN" SG_ 2561605374 ReferenceTirePressSetting_01 521801;
BA_ "SigType" SG_ 2561605374 ReferenceTirePressSetting_00 1;
BA_ "SPN" SG_ 2561605374 ReferenceTirePressSetting_00 521800;
BA_ "SigType" SG_ 2566765054 ReferenceTirePress_33 1;
BA_ "SPN" SG_ 2566765054 ReferenceTirePress_33 521933;
BA_ "SigType" SG_ 2566765054 ReferenceTirePress_32 1;
BA_ "SPN" SG_ 2566765054 ReferenceTirePress_32 521932;
BA_ "SigType" SG_ 2566765054 ReferenceTirePress_31 1;
BA_ "SPN" SG_ 2566765054 ReferenceTirePress_31 521931;
BA_ "SigType" SG_ 2566765054 ReferenceTirePress_30 1;
BA_ "SPN" SG_ 2566765054 ReferenceTirePress_30 521930;
BA_ "SigType" SG_ 2566765054 ReferenceTirePress_23 1;
BA_ "SPN" SG_ 2566765054 ReferenceTirePress_23 521923;
BA_ "SigType" SG_ 2566765054 ReferenceTirePress_22 1;
BA_ "SPN" SG_ 2566765054 ReferenceTirePress_22 521922;
BA_ "SigType" SG_ 2566765054 ReferenceTirePress_21 1;
BA_ "SPN" SG_ 2566765054 ReferenceTirePress_21 521921;
BA_ "SigType" SG_ 2566765054 ReferenceTirePress_20 1;
BA_ "SPN" SG_ 2566765054 ReferenceTirePress_20 521920;
BA_ "SigType" SG_ 2566765054 ReferenceTirePress_13 1;
BA_ "SPN" SG_ 2566765054 ReferenceTirePress_13 521913;
BA_ "SigType" SG_ 2566765054 ReferenceTirePress_12 1;
BA_ "SPN" SG_ 2566765054 ReferenceTirePress_12 521912;
BA_ "SigType" SG_ 2566765054 ReferenceTirePress_11 1;
BA_ "SPN" SG_ 2566765054 ReferenceTirePress_11 521911;
BA_ "SigType" SG_ 2566765054 ReferenceTirePress_10 1;
BA_ "SPN" SG_ 2566765054 ReferenceTirePress_10 521910;
BA_ "SigType" SG_ 2566765054 ReferenceTirePress_01 1;
BA_ "SPN" SG_ 2566765054 ReferenceTirePress_01 521901;
BA_ "SigType" SG_ 2566765054 ReferenceTirePress_00 1;
BA_ "SPN" SG_ 2566765054 ReferenceTirePress_00 521900;
BA_ "SPN" SG_ 2566765054 TireLocation 3190;
BA_ "SigType" SG_ 2633923326 SteerChannelTirePress 1;
BA_ "SPN" SG_ 2633923326 SteerChannelTirePress 146;
BA_ "SigType" SG_ 2633923326 DriveChannelTirePress 1;
BA_ "SPN" SG_ 2633923326 DriveChannelTirePress 145;
BA_ "SigType" SG_ 2633923326 TrailerTagOrPushChannelTirePress 1;
BA_ "SPN" SG_ 2633923326 TrailerTagOrPushChannelTirePress 144;
BA_ "SigType" SG_ 2633923070 SteerChannelTirePressTarget 1;
BA_ "SPN" SG_ 2633923070 SteerChannelTirePressTarget 143;
BA_ "SigType" SG_ 2633923070 DriveChannelTirePressTarget 1;
BA_ "SPN" SG_ 2633923070 DriveChannelTirePressTarget 142;
BA_ "SigType" SG_ 2633923070 TrlrTgOrPshChnnelTirePressTarget 1;
BA_ "SPN" SG_ 2633923070 TrlrTgOrPshChnnelTirePressTarget 141;
BA_ "SigType" SG_ 2633922814 PCUTrilerTagOrPushSolenoidStatus 5;
BA_ "SPN" SG_ 2633922814 PCUTrilerTagOrPushSolenoidStatus 1475;
BA_ "SigType" SG_ 2633922814 PCUSupplySolenoidStatus 5;
BA_ "SPN" SG_ 2633922814 PCUSupplySolenoidStatus 1474;
BA_ "SigType" SG_ 2633922814 PCUCtrlSolenoidStatus 5;
BA_ "SPN" SG_ 2633922814 PCUCtrlSolenoidStatus 1473;
BA_ "SigType" SG_ 2633922814 PCUDeflateSolenoidStatus 5;
BA_ "SPN" SG_ 2633922814 PCUDeflateSolenoidStatus 1472;
BA_ "SigType" SG_ 2633922814 TirePressSupplySwitchStatus 5;
BA_ "SPN" SG_ 2633922814 TirePressSupplySwitchStatus 1471;
BA_ "SigType" SG_ 2633922814 PCUSteerSolenoidStatus 5;
BA_ "SPN" SG_ 2633922814 PCUSteerSolenoidStatus 1470;
BA_ "SigType" SG_ 2633922814 PCUDriveSolenoidStatus 5;
BA_ "SPN" SG_ 2633922814 PCUDriveSolenoidStatus 1469;
BA_ "SPN" SG_ 2633922814 DriveChannelMode 1468;
BA_ "SPN" SG_ 2633922814 Trailer_tagChannelMode 1467;
BA_ "SPN" SG_ 2633922814 SteerChannelMode 1466;
BA_ "SigType" SG_ 2633922814 TirePressCheckInterval 1;
BA_ "SPN" SG_ 2633922814 TirePressCheckInterval 39;
VAL_ 2364544766 EngCyl24CombustionStatus 3 "Not available" 2 "Error" 1 "Combustion exists" 0 "No combustion" ;
VAL_ 2364544766 EngCyl23CombustionStatus 3 "Not available" 2 "Error" 1 "Combustion exists" 0 "No combustion" ;
VAL_ 2364544766 EngCyl22CombustionStatus 3 "Not available" 2 "Error" 1 "Combustion exists" 0 "No combustion" ;
VAL_ 2364544766 EngCyl21CombustionStatus 3 "Not available" 2 "Error" 1 "Combustion exists" 0 "No combustion" ;
VAL_ 2364544766 EngCyl20CombustionStatus 3 "Not available" 2 "Error" 1 "Combustion exists" 0 "No combustion" ;
VAL_ 2364544766 EngCyl19CombustionStatus 3 "Not available" 2 "Error" 1 "Combustion exists" 0 "No combustion" ;
VAL_ 2364544766 EngCyl18CombustionStatus 3 "Not available" 2 "Error" 1 "Combustion exists" 0 "No combustion" ;
VAL_ 2364544766 EngCyl17CombustionStatus 3 "Not available" 2 "Error" 1 "Combustion exists" 0 "No combustion" ;
VAL_ 2364544766 EngCyl16CombustionStatus 3 "Not available" 2 "Error" 1 "Combustion exists" 0 "No combustion" ;
VAL_ 2364544766 EngCyl15CombustionStatus 3 "Not available" 2 "Error" 1 "Combustion exists" 0 "No combustion" ;
VAL_ 2364544766 EngCyl14CombustionStatus 3 "Not available" 2 "Error" 1 "Combustion exists" 0 "No combustion" ;
VAL_ 2364544766 EngCyl13CombustionStatus 3 "Not available" 2 "Error" 1 "Combustion exists" 0 "No combustion" ;
VAL_ 2364544766 EngCyl12CombustionStatus 3 "Not available" 2 "Error" 1 "Combustion exists" 0 "No combustion" ;
VAL_ 2364544766 EngCyl11CombustionStatus 3 "Not available" 2 "Error" 1 "Combustion exists" 0 "No combustion" ;
VAL_ 2364544766 EngCyl10CombustionStatus 3 "Not available" 2 "Error" 1 "Combustion exists" 0 "No combustion" ;
VAL_ 2364544766 EngCyl9CombustionStatus 3 "Not available" 2 "Error" 1 "Combustion exists" 0 "No combustion" ;
VAL_ 2364544766 EngCyl8CombustionStatus 3 "Not available" 2 "Error" 1 "Combustion exists" 0 "No combustion" ;
VAL_ 2364544766 EngCyl7CombustionStatus 3 "Not available" 2 "Error" 1 "Combustion exists" 0 "No combustion" ;
VAL_ 2364544766 EngCyl6CombustionStatus 3 "Not available" 2 "Error" 1 "Combustion exists" 0 "No combustion" ;
VAL_ 2364544766 EngCyl5CombustionStatus 3 "Not available" 2 "Error" 1 "Combustion exists" 0 "No combustion" ;
VAL_ 2364544766 EngCyl4CombustionStatus 3 "Not available" 2 "Error" 1 "Combustion exists" 0 "No combustion" ;
VAL_ 2364544766 EngCyl3CombustionStatus 3 "Not available" 2 "Error" 1 "Combustion exists" 0 "No combustion" ;
VAL_ 2364544766 EngCyl2CombustionStatus 3 "Not available" 2 "Error" 1 "Combustion exists" 0 "No combustion" ;
VAL_ 2364544766 EngCyl1CombustionStatus 3 "Not available" 2 "Error" 1 "Combustion exists" 0 "No combustion" ;
VAL_ 2364544510 RqGenOverallPowerFactorLagging 3 "Not available or Not installed" 2 "Reserved" 1 "Lagging" 0 "Leading" ;
VAL_ 2364544254 BladeRotationAngleFigureOfMerit 3 "Blade Rotation Angle not available" 2 "Blade Rotation Angle failed" 1 "Blade Rotation Angle  degraded" 0 "Blade Rotation Angle fully functional" ;
VAL_ 2364544254 RelativeBladeHeightFigureOfMerit 3 "Relative Blade Height not available" 2 "Relative Blade Height failed." 1 "Relative Blade Height degraded" 0 "Relative Blade Height fully functional" ;
VAL_ 2550333182 VDCActive 1 "VDCActive" 0 "VDCPassive" ;
VAL_ 2550333182 VehicleType 1 "Trailer" 0 "TowingOrTowedVehicle" ;
VAL_ 2550333182 BrakeLightSwitch 1 "Switch on" 0 "Switch off" ;
VAL_ 2550333182 ASREngineControlStatus 3 "NotAvailable" 2 "Reserved" 1 "ASREngineControlActive" 0 "ASREngnCntrlPassiveButInstalled" ;
VAL_ 2550333182 ASRBreakControlStatus 1 "Active" 0 "Passive, but installed" ;
VAL_ 2550333182 VehicleRetarderCtrlStatus 1 "Active" 0 "Passive" ;
VAL_ 2550333182 VehicleABSStatus 1 "Active" 0 "Passiv, but installed" ;
VAL_ 2566834686 EmergencyBrakingStatus 1 "EmergencyBrakingActive" 0 "NoEmergencyBrakingActive" ;
VAL_ 2566834686 LoadPropFctInstallationStatus 1 "VehicleWithLoadPropFunction" 0 "VehicleWithoutLoadPropFunction" ;
VAL_ 2566834686 ReverseGearStatus 1 "ReverseGearEngaged" 0 "ReverseGearNotEngaged" ;
VAL_ 2566834686 TrailerYCSystemRequest 1 "EnableTrailerYCSystem" 0 "DisableTrailerYCSystem" ;
VAL_ 2566834686 TrailerROPSystemRequest 1 "EnableTrailerROPSystem" 0 "DisableTrailerROPSystem" ;
VAL_ 2566834686 YCSystemStatus 1 "YCSystemEnabled" 0 "YCSystemDisabled" ;
VAL_ 2566834686 ROPSystemStatus 1 "ROPSystemEnabled" 0 "ROPSystemDisabled" ;
VAL_ 2566834686 PneumaticControlLineStatus 1 "Towing veh with pn ctrl line" 0 "Towing veh without pn ctrl line" ;
VAL_ 2566834686 ABSOffroadRequest 1 "ABS off-road switch on" 0 "ABS off-road switch off" ;
VAL_ 2566834686 TwoElCircuitsBrakeDemandStatus 1 "Two el. circuit brake available" 0 "One el. circuit brake available" ;
VAL_ 2566834686 VehicleRetarderCtrlStatus 1 "Active" 0 "Passive" ;
VAL_ 2550398718 SupSideOrAxleBrakeForceDistr 1 "SideOrAxleBrakeForceDstrEnabled" 0 "SideOrAxleBrakeForceDstrDisabled" ;
VAL_ 2550398718 VDCActive 1 "Active" 0 "Passive, but installed" ;
VAL_ 2550398718 AutomTowedVehicleBreakStatus 1 "Active" 0 "Passive" ;
VAL_ 2550398718 VehicleServiceBrakeStatus 1 "Active" 0 "Passive" ;
VAL_ 2550398718 VehicleRetarderCtrlStatus 1 "Active" 0 "Passive" ;
VAL_ 2550398718 VehicleABSStatus 1 "Active" 0 "Passiv, but installed" ;
VAL_ 2566833406 BrakingViaElectrCtrlLineSupport 1 "BrakingViaElCtrlLineSupported" 0 "BrakingViaElCtrlLineNotSupported" ;
VAL_ 2566833406 StopLampsRequest 1 "StopLampsIlluminRequested" 0 "StopLampsIlluminNotRequested" ;
VAL_ 2566833406 SupplyLineBraking 1 "Supply line braking request" 0 "No supply line braking request" ;
VAL_ 2566833406 LoadingRampApprAssistStatus 1 "Assistance active" 0 "Assistance not active" ;
VAL_ 2566833406 SpringBrakeStatus 1 "Vehicle spring brake is engaged" 0 "Vehicle spring brake is released" ;
VAL_ 2566833406 ElectrLoadPropFuncInstalStatus 1 "Vehicle with el. load proportion" 0 "Vehicle without el. load proport" ;
VAL_ 2566833406 SpringBrakeInstallationStatus 1 "Vehicle with spring brakes" 0 "Vehicle without spring brakes" ;
VAL_ 2566833406 VehicleType 1 "Trailer" 0 "TowingOrTowedVehicle" ;
VAL_ 2566833406 ElectSupplyOfNonBrakingSysStatus 1 "Supply switched on" 0 "Supply switched off" ;
VAL_ 2566833406 AmberWarningSignalReq 1 "Towed vehicle failure indicated" 0 "No towed vehicle failure indicat" ;
VAL_ 2566833406 RedWarningSignalRequest 1 "Towed vehicle failure indicated" 0 "No towed vehicle failure indicat" ;
VAL_ 2566833406 VehicleElectrSupplyStatus 1 "Vehicle el. supply sufficient" 0 "Vehicle el. supply insufficient" ;
VAL_ 2566833406 AutomTowedVehicleBreakStatus 1 "Active" 0 "Passive" ;
VAL_ 2566833406 VehicleServiceBrakeStatus 1 "Active" 0 "Passive" ;
VAL_ 2566833406 VehicleRetarderCtrlStatus 1 "Active" 0 "Passive" ;
VAL_ 2566833406 VehicleABSStatus 1 "Active" 0 "Passiv, but installed" ;
VAL_ 2566833918 TyreWheelIDBrakeTemp2 15 "Axle position 15" 14 "Axle position 14" 13 "Axle position 13" 12 "Axle position 12" 11 "Axle position 11" 10 "Axle position 10" 9 "Axle position 9" 8 "Axle position 8" 7 "Axle position 7" 6 "Axle position 6" 5 "Axle position 5" 4 "Axle position 4" 3 "Axle position 3" 2 "Axle position 2" 1 "Axle position 1" 0 "Axle position not identified" ;
VAL_ 2566833918 TyreWheelIDBrakeTemp1 15 "Wheel position 15" 14 "Wheel position 14" 13 "Wheel position 13" 12 "Wheel position 12" 11 "Wheel position 11" 10 "Wheel position 10" 9 "Wheel position 9" 8 "Wheel position 8" 7 "Wheel position 7" 6 "Wheel position 6" 5 "Wheel position 5" 4 "Wheel position 4" 3 "Wheel position 3" 2 "Wheel position 2" 1 "Wheel position 1" 0 "Wheel position not identified" ;
VAL_ 2566833918 TyreWheelIDTyrePressure2 15 "Axle position 15" 14 "Axle position 14" 13 "Axle position 13" 12 "Axle position 12" 11 "Axle position 11" 10 "Axle position 10" 9 "Axle position 9" 8 "Axle position 8" 7 "Axle position 7" 6 "Axle position 6" 5 "Axle position 5" 4 "Axle position 4" 3 "Axle position 3" 2 "Axle position 2" 1 "Axle position 1" 0 "Axle position not identified" ;
VAL_ 2566833918 TyreWheelIDTyrePressure1 15 "Wheel position 15" 14 "Wheel position 14" 13 "Wheel position 13" 12 "Wheel position 12" 11 "Wheel position 11" 10 "Wheel position 10" 9 "Wheel position 9" 8 "Wheel position 8" 7 "Wheel position 7" 6 "Wheel position 6" 5 "Wheel position 5" 4 "Wheel position 4" 3 "Wheel position 3" 2 "Wheel position 2" 1 "Wheel position 1" 0 "Wheel position not identified" ;
VAL_ 2566833918 TyreWheelIDBrakeLining2 15 "Axle position 15" 14 "Axle position 14" 13 "Axle position 13" 12 "Axle position 12" 11 "Axle position 11" 10 "Axle position 10" 9 "Axle position 9" 8 "Axle position 8" 7 "Axle position 7" 6 "Axle position 6" 5 "Axle position 5" 4 "Axle position 4" 3 "Axle position 3" 2 "Axle position 2" 1 "Axle position 1" 0 "Axle position not identified" ;
VAL_ 2566833918 TyreWheelIDBrakeLining1 15 "Wheel position 15" 14 "Wheel position 14" 13 "Wheel position 13" 12 "Wheel position 12" 11 "Wheel position 11" 10 "Wheel position 10" 9 "Wheel position 9" 8 "Wheel position 8" 7 "Wheel position 7" 6 "Wheel position 6" 5 "Wheel position 5" 4 "Wheel position 4" 3 "Wheel position 3" 2 "Wheel position 2" 1 "Wheel position 1" 0 "Wheel position not identified" ;
VAL_ 2566833918 VehiclePneumSupplyStatus 1 "Pneumatic supply sufficient" 0 "Pneumatic supply insufficient" ;
VAL_ 2566833918 BrakeTemperatureStatus 1 "Brake temperature normal" 0 "Brake temperature out of range" ;
VAL_ 2566833918 BrakeLiningStatus 1 "Brake linings sufficient" 0 "Brake linings insufficient" ;
VAL_ 2566833918 TyrePressureStatus 1 "Tyre pressure sufficient" 0 "Tyre pressure insufficient" ;
VAL_ 2565013246 ODDVersionRequest 1 "ISO11992_3_Ed3_Compatible" 0 "NoODAvailable" ;
VAL_ 2565013246 DetailedVehicleType 20 "PlatformTruck" 16 "TractorForSemiTrailer" 12 "LinkTrailerTowingAnotherTrailer " 11 "ConverterDollyTowingAnother" 10 "FullTrailerTowingAnotherTrailer" 9 "CentralAxleTrailerTowingAnother" 8 "SemiTrailerTowingAnotherTrailer" 4 "LinkTrailer" 3 "ConverterDolly" 2 "FullTrailer" 1 "CentralAxleTrailer " 0 "SemiTrailer" ;
VAL_ 2565013246 ODDRequest 3 "TakeNoAction" 1 "ODD_On" 0 "ODD_Off" ;
VAL_ 2565013246 AntiTheftDeviceReq 3 "TakeNoAction" 1 "AntiTheftDeviceOn" 0 "AntiTheftDeviceOff" ;
VAL_ 2565013246 VehicleType 1 "Trailer" 0 "TowingOrTowedVehicle" ;
VAL_ 2566807550 EngineRunning 1 "EngineRunning" 0 "EngineNotRunning" ;
VAL_ 2566807550 EngineControlAllowed 1 "EngineControlAllowed" 0 "EngineControlNotAllowed" ;
VAL_ 2566808062 ClutchIndptdPTOFeedback 1 "Engaged" 0 "Not engaged" ;
VAL_ 2566808062 AccelPedalLowIdleSwitch 1 "In low idle condition" 0 "Not in low idle condition" ;
VAL_ 2566808062 StarterActive 1 "Starter active" 0 "Starter not active" ;
VAL_ 2566808062 TorqueConvtOilTempWarning 2 "Warning" 1 "Prewarning" 0 "No warning" ;
VAL_ 2566808062 PTOControlAllowed 1 "PTO control allowed" 0 "PTO control not allowed" ;
VAL_ 2566808062 SecEngineMtdPTOFeedback 1 "Limits activated" 0 "Limits not activated" ;
VAL_ 2566808062 FirstEngineMtdPTOFeedback 1 "Limits activated" 0 "Limits not activated" ;
VAL_ 2566808062 SecClutchDptdPTOFeedback 1 "Engaged" 0 "Not engaged" ;
VAL_ 2566808062 FirstClutchDpdtPTOFeedback 1 "Engaged" 0 "Not engaged" ;
VAL_ 2566808574 FuelLevelWarning 1 "Fuel level warning on" 0 "Fuel level warning off" ;
VAL_ 2566808574 EngineOilPressureWarning 1 "Warning" 0 "No warning" ;
VAL_ 2566808574 EngineCoolantTempWarning 2 "Warning" 1 "Prewarning" 0 "No warning" ;
VAL_ 2564947710 ODDVersionInformation 1 "ISO11992_3_Ed3_Compatible" 0 "NoODAvailable" ;
VAL_ 2564947710 DetailedVehicleType 20 "PlatformTruck" 16 "TractorForSemiTrailer" 12 "LinkTrailerTowingAnotherTrailer " 11 "ConverterDollyTowingAnother" 10 "FullTrailerTowingAnotherTrailer" 9 "CentralAxleTrailerTowingAnother" 8 "SemiTrailerTowingAnotherTrailer" 4 "LinkTrailer" 3 "ConverterDolly" 2 "FullTrailer" 1 "CentralAxleTrailer " 0 "SemiTrailer" ;
VAL_ 2564947710 VehicleType 1 "Trailer" 0 "TowingOrTowedVehicle" ;
VAL_ 2566834430 AntiTheftDeviceStatus 1 "Anti-theft device on" 0 "Anti-theft device off" ;
VAL_ 2566834430 ODDStatus 1 "ODD active" 0 "ODD inactive" ;
VAL_ 2566808318 TransfCaseOutShaftPTOEngmtConsTr 1 "ConsentGiven_PTOEngaged" 0 "ConsentNotGiven_PTONotEngaged" ;
VAL_ 2566808318 FirstTransOutShaftPTOEngmtConsTr 1 "ConsentGiven_PTOEngaged" 0 "ConsentNotGiven_PTONotEngaged" ;
VAL_ 2566808318 SecEngineMntPTOEngagemtConsTr 1 "ConsentGiven_PTOEngaged" 0 "ConsentNotGiven_PTONotEngaged" ;
VAL_ 2566808318 FirstEngineMntPTOEngagemtConsTr 1 "ConsentGiven_PTOEngaged" 0 "ConsentNotGiven_PTONotEngaged" ;
VAL_ 2566808318 ClutchIndpdtPTOEngagemtConsTr 1 "ConsentGiven_PTOEngaged" 0 "ConsentNotGiven_PTONotEngaged" ;
VAL_ 2566808318 SecClutchDpdtPTOEngagemtConsTr 1 "ConsentGiven_PTOEngaged" 0 "ConsentNotGiven_PTONotEngaged" ;
VAL_ 2566808318 FirstClutchDpdtPTOEngagemtConsTr 1 "ConsentGiven_PTOEngaged" 0 "ConsentNotGiven_PTONotEngaged" ;
VAL_ 2566808318 TransferCaseOutputShaftPTOSwitch 1 "SwitchedOn" 0 "SwitchedOff" ;
VAL_ 2566808318 TransmissionOutputShaftPTOSwitch 1 "SwitchedOn" 0 "SwitchedOff" ;
VAL_ 2566808318 SecEngineMtdPTOSwitch 1 "Switched on" 0 "Switched off" ;
VAL_ 2566808318 SecClutchDpdtPTOSwitch 1 "Switched on" 0 "Switched off" ;
VAL_ 2566808318 FirstClutchDpdtPTOSwitch 1 "Switched on" 0 "Switched off" ;
VAL_ 2566808318 OperatingPanelActive 1 "Operating panel active" 0 "Operating panel not active" ;
VAL_ 2566808318 RefusePackerStepSwitch 1 "Switched on" 0 "Switched off" ;
VAL_ 2566808318 EngineStopSwitch 1 "Switched on" 0 "Switched off" ;
VAL_ 2566808318 EngineStartSwitch 1 "Switched on" 0 "Switched off" ;
VAL_ 2566808318 StarterLockoutSwitch 1 "Switched on" 0 "Switched off" ;
VAL_ 2566808318 FirstEngineMtdPTOSwitch 1 "Switched on" 0 "Switched off" ;
VAL_ 2566808318 ClutchIndpdtPTOSwitch 1 "Switched on" 0 "Switched off" ;
VAL_ 2566808830 TrailerRightReversLightRedundFct 1 "RedundancyFunctionActivated" 0 "RedundancyFunctionNotActivated" ;
VAL_ 2566808830 TrailerLeftReversLightRedundFct 1 "RedundancyFunctionActivated" 0 "RedundancyFunctionNotActivated" ;
VAL_ 2566808830 TrailerRightRearLightRedundFct 1 "RedundancyFunctionActivated" 0 "RedundancyFunctionNotActivated" ;
VAL_ 2566808830 TrailerLeftRearLightRedundFct 1 "RedundancyFunctionActivated" 0 "RedundancyFunctionNotActivated" ;
VAL_ 2566808830 TrailerRightDirIndLightRedundFct 1 "RedundancyFunctionActivated" 0 "RedundancyFunctionNotActivated" ;
VAL_ 2566808830 TrailerLeftDirIndLightRedundFct 1 "RedundancyFunctionActivated" 0 "RedundancyFunctionNotActivated" ;
VAL_ 2566808830 TrailerRightStopLightRedundFct 1 "RedundancyFunctionActivated" 0 "RedundancyFunctionNotActivated" ;
VAL_ 2566808830 TrailerLeftStopLightRedundFct 1 "RedundancyFunctionActivated" 0 "RedundancyFunctionNotActivated" ;
VAL_ 2566808830 TowedVehicleLeftSideMarkerLight 1 "Lamp(s) lit" 0 "Lamp(s) not lit" ;
VAL_ 2566808830 TowedVehicleLeftReversingLight 1 "Lamp(s) lit" 0 "Lamp(s) not lit" ;
VAL_ 2566808830 TowedVehicleLeftRearWidIndLight 1 "Lamp(s) lit" 0 "Lamp(s) not lit" ;
VAL_ 2566808830 TowedVehicleLeftRearRegPltLight 1 "Lamp(s) lit" 0 "Lamp(s) not lit" ;
VAL_ 2566808830 TowedVehicleLeftRearLight 1 "Lamp(s) lit" 0 "Lamp(s) not lit" ;
VAL_ 2566808830 TowedVehicleLeftRearFogLight 1 "Lamp(s) lit" 0 "Lamp(s) not lit" ;
VAL_ 2566808830 TowedVehicleLeftDirIndLight 1 "Lamp(s) lit" 0 "Lamp(s) not lit" ;
VAL_ 2566808830 TowedVehicleLeftCrnMarkerLight 1 "Lamp(s) lit" 0 "Lamp(s) not lit" ;
VAL_ 2566808830 TowedVehicleInteriorLight 1 "Lamp(s) lit" 0 "Lamp(s) not lit" ;
VAL_ 2566808830 TowedVehicleWorkLight 1 "Lamp(s) lit" 0 "Lamp(s) not lit" ;
VAL_ 2566808830 TowedVehicleRotatingIdentLight 1 "Lamp(s) lit" 0 "Lamp(s) not lit" ;
VAL_ 2566808830 TowedVehicleRightStopLight 1 "Lamp(s) lit" 0 "Lamp(s) not lit" ;
VAL_ 2566808830 TowedVehicleRightSideMrkLight 1 "Lamp(s) lit" 0 "Lamp(s) not lit" ;
VAL_ 2566808830 TowedVehicleRightReversingLight 1 "Lamp(s) lit" 0 "Lamp(s) not lit" ;
VAL_ 2566808830 TowedVehicleRearWidIndLight 1 "Lamp(s) lit" 0 "Lamp(s) not lit" ;
VAL_ 2566808830 TowedVehicleRightRearRegPltLight 1 "Lamp(s) lit" 0 "Lamp(s) not lit" ;
VAL_ 2566808830 TowedVehicleRightRearLight 1 "Lamp(s) lit" 0 "Lamp(s) not lit" ;
VAL_ 2566808830 TowedVehicleRightRearFogLight 1 "Lamp(s) lit" 0 "Lamp(s) not lit" ;
VAL_ 2566808830 TowedVehicleRightDirIndLight 1 "Lamp(s) lit" 0 "Lamp(s) not lit" ;
VAL_ 2566808830 TowedVehicleRightCrnMarkerLight 1 "Lamp(s) lit" 0 "Lamp(s) not lit" ;
VAL_ 2566808830 TowedVehicleRearWarningLight 1 "Lamp(s) lit" 0 "Lamp(s) not lit" ;
VAL_ 2566808830 TowedVehicleLeftStopLight 1 "Lamp(s) lit" 0 "Lamp(s) not lit" ;
VAL_ 2564554494 FlowStatus 2 "Overflow" 1 "Wait " 0 "Continue To Send" ;
VAL_ 2564554494 ProtocolCtrlInformation 3 "Flow control " 2 "Consecutive frame" 1 "First frame" 0 "Single frame" ;
VAL_ 2564488958 FlowStatus 2 "Overflow" 1 "Wait " 0 "Continue To Send" ;
VAL_ 2564488958 ProtocolCtrlInformation 3 "Flow control " 2 "Consecutive frame" 1 "First frame" 0 "Single frame" ;
VAL_ 2565734142 ToPort 21 "Global (All ports)" 0 "Local" ;
VAL_ 2565734142 NetworkMessageControlByte 133 "SP_Reset Message " 132 "SP_Response Message " 131 "SP_Request Message " 130 "GP_Reset Message " 129 "GP_Response " 128 "GP_Request " 67 "NTX_Response " 66 "NTX_Request " 65 "NT_Response" 64 "NT_Request " 6 "MFDB_CreateEntry" 5 "MFDB_SetMode" 4 "MFDB_Clear" 3 "MFDB_Delete" 2 "MFDB_Add" 1 "MFDB_Response" 0 "MFDB_Request" ;
VAL_ 2565734142 FilterMode 1 "PassSpecificPGNs" 0 "BlockSpecificPGNs" ;
VAL_ 2565734142 NIECUPort 21 "Global (All ports)" 0 "Local" ;
VAL_ 2565734142 FromPort 21 "Global (All ports)" 0 "Local" ;
VAL_ 2565144318 RideHeightAndRampLevelSetRequest 2 "UseDefaultSet" 1 "UseExtendedSet2" 0 "UseExtendedSet1" ;
VAL_ 2565144318 LiftAxle5PositionReq 3 "Don't care/take no action" 2 "Reserved" 1 "Position up / tag axle unladen" 0 "Position down / tag axle laden" ;
VAL_ 2565144318 LiftAxle4PositionReq 3 "Take no action" 1 "Position up / tag axle unladen" 0 "Position down / tag axle laden" ;
VAL_ 2565144318 LiftAxle3PositionReq 3 "Take no action" 1 "Position up / tag axle unladen" 0 "Position down / tag axle laden" ;
VAL_ 2565144318 RideHeightStorageRequest 2 "TakeNoAction" 1 "StoreRideHeight2" 0 "StoreRideHeight1" ;
VAL_ 2565144318 StopLevelChangeReq 3 "Take no action" 1 "Stop request" 0 "No stop request" ;
VAL_ 2565144318 RampLevelStorageReq 3 "Take no action" 1 "Store ramp level 2" 0 "Store ramp level 1" ;
VAL_ 2565144318 LevelControlReq 3 "Take no action" 1 "Enable level control" 0 "Disable level control" ;
VAL_ 2565144318 RampLevelReq 3 "Take no action" 1 "Ramp level 2" 0 "Ramp level 1" ;
VAL_ 2565144318 SteeringAxleLockingReq 3 "Take no action" 1 "Lock steering axle" 0 "Unlock steering axle" ;
VAL_ 2565144318 LiftAxle2PositionReq 3 "Take no action" 1 "Position up / tag axle unladen" 0 "Position down / tag axle laden" ;
VAL_ 2565144318 LiftAxle1PositionReq 3 "Don't care/take no action" 2 "Reserved" 1 "Position up / tag axle unladen" 0 "Position down / tag axle laden" ;
VAL_ 2565144318 TractionHelpReq 3 "Take no action" 1 "Traction help request" 0 "No traction help request" ;
VAL_ 2565144318 LevelChangeReqRearAxle 2 "Take no action" 1 "Vehicle body down (lowering)" 0 "Vehicle body up (lifting)" ;
VAL_ 2565144318 LevelChangeReqFrontAxle 2 "Take no action" 1 "Vehicle body down (lowering)" 0 "Vehicle body up (lifting)" ;
VAL_ 2565144318 RideHeightRequest 2 "Take no action" 1 "Normal level 2" 0 "Normal level 1" ;
VAL_ 2565209854 ExtRideHeightAndRampLevelStorage 2 "ExtStorageNotSupported" 1 "ExtStorageSupportedTwoSets" 0 "ExtStorageSupportedThreeSets" ;
VAL_ 2565209854 RideHeightStorage 2 "RideHeightCannotBeStored" 1 "NewRideHeightStored" 0 "NoStorageRequest " ;
VAL_ 2565209854 LevelControl 1 "Level control enabled" 0 "Level control disabled" ;
VAL_ 2565209854 RampLevel 1 "Body at requested ramp level" 0 "Body not at requested ramp level" ;
VAL_ 2565209854 NormalLevel 3 "Not available" 1 "Normal level 2" 0 "Normal level 1" ;
VAL_ 2565209854 StopLevelChangeAcknowledge 1 "Level change stopped" 0 "No stop request" ;
VAL_ 2565209854 LevelChangeRearAxle 1 "Body lifting/lowering active" 0 "Body lifting/lowering not active" ;
VAL_ 2565209854 LevelChangeFrontAxle 1 "Body lifting/lowering active" 0 "Body lifting/lowering not active" ;
VAL_ 2565209854 RampLevelStorage 1 "New ramp level stored" 0 "No new storage request" ;
VAL_ 2565209854 SteeringAxleLockingStatus 1 "Steering axle locked" 0 "Steering axle unlocked" ;
VAL_ 2565209854 LiftAxle2Pos 3 "Not available" 2 "Error" 1 "Lift axle position up / tag axle unladen" 0 "Lift axle position down / tag axle laden" ;
VAL_ 2565209854 LiftAxle1Pos 3 "Not available" 2 "Error" 1 "Lift axle position up / tag axle unladen" 0 "Lift axle position down / tag axle laden" ;
VAL_ 2565209854 RampLevelPosition 3 "Not available" 1 "Ramp level 2" 0 "Ramp level 1" ;
VAL_ 2565209854 TractionHelpStatus 1 "Traction help active" 0 "Traction help inactive" ;
VAL_ 2565209854 RideHeightLevel 1 "Vehicle body at requested level" 0 "Vehicle body not at req. level" ;
VAL_ 2566806782 TyreWheelID2_AxleLoad 15 "AxlePosition15" 14 "AxlePosition14" 13 "AxlePosition13" 12 "AxlePosition12" 11 "AxlePosition11" 10 "AxlePosition10" 9 "AxlePosition9" 8 "AxlePosition8" 7 "AxlePosition7" 6 "AxlePosition6" 5 "AxlePosition5" 4 "AxlePosition4" 3 "AxlePosition3" 2 "AxlePosition2" 1 "AxlePosition1" 0 "AxlePositionNotIdentified" ;
VAL_ 2566806782 TyreWheelID1_AxleLoad 15 "WheelPosition15" 14 "WheelPosition14" 13 "WheelPosition13" 12 "WheelPosition12" 11 "WheelPosition11" 10 "WheelPosition10" 9 "WheelPosition9" 8 "WheelPosition8" 7 "WheelPosition7" 6 "WheelPosition6" 5 "WheelPosition5" 4 "WheelPosition4" 3 "WheelPosition3" 2 "WheelPosition2" 1 "WheelPosition1" 0 "WheelPositionNotIdentified" ;
VAL_ 2566807294 IdentificationDataIndex 16 "VIN16" 15 "VIN15" 14 "VIN14" 13 "VIN13" 12 "VIN12" 11 "VIN11" 10 "VIN10" 9 "VIN9" 8 "VIN8" 7 "VIN7" 6 "VIN6" 5 "VIN5" 4 "VIN4" 3 "VIN3" 2 "VIN2" 1 "VIN1" 0 "VIN0" ;
VAL_ 2566807294 TyrePressThresholdDetect 7 "Not available" 6 "Error indicator" 5 "Not defined" 4 "Extreme under pressure" 3 "Under pressure" 2 "No warning pressure" 1 "Over pressure" 0 "Extreme over pressure" ;
VAL_ 2566807294 TyreModulePowerSupplyStatus 1 "Sufficient power supply" 0 "Insufficient power supply" ;
VAL_ 2566807294 TyreWheelID2 15 "AxlePosition15" 14 "AxlePosition14" 13 "AxlePosition13" 12 "AxlePosition12" 11 "AxlePosition11" 10 "AxlePosition10" 9 "AxlePosition9" 8 "AxlePosition8" 7 "AxlePosition7" 6 "AxlePosition6" 5 "AxlePosition5" 4 "AxlePosition4" 3 "AxlePosition3" 2 "AxlePosition2" 1 "AxlePosition1" 0 "AxlePositionNotIdentified" ;
VAL_ 2566807294 TyreWheelID1 15 "WheelPosition15" 14 "WheelPosition14" 13 "WheelPosition13" 12 "WheelPosition12" 11 "WheelPosition11" 10 "WheelPosition10" 9 "WheelPosition9" 8 "WheelPosition8" 7 "WheelPosition7" 6 "WheelPosition6" 5 "WheelPosition5" 4 "WheelPosition4" 3 "WheelPosition3" 2 "WheelPosition2" 1 "WheelPosition1" 0 "WheelPositionNotIdentified" ;
VAL_ 2566764798 MisfireMonitoringComplete 1 "EnabledForCycle" 0 "DisabledForRestOfCycle" ;
VAL_ 2566764798 MisfireMonitoringEnabled 1 "EnabledForCycle" 0 "DisabledForRestOfCycle" ;
VAL_ 2566764798 FuelSystemMonitoringEnabled 1 "NotCompleteCycle" 0 "CompleteCycleOrNotSupported" ;
VAL_ 2566764798 ComprehensiveComptMonComplete 1 "NotCompleteCycle" 0 "CompleteCycleOrNotSupported" ;
VAL_ 2566764798 ComprehensiveCompMonEnabled 1 "NotCompleteCycle" 0 "CompleteCycleOrNotSupported" ;
VAL_ 2566764798 SecondAirSystemMonComplete 1 "EnabledForCycle" 0 "DisabledForRestOfCycle" ;
VAL_ 2566764798 SecondAirSystemMonEnabled 1 "EnabledForCycle" 0 "DisabledForRestOfCycle" ;
VAL_ 2566764798 OxygenSensorMonComplete 1 "EnabledForCycle" 0 "DisabledForRestOfCycle" ;
VAL_ 2566764798 OxygenSensorMonEnabled 1 "NotCompleteCycle" 0 "CompleteCycleOrNotSupported" ;
VAL_ 2566764798 OxygenSensorHeaterMonComplete 1 "EnabledForCycle" 0 "DisabledForRestOfCycle" ;
VAL_ 2566764798 OxygenSensorHeaterMonEnabled 1 "NotCompleteCycle" 0 "CompleteCycleOrNotSupported" ;
VAL_ 2566764798 HeatedCatalystMonComplete 1 "EnabledForCycle" 0 "DisabledForRestOfCycle" ;
VAL_ 2566764798 HeatedCatalystMonEnabled 1 "EnabledForCycle" 0 "DisabledForRestOfCycle" ;
VAL_ 2566764798 EvaporativeSystemMonComplete 1 "NotCompleteCycle" 0 "CompleteCycleOrNotSupported" ;
VAL_ 2566764798 EvaporativeSystemMonEnabled 1 "NotCompleteCycle" 0 "CompleteCycleOrNotSupported" ;
VAL_ 2566764798 EGRSystemMonitoringComplete 1 "NotCompleteCycle" 0 "CompleteCycleOrNotSupported" ;
VAL_ 2566764798 EGRSystemMonitoringEnabled 1 "EnabledForCycle" 0 "DisabledForRestOfCycle" ;
VAL_ 2566764798 ColdStartAidSystemMonComplete 1 "EnabledForCycle" 0 "DisabledForRestOfCycle" ;
VAL_ 2566764798 ColdStartAidSystemMonEnabled 1 "EnabledForCycle" 0 "DisabledForRestOfCycle" ;
VAL_ 2566764798 CatalystMonComplete 1 "NotCompleteCycle" 0 "CompleteCycleOrNotSupported" ;
VAL_ 2566764798 CatalystMonEnabled 1 "NotCompleteCycle" 0 "CompleteCycleOrNotSupported" ;
VAL_ 2566764798 ACSystemRefrigerantMonComplete 1 "NotCompleteCycle" 0 "CompleteCycleOrNotSupported" ;
VAL_ 2566764798 ACSystemRefrigerantMonEnabled 1 "NotCompleteCycle" 0 "CompleteCycleOrNotSupported" ;
VAL_ 2566764798 FuelSystemMonitoringComplete 1 "NotCompleteCycle" 0 "CompleteCycleOrNotSupported" ;
VAL_ 2564095742 SecurityEntityType 3 "Data is Certificate" 2 "Data is Session Key" 1 "Data is Long Key" 0 "Data is Long Seed" ;
VAL_ 2349137662 XBRBrkHoldReq 3 "Not available" 2 "Reserved" 1 "Brake Hold requested" 0 "Brake Hold not requested" ;
VAL_ 2349137662 XBRCompensationMode 3 "Take No Action" 2 "Reserved" 1 "Compensations Enabled" 0 "Compensations Disabled" ;
VAL_ 2349137662 XBRCtrlMode 3 "Not defined" 2 "Acceleration control with maximum mode" 1 "Acceleration control with addition mode" 0 "Override disabled" ;
VAL_ 2349137662 XBRPriority 3 "Low priority" 2 "Medium priority" 1 "High priority" 0 "Highest priority" ;
VAL_ 2349137662 XBREBIMode 3 "Not defined" 2 "Endurance Brake Integration allowed" 1 "Only Endurance Brakes allowed" 0 "No Endurance Brake Integration allowed" ;
VAL_ 2566848510 EngSvcInd 7 "Not Available" 6 "Reserved" 5 "Reserved" 4 "Reserved" 3 "Reserved" 2 "Service engine now" 1 "Service engine soon" 0 "No service needed" ;
VAL_ 2566848510 EmissionCtrlSysOpSpdIndSev 7 "Not Available / Not Supported" 6 "Temporary Override of Inducement" 5 "Inducement Level 5 … Off Highway" 4 "Inducement Level 4 … Off Highway" 3 "Inducement Level 3 … Off Highway" 2 "Inducement Level 2 … Off Highway" 1 "Inducement Level 1 … Off Highway" 0 "DEF Warning" ;
VAL_ 2566848510 EmissionCtrlSysOpTrqIndSev 7 "Not Available / Not Supported" 6 "Temporary Override of Inducement" 5 "Inducement Level 5 … Off Highway" 4 "Inducement Level 4 … Off Highway" 3 "Inducement Level 3 … Off Highway" 2 "Inducement Level 2 … Off Highway" 1 "Inducement Level 1 … Off Highway" 0 "DEF Warning" ;
VAL_ 2566848510 StartReqInhInd 3 "Take no action" 2 "Active, flashing)" 1 "Active, on continuously)" 0 "Inactive" ;
VAL_ 2566848510 AutoStartReqInhInd 3 "Take no action" 2 "Active, flashing)" 1 "Active, on continuously)" 0 "Inactive" ;
VAL_ 2566848510 WaterInChargeADAfterChargeACInd 3 "Not available" 2 "Error" 1 "Yes" 0 "No" ;
VAL_ 2566848510 EngOverloadedInd 0 "No" 3 "Not available" 2 "Error" 1 "Yes" ;
VAL_ 2566848510 EmssnCtrlSystmOprtrIndcmntSvrity 7 "Not Available / Not Supported" 6 "Temporary Override of Inducement" 5 "Inducement Level 5 .." 4 "Inducement Level 4 .." 3 "Inducement Level 3 .." 2 "Inducement Level 2 .." 1 "Inducement Level 1.." 0 "Driver Warning" ;
VAL_ 2566848510 DrvrWarningSystemIndicatorStatus 7 "not available" 6 "reserved for SAE assignment" 5 "reserved for SAE assignment" 4 "On, fast blink" 3 "reserved for SAE assignment" 2 "reserved for SAE assignment" 1 "On, solid" 0 "Off" ;
VAL_ 2566848510 OperatorShiftPrompt 3 "don't care/take no action" 2 "downshift indicator active" 1 "upshift indicator active" 0 "indicator(s) inactive" ;
VAL_ 2566848510 WaterInFuelIndicator 3 "Not available" 2 "Error" 1 "Yes" 0 "No" ;
VAL_ 2566848510 WaterInFuelIndicator2 3 "Not available" 2 "Error" 1 "Yes" 0 "No" ;
VAL_ 2566843134 AxleLocation 48 "Axle3_Position0" 32 "Axle2_Position0" 16 "Axle1_Position0" 0 "Axle0_Position0" ;
VAL_ 2566804222 ECUKeySwSt 3 "Not Available" 2 "Error" 1 "On" 0 "Off" ;
VAL_ 2566809854 WinchOilPressSwitch 3 "Not Available" 2 "Error" 1 "OK" 0 "NOT OK- Oil pressure is too low" ;
VAL_ 2566809854 HydOilFilterRestrictionSwitch 3 "Not Available" 2 "Error" 1 "Restriction exists on oil filter" 0 "No restriction" ;
VAL_ 2565868030 SteerWheelAngleSensorType 3 "Not Available" 2 "Reserved" 1 "Absolute measuring principle" 0 "Relative measuring principle" ;
VAL_ 2566803454 TrailerVDCActive 3 "Not availble or not installed" 2 "Reserved" 1 "VDC active" 0 "VDC passive" ;
VAL_ 2566803454 YCBrakeCtrlActive 3 "Don't care/Take no action" 2 "Reserved" 1 "YC brake control active" 0 "YC brake control passive but installed" ;
VAL_ 2566803454 YCEngCtrlActive 3 "Don't care/Take no action" 2 "Reserved" 1 "YC engine control active" 0 "YC engine control passive but installed" ;
VAL_ 2566803454 ROPBrakeCtrlActive 3 "Don't care/Take no action" 2 "Reserved" 1 "ROP brake control active" 0 "ROP brake control passive but installed" ;
VAL_ 2566803454 ROPEngCtrlActive 3 "Don't care/Take no action" 2 "Reserved" 1 "ROP engine control active" 0 "ROP engine control passive but installed" ;
VAL_ 2566803454 VDCBrakeLightRq 3 "Don't care/Take no action" 2 "Reserved" 1 "Turn brake light on" 0 "Turn brake light not on" ;
VAL_ 2566803454 VDCFullyOperational 3 "Don't care/Take no action" 2 "Reserved" 1 "Fully operational" 0 "Not fully operational" ;
VAL_ 2566803454 VDCInformationSignal 3 "Don't care/Take no action" 2 "Reserved" 1 "On" 0 "Off" ;
VAL_ 2348875518 EngRequestedTorqueHighResolution 7 "+0.875%" 1 "+0.125%" 0 "+0.000%" ;
VAL_ 2348875518 TSC1CtrlPurpose 6 "P7 = Automated Driving System Input" 31 "P32 = Temporary Powertrain Control" 5 "P6 = Transient-Optimized Torque Limit" 4 "P5 = Engine Protection" 3 "P4 = Road Speed Governor" 2 "P3 = PTO Governor" 1 "P2 = Cruise Control" 0 "P1 = Accelerator Pedal/Operator Selection" ;
VAL_ 2348875518 TSC1TransRate 4 "100 ms transmission rate" 3 "250 ms transmission rate" 2 "500 ms transmission rate" 1 "750 ms transmission rate" 0 "1000 ms transmission rate" 7 "Use standard TSC1 transmission rates of 10 ms to engine" 6 "20 ms transmission rate" 5 "50 ms transmission rate" ;
VAL_ 2348875518 OverrideCtrlModePriority 3 "Low priority" 2 "Medium priority" 1 "High priority" 0 "Highest priority" ;
VAL_ 2348875518 EngRequestedSpeedCtrlConditions 3 "Stability Optimized for driveline engaged and/or in lockup condition 2" 2 "Stability Optimized for driveline engaged and/or in lockup condition 1" 1 "Stability Optimized for driveline disengaged and non-lockup conditions" 0 "Transient Optimized for driveline disengaged and non-lockup conditions" ;
VAL_ 2348875518 EngOverrideCtrlMode 3 "Speed/torque limit control" 2 "Torque control" 1 "Speed control" 0 "Override disabled" ;
VAL_ 2566766846 TransitRunStatus 3 "Not available" 2 "Error condition" 1 "On" 0 "Off" ;
VAL_ 2566766846 VehicleUseStatus 3 "Not available" 2 "Error condition" 1 "Unauthorized use" 0 "Normal use" ;
VAL_ 2566766846 SilentAlarmStatus 3 "Not available" 2 "Error condition" 1 "On" 0 "Off" ;
VAL_ 2566766846 TypeOfPassengerCount 255 "not available" 254 "error indicator" 4 "exiting passenger, second passenger stream)" 3 "boarding passenger, second passenger stream)" 2 "exiting passenger" 1 "boarding passenger" 0 "absolute passenger count" ;
VAL_ 2566765310 FareboxAlarmIdentifier 5 "Cashbox restored" 4 "Cashbox removed" 3 "Probe completed" 2 "Probe started" 1 "Voltage restored" 0 "Voltage dropout" 25 "Maintenance access out of service" 24 "Maintenance access in service" 23 "Paper currency jam cleared" 22 "Paper currency jam" 21 "Pass/transfer jam cleared" 20 "Pass/transfer jam" 19 "Farebox reset to automatic mode" 18 "Farebox set in manual bypass" 17 "Coin de-jam operated" 16 "Card/pass box full" 15 "Card/pass box less than 75% full" 14 "Card/pass box 75% full" 13 "Currency box full" 12 "Currency box less than 75% full" 11 "Currency box 75% full" 10 "Coinbox full" 9 "Coinbox 75% full" 8 "Insufficient fare accepted" 7 "Cashbox opened in service" 6 "Cashbox door timeout" ;
VAL_ 2566765310 FareboxEmergencyStatus 3 "Not available" 2 "Error Condition" 1 "Emergency condition" 0 "Non-emergency condition" ;
VAL_ 2566765566 TransferType 5 "Out" 4 "In" 3 "West" 2 "East" 1 "South" 0 "North" ;
VAL_ 2566765566 TypeOfService 1 "Express service" 0 "Local service" ;
VAL_ 2566765566 PaymentDetails 5 "Card" 4 "Pass" 3 "Ticket" 2 "Token" 1 "Cash" 0 "Not an upgrade" ;
VAL_ 2566765566 TypeOfFare 6 "Pass B" 5 "Pass A" 4 "Ticket B" 3 "Ticket A" 2 "Token B" 1 "Token A" 0 "Cash/No detail" ;
VAL_ 2566765566 TransactionType 7 "Free" 6 "Transfer" 5 "Permit" 4 "Card" 3 "Pass" 2 "Ticket" 1 "Token" 0 "Cash" ;
VAL_ 2566765822 TripDirection 5 "Out" 4 "In" 3 "West" 2 "East" 1 "South" 0 "North" ;
VAL_ 2566765822 TripStatus 7 "Undefined" 6 "Layover end" 5 "Layover start" 4 "Undefined" 3 "Undefined" 2 "Trip end" 1 "Trip start" 0 "Undefined" ;
VAL_ 2566765822 FareboxServiceStatus 3 "Not available" 2 "Error Condition" 1 "Farebox in service" 0 "Farebox out of service" ;
VAL_ 2566766078 StrobeActivationCtrlStatus 3 "Not available" 2 "Error condition" 1 "Activate strobe" 0 "Deactivate strobe" ;
VAL_ 2566766078 TransitDoorEnable 3 "Not available" 2 "Error condition" 1 "Transit door status will override strobe activation" 0 "Ignore transit door status" ;
VAL_ 2566766078 PriorityOfRespSentByEmitter 15 "Not available" 14 "Error condition" 11 "Priority set by hardware to high priority" 10 "Priority set by hardware to probe priority" 9 "Priority set by hardware to low priority" 3 "High priority" 2 "Probe priority" 1 "Low priority" 0 "Reserved" ;
VAL_ 2566766078 IntrsctnPrmptionRequest_Response 3 "Not available" 2 "Error condition" 1 "Message is a response from the emitter" 0 "Message is a request directed to the emitter" ;
VAL_ 2566766078 TransitRouteIDUsage 3 "Not available" 2 "Error condition" 1 "Transit route ID used for interleaved data" 0 "Transit route ID not used for interleaved data" ;
VAL_ 2566766078 RangeCodeEnable 3 "Not available" 2 "Error condition" 1 "Range code used for interleaved data" 0 "Range code not used for interleaved data" ;
VAL_ 2561605374 TireLocation 51 "Axle3_Position3" 50 "Axle3_Position2" 49 "Axle3_Position1" 35 "Axle2_Position3" 34 "Axle2_Position2" 33 "Axle2_Position1" 19 "Axle1_Position3" 18 "Axle1_Position2" 17 "Axle1_Position1" 1 "Axle0_Position1" 48 "Axle3_Position0" 32 "Axle2_Position0" 16 "Axle1_Position0" 0 "Axle0_Position0" ;
VAL_ 2566765054 TireLocation 51 "Axle3_Position3" 50 "Axle3_Position2" 49 "Axle3_Position1" 35 "Axle2_Position3" 34 "Axle2_Position2" 33 "Axle2_Position1" 19 "Axle1_Position3" 18 "Axle1_Position2" 17 "Axle1_Position1" 1 "Axle0_Position1" 48 "Axle3_Position0" 32 "Axle2_Position0" 16 "Axle1_Position0" 0 "Axle0_Position0" ;
VAL_ 2633922814 PCUTrilerTagOrPushSolenoidStatus 3 "Not available" 2 "Error" 1 "On" 0 "Off" ;
VAL_ 2633922814 PCUSupplySolenoidStatus 3 "Not available" 2 "Error" 1 "On" 0 "Off" ;
VAL_ 2633922814 PCUCtrlSolenoidStatus 3 "Not available" 2 "Error" 1 "On" 0 "Off" ;
VAL_ 2633922814 PCUDeflateSolenoidStatus 3 "Not available" 2 "Error" 1 "On" 0 "Off" ;
VAL_ 2633922814 TirePressSupplySwitchStatus 3 "Not available" 2 "Error" 1 "On" 0 "Off" ;
VAL_ 2633922814 PCUSteerSolenoidStatus 3 "Not available" 2 "Error" 1 "On" 0 "Off" ;
VAL_ 2633922814 PCUDriveSolenoidStatus 3 "Not available" 2 "Error" 1 "On" 0 "Off" ;
VAL_ 2633922814 DriveChannelMode 15 "Not available" 14 "Error Condition" 13 "Reserved" 12 "Reserved" 11 "Reserved" 10 "Reserved" 9 "Reserved" 8 "Reserved" 7 "Reserved" 6 "Pressure Check" 5 "Deflate Wait" 4 "Inflate Wait" 3 "Confirm" 2 "Deflate" 1 "Inflate" 0 "Maintain" ;
VAL_ 2633922814 Trailer_tagChannelMode 15 "Not available" 14 "Error Condition" 13 "Reserved" 12 "Reserved" 11 "Reserved" 10 "Reserved" 9 "Reserved" 8 "Reserved" 7 "Reserved" 6 "Pressure Check" 5 "Deflate Wait" 4 "Inflate Wait" 3 "Confirm" 2 "Deflate" 1 "Inflate" 0 "Maintain" ;
VAL_ 2633922814 SteerChannelMode 15 "Not available" 14 "Error Condition" 13 "Reserved" 12 "Reserved" 11 "Reserved" 10 "Reserved" 9 "Reserved" 8 "Reserved" 7 "Reserved" 6 "Pressure Check" 5 "Deflate Wait" 4 "Inflate Wait" 3 "Confirm" 2 "Deflate" 1 "Inflate" 0 "Maintain" ;
SG_MUL_VAL_ 2565734142 ToPort NetworkMessageControlByte 0-6, 131-133;
SG_MUL_VAL_ 2565734142 FilterMode NetworkMessageControlByte 1-1, 6-6;
SG_MUL_VAL_ 2565734142 NIECUPort NetworkMessageControlByte 64-67;
SG_MUL_VAL_ 2565734142 FromPort NetworkMessageControlByte 0-6, 131-133;
